VERSION ""

NS_ :

BS_:

BU_: APIM_CISM FCIMB RACM_RCIM DSP WCM DACMC HUD_ADV TRM_ITRM ACM GWM _delete APIM IPC GENERIC TSTR

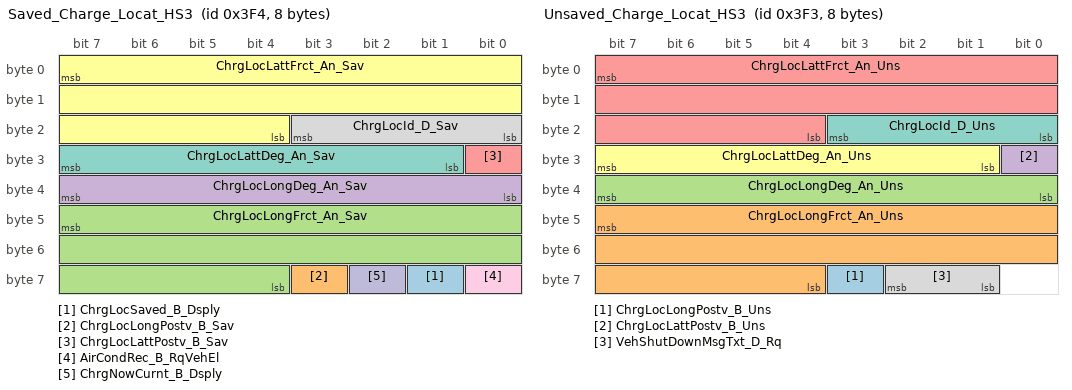
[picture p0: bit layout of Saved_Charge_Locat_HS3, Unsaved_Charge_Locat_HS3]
BO_ 1012 Saved_Charge_Locat_HS3: 8 GWM
 SG_ ChrgLocSaved_B_Dsply : 57|1@0+ (1,0) [0|1] "SED"  APIM,APIM_CISM
 SG_ ChrgLocLongPostv_B_Sav : 59|1@0+ (1,0) [0|1] "SED"  APIM_CISM,APIM
 SG_ ChrgLocLongFrct_An_Sav : 47|20@0+ (1E-006,0) [0|1.048575] "degrees"  APIM_CISM,APIM
 SG_ ChrgLocLongDeg_An_Sav : 39|8@0+ (1,0) [0|255] "degrees"  APIM_CISM,APIM
 SG_ ChrgLocLattPostv_B_Sav : 24|1@0+ (1,0) [0|1] "SED"  APIM_CISM,APIM
 SG_ ChrgLocLattFrct_An_Sav : 7|20@0+ (1E-006,0) [0|1.048575] "degrees"  APIM_CISM,APIM
 SG_ ChrgLocLattDeg_An_Sav : 31|7@0+ (1,0) [0|127] "unitless"  APIM_CISM,APIM
 SG_ ChrgLocId_D_Sav : 19|4@0+ (1,0) [0|15] "unitless"  APIM_CISM,APIM
 SG_ AirCondRec_B_RqVehEl : 56|1@0+ (1,0) [0|1] "SED"  GENERIC
 SG_ ChrgNowCurnt_B_Dsply : 58|1@0+ (1,0) [0|1] "SED"  IPC,APIM_CISM,APIM

BO_ 1011 Unsaved_Charge_Locat_HS3: 8 GWM
 SG_ ChrgLocLongPostv_B_Uns : 59|1@0+ (1,0) [0|1] "SED"  APIM_CISM,APIM
 SG_ ChrgLocLongFrct_An_Uns : 47|20@0+ (1E-006,0) [0|1.048575] "degrees"  APIM_CISM,APIM
 SG_ ChrgLocLongDeg_An_Uns : 39|8@0+ (1,0) [0|255] "degrees"  APIM_CISM,APIM
 SG_ ChrgLocLattPostv_B_Uns : 24|1@0+ (1,0) [0|1] "SED"  APIM_CISM,APIM
 SG_ ChrgLocLattFrct_An_Uns : 7|20@0+ (1E-006,0) [0|1.048575] "degrees"  APIM_CISM,APIM
 SG_ ChrgLocLattDeg_An_Uns : 31|7@0+ (1,0) [0|127] "unitless"  APIM_CISM,APIM
 SG_ ChrgLocId_D_Uns : 19|4@0+ (1,0) [0|15] "unitless"  APIM_CISM,APIM
 SG_ VehShutDownMsgTxt_D_Rq : 58|2@0+ (1,0) [0|3] "SED"  IPC

BO_ 533 APIM_Send_Signals_2: 8 APIM
 SG_ AutoEpbZoomView_B_Stat : 32|1@0+ (1,0) [0|1] "SED"  GWM
 SG_ ClrExitAsstEnbl_D_RqMnu : 60|2@0+ (1,0) [0|3] "SED"  GWM
 SG_ PaakMyKey_D_Rq : 7|2@0+ (1,0) [0|3] "SED"  GWM
 SG_ AutoEpbButtn_B_Stat : 19|1@0+ (1,0) [0|1] "SED"  GWM
 SG_ TrlrAidMde_D_Rq : 5|2@0+ (1,0) [0|3] "SED"  GWM
 SG_ TCU_Init_Actvtn_St : 1|2@0+ (1,0) [0|3] "SED"  GWM
 SG_ TCU_Final_Actvtn_St : 3|2@0+ (1,0) [0|3] "SED"  GWM
 SG_ DcacPw_D_Rq : 62|2@0+ (1,0) [0|3] "SED"  GWM
 SG_ DcacPwReset_B_Rq : 63|1@0+ (1,0) [0|1] "SED"  GWM
 SG_ LghtAmbDrvMde_D_Rq : 49|2@0+ (1,0) [0|3] "SED"  GWM
 SG_ OtaTrg_D_Stat : 41|2@0+ (1,0) [0|3] "SED"  GWM
 SG_ DcacPwLoButtn_B_Stat : 13|1@0+ (1,0) [0|1] "SED"  GWM
 SG_ DcacPwOffButtn_B_Stat : 12|1@0+ (1,0) [0|1] "SED"  GWM
 SG_ DcacPwHiButtn_B_Stat : 14|1@0+ (1,0) [0|1] "SED"  GWM
 SG_ DcacPwResetButtn_B_Stat : 11|1@0+ (1,0) [0|1] "SED"  GWM
 SG_ DcacPwButtn_B_Falt : 15|1@0+ (1,0) [0|1] "SED"  GWM
 SG_ OnbChrgGoTTouch_D_Rq : 43|2@0+ (1,0) [0|3] "SED"  GWM
 SG_ OnbChrgGoTPrcond_D_Rq : 34|2@0+ (1,0) [0|3] "SED"  GWM
 SG_ OnbChrgGoTOn_D_Rq : 25|2@0+ (1,0) [0|3] "SED"  GWM
 SG_ OnbChrgGoTMnte_D_Rq : 47|4@0+ (1,0) [0|15] "minute"  GWM
 SG_ OnbChrgGoTHr_T_Rq : 39|5@0+ (1,0) [0|29] "hour"  GWM
 SG_ OnbChrgGoTExtHtr_D_Rq : 27|2@0+ (1,0) [0|3] "SED"  GWM
 SG_ OnbChrgGoTElement_D_Rq : 31|4@0+ (1,0) [0|15] "Unitless"  GWM
 SG_ OnbChrgGoTDelete_B_Rq : 17|1@0+ (1,0) [0|1] "SED"  GWM
 SG_ OnbChrgClearAll_B_Rq : 18|1@0+ (1,0) [0|1] "SED"  GWM
 SG_ OnbChrgGoTUpdate_B_Rq : 16|1@0+ (1,0) [0|1] "SED"  GWM
 SG_ TrlrAlarmButtn_B_Stat : 50|1@0+ (1,0) [0|1] "SED"  TRM_ITRM,GWM
 SG_ DcacMdeButtn_B_Stat : 8|1@0+ (1,0) [0|1] "SED"  GWM
 SG_ DcacGfciTestBttn_B_Stat : 9|1@0+ (1,0) [0|1] "SED"  GWM
 SG_ TrlrBrkGain_No_Rq : 55|5@0+ (0.5,0) [0|15.5] "unitless"  TRM_ITRM,GWM
 SG_ TrlrHitch_D_RqMnu : 23|4@0+ (1,0) [0|15] "SED"  GWM
 SG_ DcacPwButtn_B_Stat : 10|1@0+ (1,0) [0|1] "SED"  GWM

BO_ 1184 APIM_TCU_Word_Rx_HS3: 8 GWM
 SG_ APIM_TCU_Word_Rx : 7|64@0+ (1,0) [0|1.84467440737096E+019] "unitless"  APIM_CISM,APIM

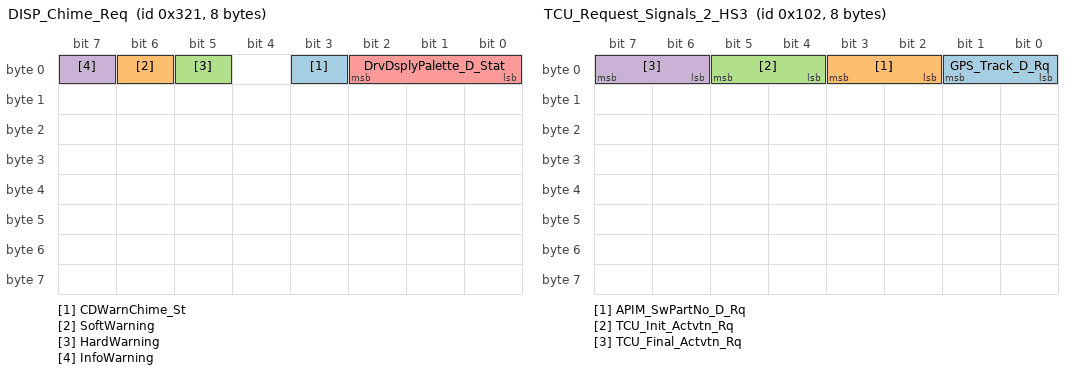
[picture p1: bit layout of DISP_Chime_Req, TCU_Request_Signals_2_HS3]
BO_ 801 DISP_Chime_Req: 8 APIM
 SG_ CDWarnChime_St : 3|1@0+ (1,0) [0|1] "SED"  IPC
 SG_ SoftWarning : 6|1@0+ (1,0) [0|1] "SED"  IPC
 SG_ HardWarning : 5|1@0+ (1,0) [0|1] "SED"  IPC
 SG_ InfoWarning : 7|1@0+ (1,0) [0|1] "SED"  IPC
 SG_ DrvDsplyPalette_D_Stat : 2|3@0+ (1,0) [0|7] "SED"  IPC

BO_ 878 Rear_Climate_Data2: 8 RACM_RCIM
 SG_ ClimtSyncRear2_B_Stat : 58|1@0+ (1,0) [0|1] "SED"  GENERIC,GWM
 SG_ ClimtStHeatRr2_B_Stat : 54|1@0+ (1,0) [0|1] "SED"  GENERIC,GWM
 SG_ ClimtStHeatRl2_B_Stat : 55|1@0+ (1,0) [0|1] "SED"  GENERIC,GWM
 SG_ ClimtStCoolRr2_B_Stat : 52|1@0+ (1,0) [0|1] "SED"  GENERIC,GWM
 SG_ ClimtStCoolRl2_B_Stat : 53|1@0+ (1,0) [0|1] "SED"  GENERIC,GWM
 SG_ ClimtSeatRr2_D_Rq : 39|8@0+ (1,0) [0|64] "SED"  GENERIC,GWM
 SG_ ClimtSeatRl2_D_Rq : 47|8@0+ (1,0) [0|64] "SED"  GENERIC,GWM
 SG_ ClimtRrTe3rd2_D_Stat : 51|2@0+ (1,0) [0|3] "SED"  GENERIC,GWM
 SG_ ClimtRrPw3rd2_B_Stat : 59|1@0+ (1,0) [0|1] "SED"  GENERIC,GWM
 SG_ ClimtRrPnl3rd2_B_Stat : 62|1@0+ (1,0) [0|1] "SED"  GENERIC,GWM
 SG_ ClimtRrPf3rd2_B_Stat : 63|1@0+ (1,0) [0|1] "SED"  GENERIC,GWM
 SG_ ClimtRrFlr3rd2_B_Stat : 61|1@0+ (1,0) [0|1] "SED"  GENERIC,GWM
 SG_ ClimtRrBlwr3rd2_D_Stat : 49|2@0+ (1,0) [0|3] "SED"  GENERIC,GWM
 SG_ ClimtRrAuto3rd2_B_Stat : 60|1@0+ (1,0) [0|1] "SED"  GENERIC,GWM
 SG_ ClimtRearView2_D_Stat : 57|2@0+ (1,0) [0|3] "SED"  GENERIC,GWM
 SG_ ClimtRearTe2_D_Stat : 11|2@0+ (1,0) [0|3] "SED"  GENERIC,GWM
 SG_ ClimtRearTe2_An_Actl : 7|9@0+ (1,0) [0|510] "degrees"  GENERIC,GWM
 SG_ ClimtRearPw2_B_Stat : 29|1@0+ (1,0) [0|1] "SED"  GENERIC,GWM
 SG_ ClimtRearPnlFlr2_B_Stat : 13|1@0+ (1,0) [0|1] "SED"  GENERIC,GWM
 SG_ ClimtRearPnl2_B_Stat : 14|1@0+ (1,0) [0|1] "SED"  GENERIC,GWM
 SG_ ClimtRearFlr2_B_Stat : 12|1@0+ (1,0) [0|1] "SED"  GENERIC,GWM
 SG_ ClimtRearBlwr2_D_Stat : 9|2@0+ (1,0) [0|3] "SED"  GENERIC,GWM
 SG_ ClimtRearBlwr2_An_Actl : 23|9@0+ (1,0) [0|510] "degrees"  GENERIC,GWM
 SG_ ClimtRearAuto2_B_Stat : 30|1@0+ (1,0) [0|1] "SED"  GENERIC,GWM

BO_ 258 TCU_Request_Signals_2_HS3: 8 GWM
 SG_ GPS_Track_D_Rq : 1|2@0+ (1,0) [0|3] "SED"  APIM_CISM,APIM
 SG_ APIM_SwPartNo_D_Rq : 3|2@0+ (1,0) [0|3] "SED"  APIM_CISM,APIM
 SG_ TCU_Init_Actvtn_Rq : 5|2@0+ (1,0) [0|3] "SED"  APIM_CISM,APIM
 SG_ TCU_Final_Actvtn_Rq : 7|2@0+ (1,0) [0|3] "SED"  APIM_CISM,APIM

BO_ 1192 APIM_TCU_Word_Tx: 8 APIM
 SG_ APIM_TCU_Word_Tx : 7|64@0+ (1,0) [0|1.84467440737096E+019] "unitless"  GWM

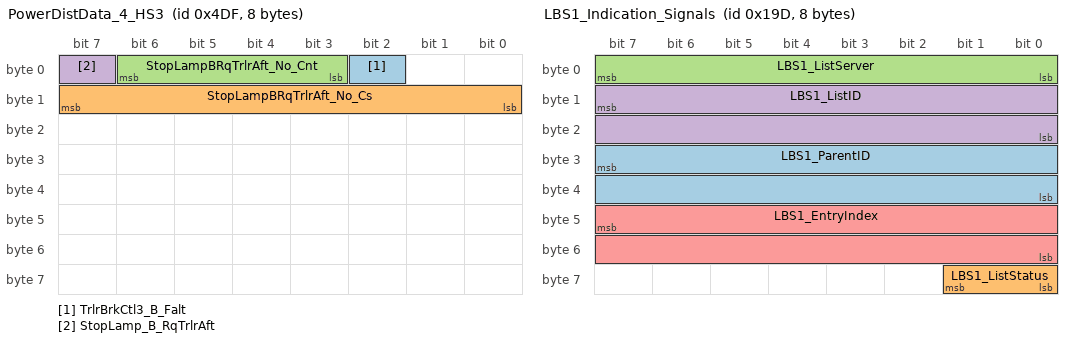
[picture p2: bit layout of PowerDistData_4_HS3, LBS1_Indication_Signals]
BO_ 1247 PowerDistData_4_HS3: 8 GWM
 SG_ TrlrBrkCtl3_B_Falt : 2|1@0+ (1,0) [0|1] "SED"  TRM_ITRM
 SG_ StopLampBRqTrlrAft_No_Cs : 15|8@0+ (1,0) [0|255] "Unitless"  TRM_ITRM
 SG_ StopLampBRqTrlrAft_No_Cnt : 6|4@0+ (1,0) [0|15] "Unitless"  TRM_ITRM
 SG_ StopLamp_B_RqTrlrAft : 7|1@0+ (1,0) [0|1] "SED"  TRM_ITRM

BO_ 413 LBS1_Indication_Signals: 8 APIM
 SG_ LBS1_ParentID : 31|16@0+ (1,0) [0|65535] "unitless"  RACM_RCIM,IPC
 SG_ LBS1_ListStatus : 57|2@0+ (1,0) [0|3] "SED"  IPC,RACM_RCIM
 SG_ LBS1_ListServer : 7|8@0+ (1,0) [0|255] "unitless"  IPC,RACM_RCIM
 SG_ LBS1_ListID : 15|16@0+ (1,0) [0|65535] "unitless"  IPC,RACM_RCIM
 SG_ LBS1_EntryIndex : 47|16@0+ (1,0) [0|65535] "unitless"  IPC,RACM_RCIM

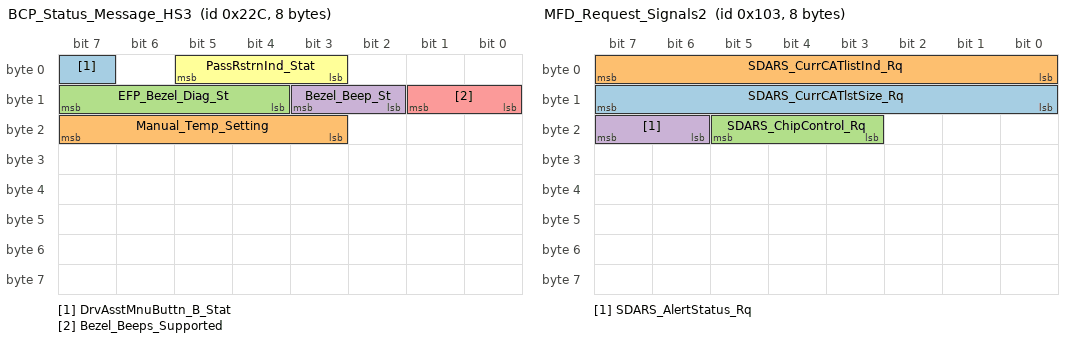
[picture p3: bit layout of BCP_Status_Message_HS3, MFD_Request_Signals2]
BO_ 556 BCP_Status_Message_HS3: 8 GWM
 SG_ DrvAsstMnuButtn_B_Stat : 7|1@0+ (1,0) [0|1] "SED"  APIM_CISM,APIM
 SG_ Manual_Temp_Setting : 23|5@0+ (1,0) [0|31] "SED"  APIM,APIM_CISM
 SG_ EFP_Bezel_Diag_St : 15|4@0+ (1,0) [0|15] "SED"  APIM,APIM_CISM
 SG_ Bezel_Beep_St : 11|2@0+ (1,0) [0|3] "SED"  APIM,APIM_CISM
 SG_ Bezel_Beeps_Supported : 9|2@0+ (1,0) [0|3] "SED"  APIM,APIM_CISM
 SG_ PassRstrnInd_Stat : 5|3@0+ (1,0) [0|7] "SED"  GENERIC

BO_ 259 MFD_Request_Signals2: 8 APIM
 SG_ SDARS_CurrCATlstSize_Rq : 15|8@0+ (1,0) [0|255] "unitless"  ACM
 SG_ SDARS_CurrCATlistInd_Rq : 7|8@0+ (1,0) [0|255] "unitless"  ACM
 SG_ SDARS_ChipControl_Rq : 21|3@0+ (1,0) [0|7] "SED"  ACM
 SG_ SDARS_AlertStatus_Rq : 23|2@0+ (1,0) [0|3] "SED"  ACM

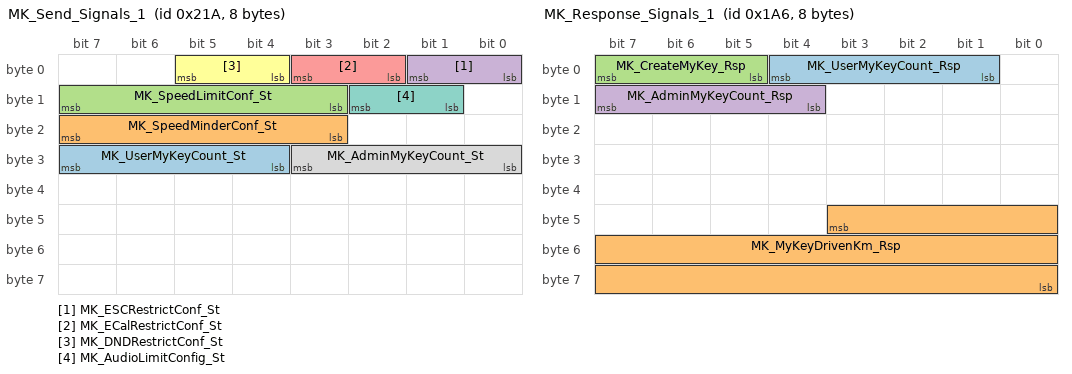
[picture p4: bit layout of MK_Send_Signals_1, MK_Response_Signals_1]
BO_ 538 MK_Send_Signals_1: 8 IPC
 SG_ MK_UserMyKeyCount_St : 31|4@0+ (1,0) [0|13] "SED"  APIM_CISM,APIM
 SG_ MK_SpeedMinderConf_St : 23|5@0+ (1,0) [0|31] "SED"  APIM_CISM,APIM
 SG_ MK_SpeedLimitConf_St : 15|5@0+ (1,0) [0|31] "SED"  APIM_CISM,APIM
 SG_ MK_ESCRestrictConf_St : 1|2@0+ (1,0) [0|3] "SED"  APIM_CISM,GENERIC
 SG_ MK_ECalRestrictConf_St : 3|2@0+ (1,0) [0|3] "SED"  APIM_CISM,APIM
 SG_ MK_DNDRestrictConf_St : 5|2@0+ (1,0) [0|3] "SED"  APIM_CISM,APIM
 SG_ MK_AudioLimitConfig_St : 10|2@0+ (1,0) [0|3] "SED"  APIM_CISM,APIM
 SG_ MK_AdminMyKeyCount_St : 27|4@0+ (1,0) [0|13] "SED"  APIM_CISM,APIM

BO_ 422 MK_Response_Signals_1: 8 IPC
 SG_ MK_UserMyKeyCount_Rsp : 4|4@0+ (1,0) [0|15] "SED"  APIM_CISM,APIM
 SG_ MK_MyKeyDrivenKm_Rsp : 43|20@0+ (1,0) [0|1048575] "km"  APIM_CISM,APIM
 SG_ MK_CreateMyKey_Rsp : 7|3@0+ (1,0) [0|7] "SED"  APIM_CISM,APIM
 SG_ MK_AdminMyKeyCount_Rsp : 15|4@0+ (1,0) [0|15] "SED"  APIM_CISM,APIM

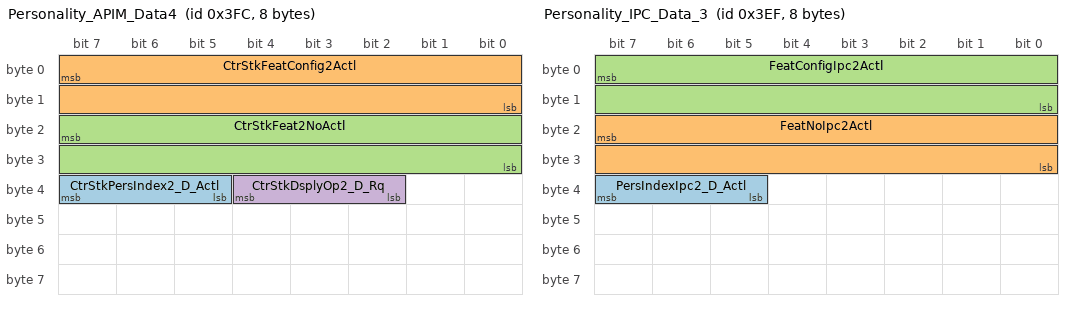
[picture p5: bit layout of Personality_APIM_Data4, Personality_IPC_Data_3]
BO_ 1020 Personality_APIM_Data4: 8 APIM
 SG_ CtrStkPersIndex2_D_Actl : 39|3@0+ (1,0) [0|7] "SED"  IPC
 SG_ CtrStkFeatConfig2Actl : 7|16@0+ (1,0) [0|65535] "Undefined"  IPC
 SG_ CtrStkFeat2NoActl : 23|16@0+ (1,0) [0|65535] "Undefined"  IPC
 SG_ CtrStkDsplyOp2_D_Rq : 36|3@0+ (1,0) [0|7] "SED"  IPC

BO_ 1007 Personality_IPC_Data_3: 8 IPC
 SG_ PersIndexIpc2_D_Actl : 39|3@0+ (1,0) [0|7] "SED"  APIM,APIM_CISM
 SG_ FeatNoIpc2Actl : 23|16@0+ (1,0) [0|65535] "Number"  APIM,APIM_CISM
 SG_ FeatConfigIpc2Actl : 7|16@0+ (1,0) [0|65535] "unitless"  APIM,APIM_CISM

BO_ 2008 TesterPhysicalResAPIM: 8 APIM
 SG_ TesterPhysicalResAPIM : 7|64@0+ (1,0) [0|1.84467E+019] "unitless"  TSTR

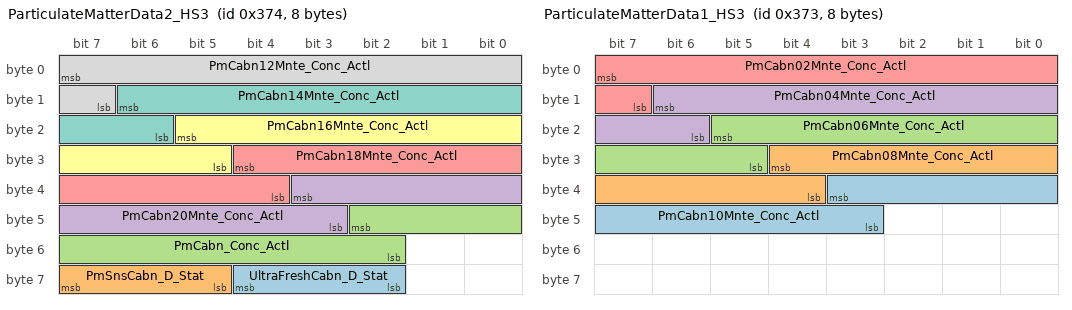
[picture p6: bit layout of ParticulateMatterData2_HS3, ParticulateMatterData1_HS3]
BO_ 884 ParticulateMatterData2_HS3: 8 GWM
 SG_ UltraFreshCabn_D_Stat : 60|3@0+ (1,0) [0|7] "SED"  APIM_CISM,GENERIC
 SG_ PmSnsCabn_D_Stat : 63|3@0+ (1,0) [0|7] "SED"  APIM_CISM,APIM,RACM_RCIM
 SG_ PmCabn_Conc_Actl : 42|9@0+ (1,0) [0|509] "parts/million"  APIM_CISM,APIM,RACM_RCIM
 SG_ PmCabn20Mnte_Conc_Actl : 35|9@0+ (1,0) [0|509] "parts/million"  RACM_RCIM,APIM_CISM,APIM
 SG_ PmCabn18Mnte_Conc_Actl : 28|9@0+ (1,0) [0|509] "parts/million"  RACM_RCIM,APIM_CISM,APIM
 SG_ PmCabn16Mnte_Conc_Actl : 21|9@0+ (1,0) [0|509] "parts/million"  RACM_RCIM,APIM_CISM,APIM
 SG_ PmCabn14Mnte_Conc_Actl : 14|9@0+ (1,0) [0|509] "parts/million"  RACM_RCIM,APIM_CISM,APIM
 SG_ PmCabn12Mnte_Conc_Actl : 7|9@0+ (1,0) [0|509] "parts/million"  RACM_RCIM,APIM_CISM,APIM

BO_ 883 ParticulateMatterData1_HS3: 8 GWM
 SG_ PmCabn10Mnte_Conc_Actl : 35|9@0+ (1,0) [0|509] "parts/million"  RACM_RCIM,APIM_CISM,APIM
 SG_ PmCabn08Mnte_Conc_Actl : 28|9@0+ (1,0) [0|509] "parts/million"  RACM_RCIM,APIM_CISM,APIM
 SG_ PmCabn06Mnte_Conc_Actl : 21|9@0+ (1,0) [0|509] "parts/million"  RACM_RCIM,APIM_CISM,APIM
 SG_ PmCabn04Mnte_Conc_Actl : 14|9@0+ (1,0) [0|509] "parts/million"  RACM_RCIM,APIM_CISM,APIM
 SG_ PmCabn02Mnte_Conc_Actl : 7|9@0+ (1,0) [0|509] "parts/million"  RACM_RCIM,APIM_CISM,APIM

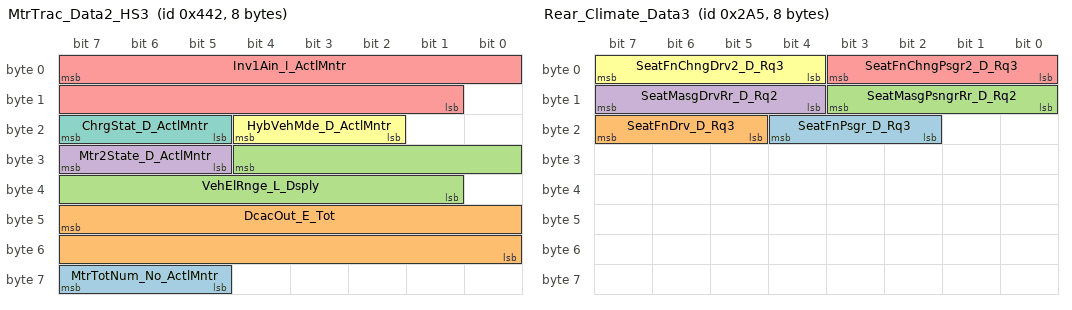
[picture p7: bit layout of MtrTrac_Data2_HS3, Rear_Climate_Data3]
BO_ 1090 MtrTrac_Data2_HS3: 8 GWM
 SG_ MtrTotNum_No_ActlMntr : 63|3@0+ (1,0) [0|7] "unitless"  GENERIC
 SG_ DcacOut_E_Tot : 47|16@0+ (20,0) [0|1310700] "watt*hour"  APIM,APIM_CISM
 SG_ VehElRnge_L_Dsply : 28|12@0+ (0.1,0) [0|409.3] "kilometer"  APIM_CISM,APIM,HUD_ADV,IPC
 SG_ Mtr2State_D_ActlMntr : 31|3@0+ (1,0) [0|7] "SED" Vector__XXX
 SG_ Inv1Ain_I_ActlMntr : 7|15@0+ (0.1,-1000) [-1000|2276.5] "ampere"  GENERIC
 SG_ HybVehMde_D_ActlMntr : 20|3@0+ (1,0) [0|7] "SED"  GENERIC
 SG_ ChrgStat_D_ActlMntr : 23|3@0+ (1,0) [0|7] "SED"  GENERIC

BO_ 677 Rear_Climate_Data3: 8 RACM_RCIM
 SG_ SeatFnPsgr_D_Rq3 : 20|3@0+ (1,0) [0|7] "SED"  GWM
 SG_ SeatFnDrv_D_Rq3 : 23|3@0+ (1,0) [0|7] "SED"  GWM
 SG_ SeatMasgPsngrRr_D_Rq2 : 11|4@0+ (1,0) [0|15] "SED"  GWM
 SG_ SeatMasgDrvRr_D_Rq2 : 15|4@0+ (1,0) [0|15] "SED"  GWM
 SG_ SeatFnChngPsgr2_D_Rq3 : 3|4@0+ (1,0) [0|15] "SED"  GWM
 SG_ SeatFnChngDrv2_D_Rq3 : 7|4@0+ (1,0) [0|15] "SED"  GWM

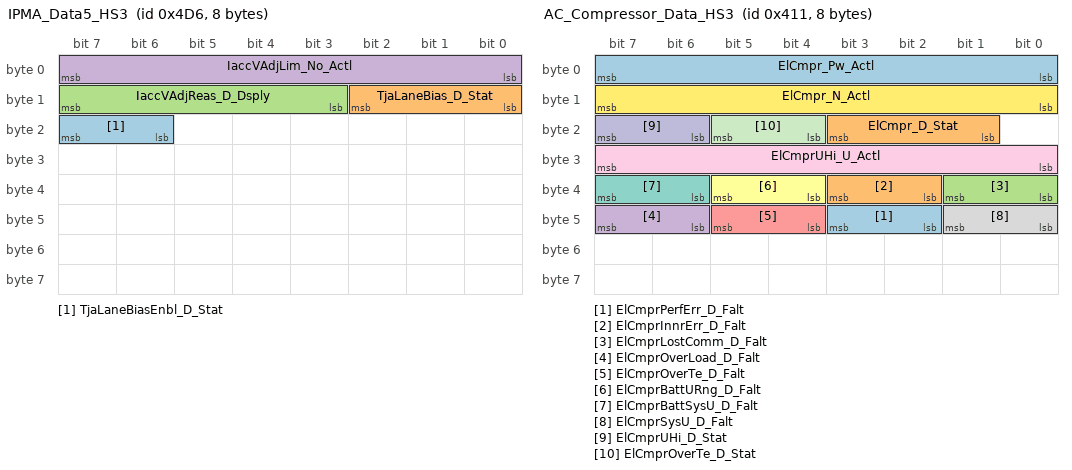
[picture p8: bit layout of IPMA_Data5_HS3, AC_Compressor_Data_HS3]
BO_ 1238 IPMA_Data5_HS3: 8 GWM
 SG_ TjaLaneBiasEnbl_D_Stat : 23|2@0+ (1,0) [0|3] "SED"  APIM,APIM_CISM
 SG_ TjaLaneBias_D_Stat : 10|3@0+ (1,0) [0|7] "SED"  IPC
 SG_ IaccVAdjReas_D_Dsply : 15|5@0+ (1,0) [0|31] "SED"  APIM,APIM_CISM,IPC
 SG_ IaccVAdjLim_No_Actl : 7|8@0+ (1,0) [0|255] "unitless"  APIM,APIM_CISM,IPC

BO_ 1041 AC_Compressor_Data_HS3: 8 GWM
 SG_ ElCmprPerfErr_D_Falt : 43|2@0+ (1,0) [0|3] "SED" Vector__XXX
 SG_ ElCmprInnrErr_D_Falt : 35|2@0+ (1,0) [0|3] "SED" Vector__XXX
 SG_ ElCmprLostComm_D_Falt : 33|2@0+ (1,0) [0|3] "SED" Vector__XXX
 SG_ ElCmprOverLoad_D_Falt : 47|2@0+ (1,0) [0|3] "SED" Vector__XXX
 SG_ ElCmprOverTe_D_Falt : 45|2@0+ (1,0) [0|3] "SED" Vector__XXX
 SG_ ElCmprBattURng_D_Falt : 37|2@0+ (1,0) [0|3] "SED" Vector__XXX
 SG_ ElCmprBattSysU_D_Falt : 39|2@0+ (1,0) [0|3] "SED" Vector__XXX
 SG_ ElCmprSysU_D_Falt : 41|2@0+ (1,0) [0|3] "SED" Vector__XXX
 SG_ ElCmprUHi_U_Actl : 31|8@0+ (2,0) [0|510] "volt" Vector__XXX
 SG_ ElCmprUHi_D_Stat : 23|2@0+ (1,0) [0|3] "SED" Vector__XXX
 SG_ ElCmprOverTe_D_Stat : 21|2@0+ (1,0) [0|3] "SED" Vector__XXX
 SG_ ElCmpr_N_Actl : 15|8@0+ (50,0) [0|12700] "RPM"  WCM
 SG_ ElCmpr_Pw_Actl : 7|8@0+ (40,0) [0|10160] "watts" Vector__XXX
 SG_ ElCmpr_D_Stat : 19|3@0+ (1,0) [0|7] "SED" Vector__XXX

BO_ 2609971416 OTAPhysGWM_ECGtoWCM: 8 GWM
 SG_ OTAPhysGWM_ECGtoWCM : 7|29@0+ (1,0) [0|536870911] "unitless"  WCM

BO_ 2610126912 OTAPhysWCMtoGWM_ECG: 8 WCM
 SG_ OTAPhysWCMtoGWM_ECG : 7|29@0+ (1,0) [0|536870911] "unitless"  GWM

BO_ 2611019992 PARSEDPhysGWM_ECGtoWCM: 8 GWM
 SG_ PARSEDPhysGWM_ECGtoWCM : 7|29@0+ (1,0) [0|536870911] "unitless"  WCM

BO_ 2611175488 PARSEDPhysWCMtoGWM_ECG: 8 WCM
 SG_ PARSEDPhysWCMtoGWM_ECG : 7|29@0+ (1,0) [0|536870911] "unitless"  GWM

BO_ 2612068568 PARSEDPushFcGWM_ECGtoWCM: 8 GWM
 SG_ PARSEDPushFcGWM_ECGtoWCM : 7|29@0+ (1,0) [0|536870911] "unitless"  WCM

BO_ 2612224064 PARSEDPushWCMtoGWM_ECG: 8 WCM
 SG_ PARSEDPushWCMtoGWM_ECG : 7|29@0+ (1,0) [0|536870911] "unitless"  GWM

BO_ 557 DSPAMP_Send_Signals_2: 8 DSP
 SG_ AudioToneTouchY_D_Stat : 15|8@0+ (1,0) [0|255] "SED"  APIM_CISM,APIM
 SG_ AudioToneTouchX_D_Stat : 7|8@0+ (1,0) [0|255] "SED"  APIM_CISM,APIM
 SG_ AudioToneTouch_D_Stat : 23|2@0+ (1,0) [0|3] "SED"  APIM_CISM,APIM

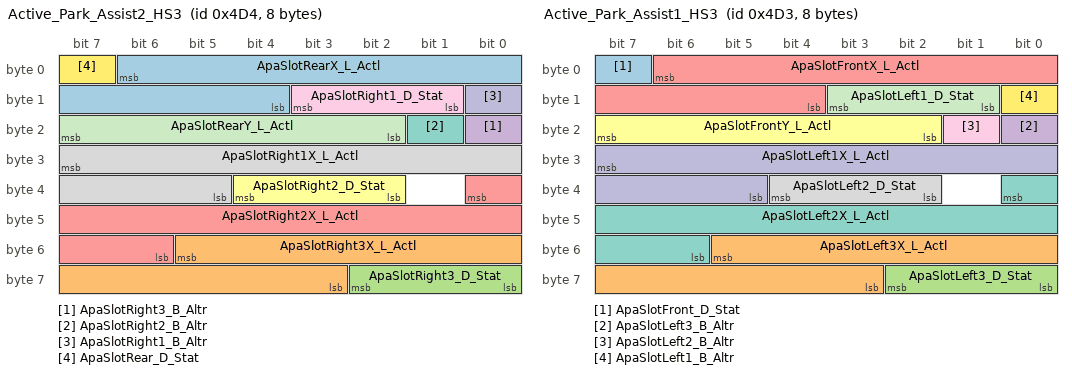
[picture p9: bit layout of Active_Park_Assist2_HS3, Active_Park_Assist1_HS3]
BO_ 1236 Active_Park_Assist2_HS3: 8 GWM
 SG_ ApaSlotRearX_L_Actl : 6|11@0+ (0.02,-20.96) [-20.96|19.98] "meter"  APIM_CISM,APIM
 SG_ ApaSlotRight3X_L_Actl : 53|11@0+ (0.02,-20.96) [-20.96|19.98] "meter"  APIM_CISM,APIM
 SG_ ApaSlotRight3_D_Stat : 58|3@0+ (1,0) [0|7] "SED"  APIM_CISM,APIM
 SG_ ApaSlotRight3_B_Altr : 16|1@0+ (1,0) [0|1] "SED"  APIM_CISM,APIM
 SG_ ApaSlotRight2X_L_Actl : 32|11@0+ (0.02,-20.96) [-20.96|19.98] "meter"  APIM_CISM,APIM
 SG_ ApaSlotRight2_D_Stat : 36|3@0+ (1,0) [0|7] "SED"  APIM_CISM,APIM
 SG_ ApaSlotRight2_B_Altr : 17|1@0+ (1,0) [0|1] "SED"  APIM_CISM,APIM
 SG_ ApaSlotRight1X_L_Actl : 31|11@0+ (0.02,-20.96) [-20.96|19.98] "meter"  APIM_CISM,APIM
 SG_ ApaSlotRight1_D_Stat : 11|3@0+ (1,0) [0|7] "SED"  APIM_CISM,APIM
 SG_ ApaSlotRight1_B_Altr : 8|1@0+ (1,0) [0|1] "SED"  APIM_CISM,APIM
 SG_ ApaSlotRearY_L_Actl : 23|6@0+ (0.2,-6.4) [-6.4|6.2] "meter"  APIM_CISM,APIM
 SG_ ApaSlotRear_D_Stat : 7|1@0+ (1,0) [0|1] "SED"  APIM_CISM,APIM

BO_ 1235 Active_Park_Assist1_HS3: 8 GWM
 SG_ ApaSlotFront_D_Stat : 7|1@0+ (1,0) [0|1] "SED"  APIM_CISM,APIM
 SG_ ApaSlotLeft3X_L_Actl : 53|11@0+ (0.02,-20.96) [-20.96|19.98] "meter"  APIM_CISM,APIM
 SG_ ApaSlotLeft3_D_Stat : 58|3@0+ (1,0) [0|7] "SED"  APIM_CISM,APIM
 SG_ ApaSlotLeft3_B_Altr : 16|1@0+ (1,0) [0|1] "SED"  APIM_CISM,APIM
 SG_ ApaSlotFrontX_L_Actl : 6|11@0+ (0.02,-20.96) [-20.96|19.98] "meter"  APIM_CISM,APIM
 SG_ ApaSlotFrontY_L_Actl : 23|6@0+ (0.2,-6.4) [-6.4|6.2] "meter"  APIM_CISM,APIM
 SG_ ApaSlotLeft2X_L_Actl : 32|11@0+ (0.02,-20.96) [-20.96|19.98] "meter"  APIM_CISM,APIM
 SG_ ApaSlotLeft2_D_Stat : 36|3@0+ (1,0) [0|7] "SED"  APIM_CISM,APIM
 SG_ ApaSlotLeft2_B_Altr : 17|1@0+ (1,0) [0|1] "SED"  APIM_CISM,APIM
 SG_ ApaSlotLeft1X_L_Actl : 31|11@0+ (0.02,-20.96) [-20.96|19.98] "meter"  APIM_CISM,APIM
 SG_ ApaSlotLeft1_D_Stat : 11|3@0+ (1,0) [0|7] "SED"  APIM_CISM,APIM
 SG_ ApaSlotLeft1_B_Altr : 8|1@0+ (1,0) [0|1] "SED"  APIM_CISM,APIM

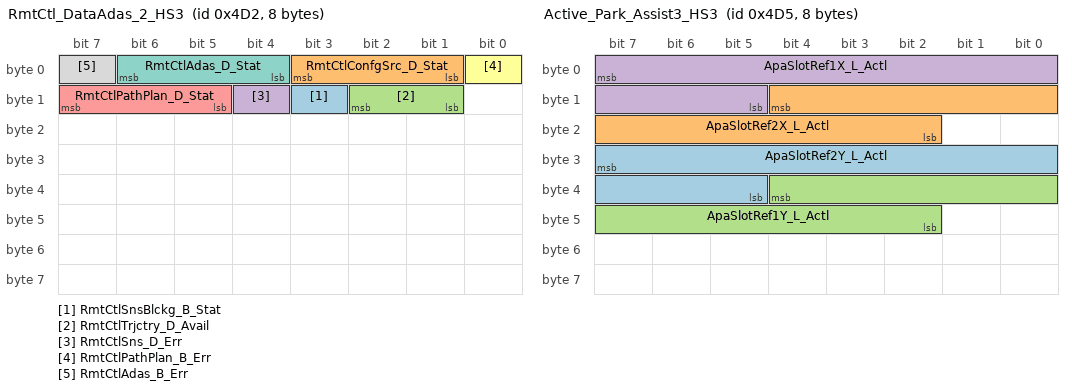
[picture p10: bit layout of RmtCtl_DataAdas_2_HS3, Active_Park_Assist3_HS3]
BO_ 1234 RmtCtl_DataAdas_2_HS3: 8 GWM
 SG_ RmtCtlSnsBlckg_B_Stat : 11|1@0+ (1,0) [0|1] "SED"  GENERIC
 SG_ RmtCtlConfgSrc_D_Stat : 3|3@0+ (1,0) [0|7] "SED"  GENERIC
 SG_ RmtCtlTrjctry_D_Avail : 10|2@0+ (1,0) [0|3] "SED"  GENERIC
 SG_ RmtCtlSns_D_Err : 12|1@0+ (1,0) [0|1] "SED"  GENERIC
 SG_ RmtCtlPathPlan_D_Stat : 15|3@0+ (1,0) [0|7] "SED"  GENERIC
 SG_ RmtCtlPathPlan_B_Err : 0|1@0+ (1,0) [0|1] "SED"  GENERIC
 SG_ RmtCtlAdas_D_Stat : 6|3@0+ (1,0) [0|7] "SED"  GENERIC
 SG_ RmtCtlAdas_B_Err : 7|1@0+ (1,0) [0|1] "SED"  GENERIC

BO_ 1237 Active_Park_Assist3_HS3: 8 GWM
 SG_ ApaSlotRef2Y_L_Actl : 31|11@0+ (0.02,-20.96) [-20.96|19.98] "meter"  APIM_CISM,APIM
 SG_ ApaSlotRef2X_L_Actl : 12|11@0+ (0.02,-20.96) [-20.96|19.98] "meter"  APIM_CISM,APIM
 SG_ ApaSlotRef1Y_L_Actl : 36|11@0+ (0.02,-20.96) [-20.96|19.98] "meter"  APIM_CISM,APIM
 SG_ ApaSlotRef1X_L_Actl : 7|11@0+ (0.02,-20.96) [-20.96|19.98] "meter"  APIM_CISM,APIM

BO_ 976 VehCharacteristicSet2_HS3: 8 GWM
 SG_ VehLong2_A_Actl_UB : 34|1@0+ (1,0) [0|1] "SED"  APIM_CISM,ACM
 SG_ VehLong2_A_Actl : 52|13@0+ (0.01,-40) [-40|41.89] "m/s^2"  APIM_CISM,ACM

BO_ 715 SSPClnt_SSPSrv_WORD_Rx: 8 APIM
 SG_ RDISP_SSP_WORD_Rx : 7|64@0+ (1,0) [0|1.84467440737096E+019] "unitless"  ACM

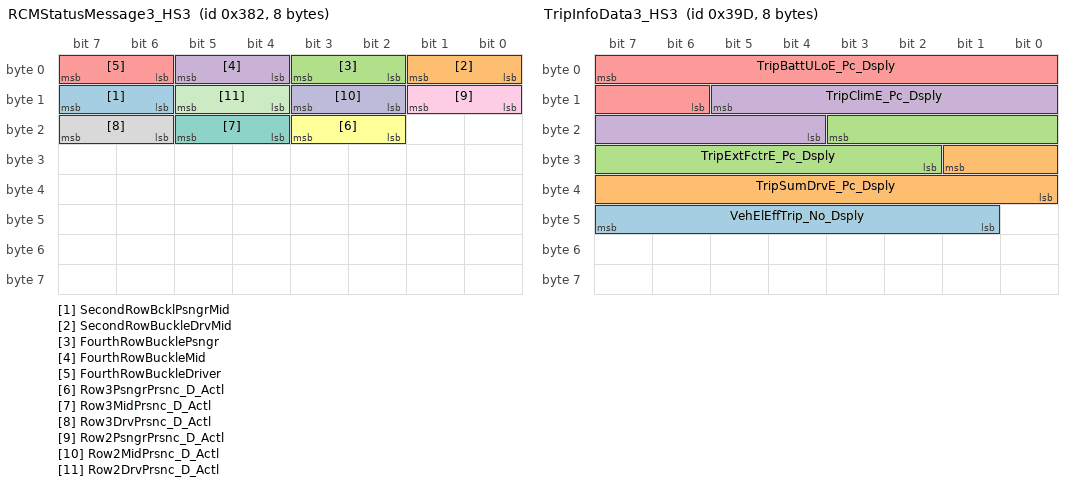
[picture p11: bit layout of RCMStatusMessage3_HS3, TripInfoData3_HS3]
BO_ 898 RCMStatusMessage3_HS3: 8 GWM
 SG_ SecondRowBcklPsngrMid : 15|2@0+ (1,0) [0|3] "SED"  IPC
 SG_ SecondRowBuckleDrvMid : 1|2@0+ (1,0) [0|3] "SED"  IPC
 SG_ FourthRowBucklePsngr : 3|2@0+ (1,0) [0|3] "SED"  IPC
 SG_ FourthRowBuckleMid : 5|2@0+ (1,0) [0|3] "SED"  IPC
 SG_ FourthRowBuckleDriver : 7|2@0+ (1,0) [0|3] "SED"  IPC
 SG_ Row3PsngrPrsnc_D_Actl : 19|2@0+ (1,0) [0|3] "SED"  IPC,APIM
 SG_ Row3MidPrsnc_D_Actl : 21|2@0+ (1,0) [0|3] "SED"  IPC,APIM
 SG_ Row3DrvPrsnc_D_Actl : 23|2@0+ (1,0) [0|3] "SED"  IPC,APIM
 SG_ Row2PsngrPrsnc_D_Actl : 9|2@0+ (1,0) [0|3] "SED"  IPC,APIM
 SG_ Row2MidPrsnc_D_Actl : 11|2@0+ (1,0) [0|3] "SED"  IPC,APIM
 SG_ Row2DrvPrsnc_D_Actl : 13|2@0+ (1,0) [0|3] "SED"  IPC,APIM

BO_ 925 TripInfoData3_HS3: 8 GWM
 SG_ VehElEffTrip_No_Dsply : 47|7@0+ (10,-100) [-100|1150] "wattHr/km"  APIM,IPC,APIM_CISM
 SG_ TripSumDrvE_Pc_Dsply : 25|10@0+ (0.1,0) [0|102.1] "percent"  APIM_CISM,APIM,IPC
 SG_ TripExtFctrE_Pc_Dsply : 19|10@0+ (0.1,0) [0|102.1] "percent"  APIM_CISM,APIM,IPC
 SG_ TripClimE_Pc_Dsply : 13|10@0+ (0.1,0) [0|102.1] "percent"  APIM_CISM,APIM,IPC
 SG_ TripBattULoE_Pc_Dsply : 7|10@0+ (0.1,0) [0|102.1] "percent"  APIM_CISM,APIM,IPC

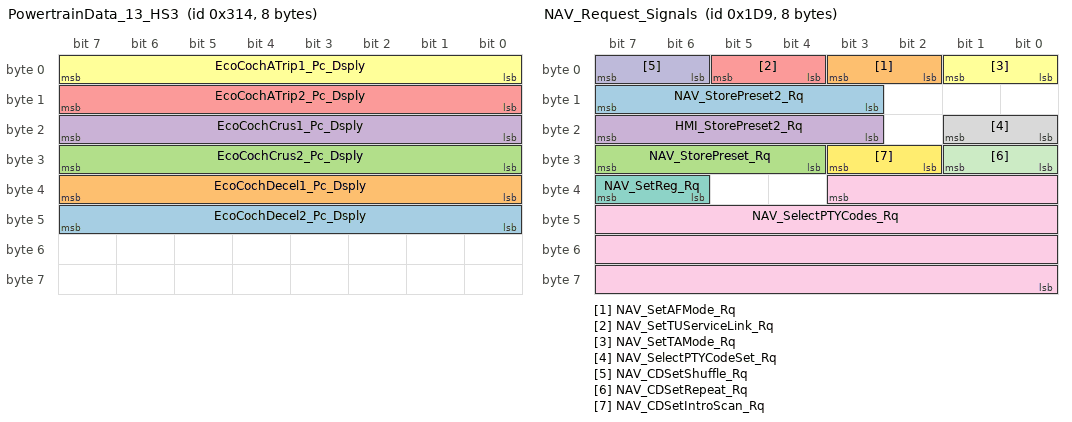
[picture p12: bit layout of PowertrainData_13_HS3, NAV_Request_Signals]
BO_ 788 PowertrainData_13_HS3: 8 GWM
 SG_ EcoCochDecel2_Pc_Dsply : 47|8@0+ (0.392157,0) [0|100.000035] "percent"  APIM_CISM,APIM
 SG_ EcoCochDecel1_Pc_Dsply : 39|8@0+ (0.392157,0) [0|100.000035] "percent"  APIM_CISM,APIM
 SG_ EcoCochCrus2_Pc_Dsply : 31|8@0+ (0.392157,0) [0|100.000035] "percent"  APIM_CISM,APIM
 SG_ EcoCochCrus1_Pc_Dsply : 23|8@0+ (0.392157,0) [0|100.000035] "percent"  APIM_CISM,APIM
 SG_ EcoCochATrip2_Pc_Dsply : 15|8@0+ (0.392157,0) [0|100.000035] "percent"  APIM_CISM,APIM
 SG_ EcoCochATrip1_Pc_Dsply : 7|8@0+ (0.392157,0) [0|100.000035] "percent"  APIM_CISM,APIM

BO_ 473 NAV_Request_Signals: 8 APIM
 SG_ NAV_StorePreset2_Rq : 15|5@0+ (1,0) [0|31] "SED"  ACM
 SG_ NAV_SetAFMode_Rq : 3|2@0+ (1,0) [0|3] "SED"  ACM,GENERIC
 SG_ NAV_StorePreset_Rq : 31|4@0+ (1,0) [0|15] "SED"  ACM,GENERIC
 SG_ HMI_StorePreset2_Rq : 23|5@0+ (1,0) [0|31] "SED"  ACM
 SG_ NAV_SetTUServiceLink_Rq : 5|2@0+ (1,0) [0|3] "SED"  ACM
 SG_ NAV_SetTAMode_Rq : 1|2@0+ (1,0) [0|3] "SED"  ACM
 SG_ NAV_SetReg_Rq : 39|2@0+ (1,0) [0|3] "SED"  ACM
 SG_ NAV_SelectPTYCodeSet_Rq : 17|2@0+ (1,0) [0|3] "SED"  ACM
 SG_ NAV_SelectPTYCodes_Rq : 35|28@0+ (1,0) [0|268435455] "unitless"  ACM
 SG_ NAV_CDSetShuffle_Rq : 7|2@0+ (1,0) [0|3] "SED"  ACM
 SG_ NAV_CDSetRepeat_Rq : 25|2@0+ (1,0) [0|3] "SED"  ACM
 SG_ NAV_CDSetIntroScan_Rq : 27|2@0+ (1,0) [0|3] "SED"  ACM

BO_ 2000 TesterPhysicalReqAPIM: 8 TSTR
 SG_ TesterPhysicalReqAPIM : 7|64@0+ (1,0) [0|1.84467E+019] "unitless"  APIM,APIM_CISM

BO_ 810 ECG_Data_HS3: 8 GWM
 SG_ ExtLghtDsply_B_StatArb : 7|1@0+ (1,0) [0|1] "SED"  APIM_CISM,APIM
 SG_ OneTEditActv_B_RqCld : 32|1@0+ (1,0) [0|1] "SED"  APIM_CISM,APIM

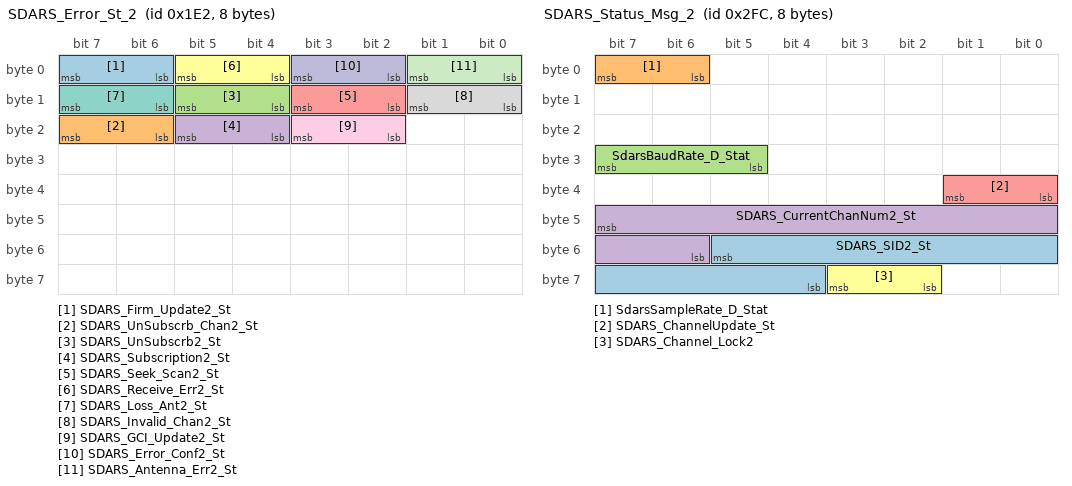
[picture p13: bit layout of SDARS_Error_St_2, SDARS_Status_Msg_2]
BO_ 482 SDARS_Error_St_2: 8 APIM
 SG_ SDARS_Firm_Update2_St : 7|2@0+ (1,0) [0|3] "SED"  RACM_RCIM,HUD_ADV,IPC
 SG_ SDARS_UnSubscrb_Chan2_St : 23|2@0+ (1,0) [0|3] "SED"  RACM_RCIM,HUD_ADV,IPC
 SG_ SDARS_UnSubscrb2_St : 13|2@0+ (1,0) [0|3] "SED"  RACM_RCIM,HUD_ADV,IPC
 SG_ SDARS_Subscription2_St : 21|2@0+ (1,0) [0|3] "SED"  RACM_RCIM,HUD_ADV,IPC
 SG_ SDARS_Seek_Scan2_St : 11|2@0+ (1,0) [0|3] "SED"  RACM_RCIM,HUD_ADV,IPC
 SG_ SDARS_Receive_Err2_St : 5|2@0+ (1,0) [0|3] "SED"  RACM_RCIM,HUD_ADV,IPC
 SG_ SDARS_Loss_Ant2_St : 15|2@0+ (1,0) [0|3] "SED"  RACM_RCIM,HUD_ADV,IPC
 SG_ SDARS_Invalid_Chan2_St : 9|2@0+ (1,0) [0|3] "SED"  RACM_RCIM,HUD_ADV,IPC
 SG_ SDARS_GCI_Update2_St : 19|2@0+ (1,0) [0|3] "SED"  RACM_RCIM,HUD_ADV,IPC
 SG_ SDARS_Error_Conf2_St : 3|2@0+ (1,0) [0|3] "SED"  RACM_RCIM,HUD_ADV,IPC
 SG_ SDARS_Antenna_Err2_St : 1|2@0+ (1,0) [0|3] "SED"  RACM_RCIM,HUD_ADV,IPC

BO_ 764 SDARS_Status_Msg_2: 8 APIM
 SG_ SDARS_SID2_St : 53|10@0+ (1,0) [0|1023] "unitless"  HUD_ADV,RACM_RCIM,ACM
 SG_ SdarsSampleRate_D_Stat : 7|2@0+ (1,0) [0|3] "SED"  ACM
 SG_ SdarsBaudRate_D_Stat : 31|3@0+ (1,0) [0|7] "SED"  ACM
 SG_ SDARS_CurrentChanNum2_St : 47|10@0+ (1,0) [0|1023] "unitless"  HUD_ADV,RACM_RCIM,IPC,ACM
 SG_ SDARS_ChannelUpdate_St : 33|2@0+ (1,0) [0|3] "SED"  ACM
 SG_ SDARS_Channel_Lock2 : 59|2@0+ (1,0) [0|3] "SED"  HUD_ADV,RACM_RCIM,ACM

BO_ 628 GWM_Send_Signals_9_HS3: 8 GWM
 SG_ CamraRearBttn_D_Stat_UB : 58|1@0+ (1,0) [0|1] "SED"  APIM_CISM,APIM
 SG_ CamraRearBttn_D_Stat : 59|1@0+ (1,0) [0|1] "SED"  APIM_CISM,APIM
 SG_ GearEngag_D_Actl_UB : 47|1@0+ (1,0) [0|1] "SED"  IPC
 SG_ GearEngag_D_Actl : 34|3@0+ (1,0) [0|7] "SED"  IPC
 SG_ RvltnMatchAllw_D_Stat_UB : 35|1@0+ (1,0) [0|1] "SED"  IPC
 SG_ RvltnMatchAllw_D_Stat : 37|2@0+ (1,0) [0|3] "SED"  IPC
 SG_ SeatScrnPsngrOn_B_Rq : 39|1@0+ (1,0) [0|1] "SED"  APIM_CISM,APIM
 SG_ SeatScrnPsngrOn_B_Rq_UB : 38|1@0+ (1,0) [0|1] "SED"  APIM_CISM,APIM
 SG_ CamraRearOn_B_RqBalrl_UB : 6|1@0+ (1,0) [0|1] "SED"  APIM_CISM,ACM,APIM
 SG_ CamraRearOn_B_RqBalrr_UB : 4|1@0+ (1,0) [0|1] "SED"  APIM_CISM,ACM,APIM
 SG_ CamraRearOn_B_RqBalrr : 5|1@0+ (1,0) [0|1] "SED"  APIM_CISM,ACM,APIM
 SG_ CamraRearOn_B_RqBalrl : 7|1@0+ (1,0) [0|1] "SED"  APIM_CISM,ACM,APIM
 SG_ PwFlwFuelDrv_D_Dsply : 50|3@0+ (1,0) [0|7] "SED"  APIM_CISM,APIM
 SG_ PwFlwFuelClimt_B_Dsply : 51|1@0+ (1,0) [0|1] "SED"  APIM_CISM,APIM
 SG_ PwFlwFuelBatt_B_Dsply : 53|1@0+ (1,0) [0|1] "SED"  APIM_CISM,APIM
 SG_ PwFlwBattGen_D_Dsply : 55|1@0+ (1,0) [0|1] "SED"  APIM_CISM,APIM
 SG_ PwFlwBattClimt_B_Dsply : 41|1@0+ (1,0) [0|1] "SED"  APIM_CISM,APIM
 SG_ PwFlwBatt_D_Dsply : 46|4@0+ (1,0) [0|15] "SED"  APIM_CISM,APIM
 SG_ PwFlwFuelDrv_D_Dsply_UB : 62|1@0+ (1,0) [0|1] "SED"  APIM_CISM,APIM
 SG_ PwFlwFuelClimt_B_Dsply_UB : 63|1@0+ (1,0) [0|1] "SED"  APIM_CISM,APIM
 SG_ PwFlwFuelBatt_B_Dsply_UB : 52|1@0+ (1,0) [0|1] "SED"  APIM_CISM,APIM
 SG_ PwFlwBattGen_D_Dsply_UB : 54|1@0+ (1,0) [0|1] "SED"  APIM_CISM,APIM
 SG_ PwFlwBattClimt_B_Dsply_UB : 40|1@0+ (1,0) [0|1] "SED"  APIM_CISM,APIM
 SG_ PwFlwBatt_D_Dsply_UB : 42|1@0+ (1,0) [0|1] "SED"  APIM_CISM,APIM
 SG_ TrailCtlMsgTxt_D_Rq : 3|4@0+ (1,0) [0|15] "SED"  IPC
 SG_ TrailCtlMsgTxt_D_Rq_UB : 15|1@0+ (1,0) [0|1] "SED"  IPC
 SG_ TrailCtl_D_Stat_UB : 20|1@0+ (1,0) [0|1] "SED"  APIM,APIM_CISM,IPC
 SG_ TrailCtl_D_Stat : 23|3@0+ (1,0) [0|7] "SED"  APIM,APIM_CISM,IPC
 SG_ Veh_V_DsplyTrailCtlSet : 14|6@0+ (0.5,0) [0|31] "unitless"  IPC
 SG_ Veh_V_DsplyTrailCtlSet_UB : 8|1@0+ (1,0) [0|1] "SED"  IPC
 SG_ SeatScrnDrvOn_B_Rq_UB : 17|1@0+ (1,0) [0|1] "SED"  APIM_CISM,APIM
 SG_ SeatScrnDrvOn_B_Rq : 18|1@0+ (1,0) [0|1] "SED"  APIM_CISM,APIM

BO_ 710 BEZEL_RDISP_WORD_Tx_HS3: 8 GWM
 SG_ BEZEL_RDISP_WORD_Tx : 7|64@0+ (1,0) [0|1.84467440737096E+019] "unitless"  APIM,APIM_CISM

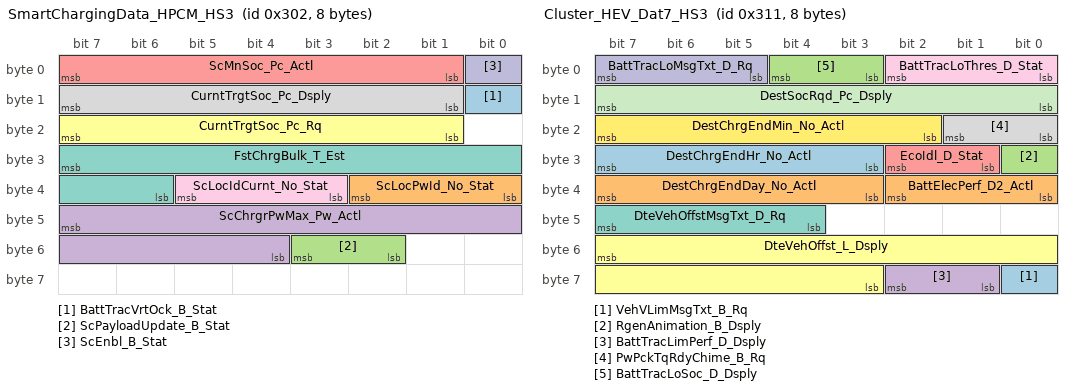
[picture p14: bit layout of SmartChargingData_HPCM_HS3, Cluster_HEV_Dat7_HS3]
BO_ 770 SmartChargingData_HPCM_HS3: 8 GWM
 SG_ BattTracVrtOck_B_Stat : 8|1@0+ (1,0) [0|1] "SED"  GENERIC
 SG_ ScLocPwId_No_Stat : 34|3@0+ (1,0) [0|7] "unitless"  GENERIC
 SG_ ScPayloadUpdate_B_Stat : 51|2@0+ (1,0) [0|3] "SED"  GENERIC
 SG_ ScChrgrPwMax_Pw_Actl : 47|12@0+ (50,0) [0|204700] "watts"  GENERIC
 SG_ ScMnSoc_Pc_Actl : 7|7@0+ (1,0) [0|127] "percent"  APIM_CISM,APIM
 SG_ CurntTrgtSoc_Pc_Rq : 23|7@0+ (1,0) [0|127] "percent"  GENERIC
 SG_ FstChrgBulk_T_Est : 31|10@0+ (1,0) [0|1023] "minute"  APIM_CISM,APIM,IPC
 SG_ CurntTrgtSoc_Pc_Dsply : 15|7@0+ (1,0) [0|127] "percent"  APIM_CISM,APIM,IPC
 SG_ ScLocIdCurnt_No_Stat : 37|3@0+ (1,0) [0|7] "unitless"  APIM_CISM,APIM
 SG_ ScEnbl_B_Stat : 0|1@0+ (1,0) [0|1] "SED"  APIM_CISM,APIM

BO_ 785 Cluster_HEV_Dat7_HS3: 8 GWM
 SG_ VehVLimMsgTxt_B_Rq : 56|1@0+ (1,0) [0|1] "SED"  IPC
 SG_ BattElecPerf_D2_Actl : 34|3@0+ (1,0) [0|7] "SED"  IPC
 SG_ RgenAnimation_B_Dsply : 24|1@0+ (1,0) [0|1] "SED"  IPC
 SG_ BattTracLimPerf_D_Dsply : 58|2@0+ (1,0) [0|3] "SED"  IPC
 SG_ EcoIdl_D_Stat : 26|2@0+ (1,0) [0|3] "SED"  APIM_CISM,APIM
 SG_ DteVehOffst_L_Dsply : 55|13@0+ (0.1,-400) [-400|418.9] "kilometer"  APIM_CISM,APIM,IPC
 SG_ DteVehOffstMsgTxt_D_Rq : 47|4@0+ (1,0) [0|15] "SED"  APIM_CISM,APIM,IPC
 SG_ PwPckTqRdyChime_B_Rq : 17|2@0+ (1,0) [0|3] "SED"  IPC
 SG_ BattTracLoThres_D_Stat : 2|3@0+ (1,0) [0|7] "SED"  APIM_CISM,APIM
 SG_ BattTracLoMsgTxt_D_Rq : 7|3@0+ (1,0) [0|7] "SED"  IPC
 SG_ DestSocRqd_Pc_Dsply : 15|8@0+ (0.5,0) [0|127.5] "percent"  APIM_CISM,APIM,IPC
 SG_ DestChrgEndMin_No_Actl : 23|6@0+ (1,0) [0|63] "Minutes"  APIM_CISM,APIM,IPC
 SG_ DestChrgEndHr_No_Actl : 31|5@0+ (1,0) [0|31] "Hours"  APIM_CISM,APIM,IPC
 SG_ DestChrgEndDay_No_Actl : 39|5@0+ (1,0) [1|31] "days"  APIM_CISM,APIM,IPC
 SG_ BattTracLoSoc_D_Dsply : 4|2@0+ (1,0) [0|3] "SED"  APIM_CISM,APIM,IPC

BO_ 1202 SDARS_VR_WORD_Rx: 8 APIM
 SG_ SDARS_VR_WORD_Rx : 7|64@0+ (1,0) [0|1.84467440737096E+019] "unitless"  ACM

BO_ 1210 SDARS_VR_WORD_Tx: 8 ACM
 SG_ SDARS_VR_WORD_Tx : 7|64@0+ (1,0) [0|1.84467440737096E+019] "unitless"  APIM

BO_ 391 ACU_Request_Signals_3: 8 ACM
 SG_ ACU_CtrlChimeChan_Rq : 7|2@0+ (1,0) [0|3] "SED"  DSP

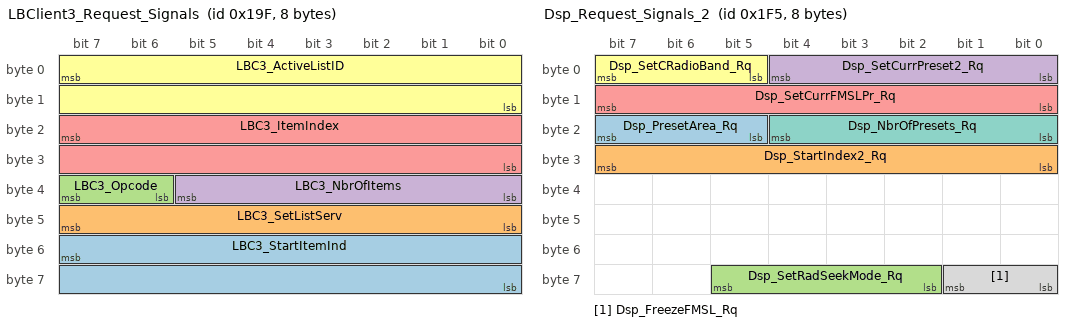
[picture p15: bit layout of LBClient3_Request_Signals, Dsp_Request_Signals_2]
BO_ 415 LBClient3_Request_Signals: 8 RACM_RCIM
 SG_ LBC3_StartItemInd : 55|16@0+ (1,0) [0|65535] "unitless"  APIM_CISM,APIM,ACM
 SG_ LBC3_SetListServ : 47|8@0+ (1,0) [0|255] "unitless"  APIM_CISM,APIM,ACM
 SG_ LBC3_Opcode : 39|2@0+ (1,0) [0|3] "SED"  APIM_CISM,APIM,ACM
 SG_ LBC3_NbrOfItems : 37|6@0+ (1,0) [0|63] "unitless"  APIM_CISM,ACM,APIM
 SG_ LBC3_ItemIndex : 23|16@0+ (1,0) [0|65535] "unitless"  APIM_CISM,ACM,APIM
 SG_ LBC3_ActiveListID : 7|16@0+ (1,0) [0|65535] "unitless"  APIM_CISM,APIM,ACM

BO_ 703 CONMP_MC_WORD_Rx: 8 IPC
 SG_ CONMP_MC_WORD_Rx : 7|64@0+ (1,0) [0|1.84467440737096E+019] "unitless"  APIM_CISM,APIM

BO_ 695 CONMP_MC_WORD_Tx: 8 APIM
 SG_ CONMP_MC_WORD_Tx : 7|64@0+ (1,0) [0|1.84467440737096E+019] "unitless"  IPC

BO_ 501 Dsp_Request_Signals_2: 8 APIM
 SG_ Dsp_PresetArea_Rq : 23|3@0+ (1,0) [0|7] "SED"  ACM
 SG_ Dsp_StartIndex2_Rq : 31|8@0+ (1,0) [0|255] "unitless"  ACM
 SG_ Dsp_SetRadSeekMode_Rq : 61|4@0+ (1,0) [0|15] "SED"  ACM
 SG_ Dsp_SetCurrPreset2_Rq : 4|5@0+ (1,0) [0|30] "SED"  ACM
 SG_ Dsp_SetCurrFMSLPr_Rq : 15|8@0+ (1,0) [0|254] "unitless"  ACM
 SG_ Dsp_SetCRadioBand_Rq : 7|3@0+ (1,0) [0|7] "SED"  ACM
 SG_ Dsp_NbrOfPresets_Rq : 20|5@0+ (1,0) [0|30] "unitless"  ACM
 SG_ Dsp_FreezeFMSL_Rq : 57|2@0+ (1,0) [0|3] "SED"  ACM

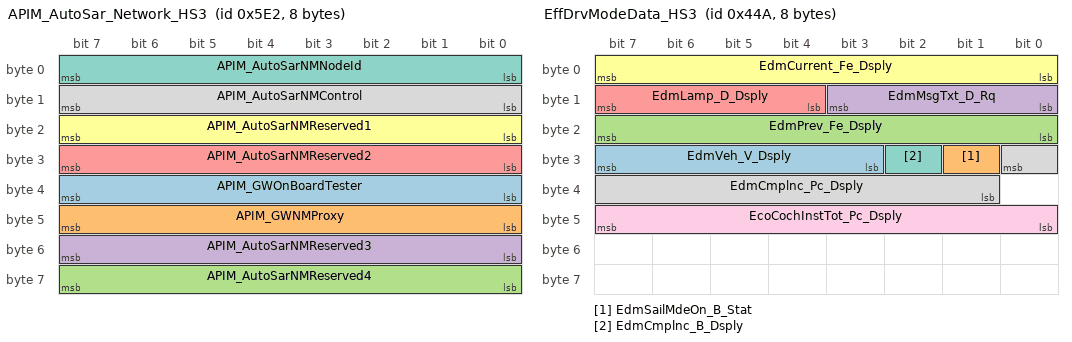
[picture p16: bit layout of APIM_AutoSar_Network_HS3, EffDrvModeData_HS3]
BO_ 1506 APIM_AutoSar_Network_HS3: 8 APIM
 SG_ APIM_GWOnBoardTester : 39|8@0+ (1,0) [0|255] "unitless"  HUD_ADV
 SG_ APIM_GWNMProxy : 47|8@0+ (1,0) [0|255] "unitless"  HUD_ADV
 SG_ APIM_AutoSarNMReserved4 : 63|8@0+ (1,0) [0|255] "unitless"  HUD_ADV
 SG_ APIM_AutoSarNMReserved3 : 55|8@0+ (1,0) [0|255] "unitless"  HUD_ADV
 SG_ APIM_AutoSarNMReserved2 : 31|8@0+ (1,0) [0|255] "unitless"  HUD_ADV
 SG_ APIM_AutoSarNMReserved1 : 23|8@0+ (1,0) [0|255] "unitless"  HUD_ADV
 SG_ APIM_AutoSarNMNodeId : 7|8@0+ (1,0) [0|255] "unitless"  HUD_ADV
 SG_ APIM_AutoSarNMControl : 15|8@0+ (1,0) [0|255] "unitless"  HUD_ADV

BO_ 651 TCU_Send_Signals_HS3: 8 GWM
 SG_ TelematicsSrvc_D_St : 47|3@0+ (1,0) [0|7] "SED"  APIM_CISM,ACM,APIM
 SG_ EmgcyCallMute_D_Stat : 39|3@0+ (1,0) [0|7] "SED"  APIM_CISM,ACM,APIM,DSP

BO_ 1098 EffDrvModeData_HS3: 8 GWM
 SG_ EdmVeh_V_Dsply : 31|5@0+ (5,0) [0|155] "km/h"  IPC
 SG_ EdmSailMdeOn_B_Stat : 25|1@0+ (1,0) [0|1] "SED"  IPC
 SG_ EdmPrev_Fe_Dsply : 23|8@0+ (0.1,0) [0|25.5] "litre/100km"  IPC
 SG_ EdmMsgTxt_D_Rq : 11|4@0+ (1,0) [0|15] "SED"  IPC
 SG_ EdmLamp_D_Dsply : 15|4@0+ (1,0) [0|15] "SED"  HUD_ADV,IPC
 SG_ EdmCurrent_Fe_Dsply : 7|8@0+ (0.1,0) [0|25.5] "litre/100km"  IPC
 SG_ EdmCmplnc_B_Dsply : 26|1@0+ (1,0) [0|1] "SED"  HUD_ADV,IPC
 SG_ EdmCmplnc_Pc_Dsply : 24|8@0+ (0.392157,0) [0|100.000035] "percent"  IPC
 SG_ EcoCochInstTot_Pc_Dsply : 47|8@0+ (0.392157,0) [0|100.000035] "percent"  IPC

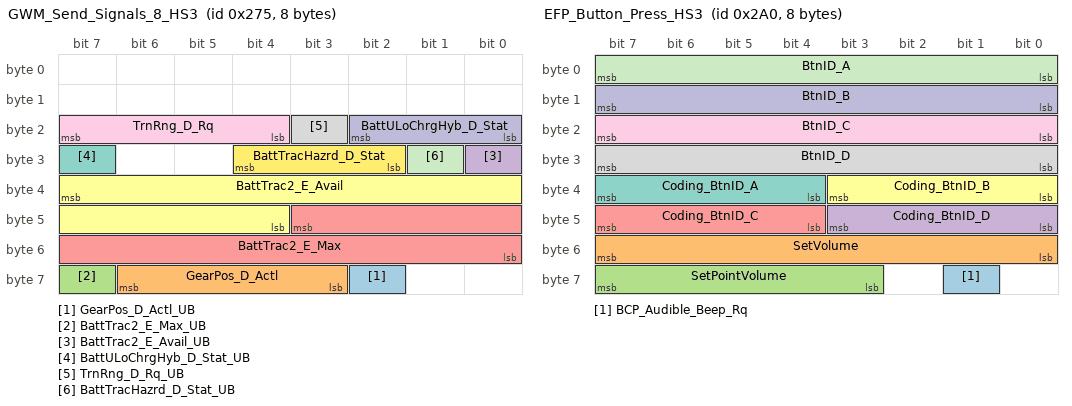
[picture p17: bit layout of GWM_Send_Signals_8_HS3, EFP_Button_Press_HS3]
BO_ 629 GWM_Send_Signals_8_HS3: 8 GWM
 SG_ GearPos_D_Actl_UB : 58|1@0+ (1,0) [0|1] "SED"  APIM,APIM_CISM
 SG_ GearPos_D_Actl : 62|4@0+ (1,0) [0|15] "SED"  APIM,APIM_CISM
 SG_ BattTrac2_E_Max_UB : 63|1@0+ (1,0) [0|1] "SED"  APIM_CISM,APIM
 SG_ BattTrac2_E_Avail_UB : 24|1@0+ (1,0) [0|1] "SED"  APIM_CISM,APIM
 SG_ BattTrac2_E_Max : 43|12@0+ (50,0) [0|204650] "watt*hour"  APIM_CISM,APIM
 SG_ BattTrac2_E_Avail : 39|12@0+ (50,0) [0|204650] "watt*hour"  APIM_CISM,APIM
 SG_ BattULoChrgHyb_D_Stat_UB : 31|1@0+ (1,0) [0|1] "SED"  IPC
 SG_ TrnRng_D_Rq_UB : 19|1@0+ (1,0) [0|1] "SED"  APIM,APIM_CISM
 SG_ TrnRng_D_Rq : 23|4@0+ (1,0) [0|15] "SED"  APIM,APIM_CISM
 SG_ BattULoChrgHyb_D_Stat : 18|3@0+ (1,0) [0|7] "SED"  IPC
 SG_ BattTracHazrd_D_Stat_UB : 25|1@0+ (1,0) [0|1] "SED"  IPC
 SG_ BattTracHazrd_D_Stat : 28|3@0+ (1,0) [0|7] "SED"  IPC

BO_ 718 BEZEL_RDISP_WORD_Rx: 8 APIM
 SG_ BEZEL_RDISP_WORD_Rx : 7|64@0+ (1,0) [0|1.84467440737096E+019] "unitless"  GWM

BO_ 672 EFP_Button_Press_HS3: 8 FCIMB
 SG_ BCP_Audible_Beep_Rq : 57|1@0+ (1,0) [0|1] "SED"  ACM,DSP,APIM_CISM
 SG_ SetVolume : 55|8@0+ (1,-30) [-30|30] "unitless"  DSP,APIM_CISM,ACM,APIM
 SG_ SetPointVolume : 63|5@0+ (1,0) [0|31] "unitless"  DSP,APIM_CISM,ACM,APIM
 SG_ Coding_BtnID_D : 43|4@0+ (1,0) [0|15] "SED"  APIM_CISM,ACM,APIM
 SG_ Coding_BtnID_C : 47|4@0+ (1,0) [0|15] "SED"  APIM_CISM,ACM,APIM
 SG_ Coding_BtnID_B : 35|4@0+ (1,0) [0|15] "SED"  APIM_CISM,ACM,APIM
 SG_ Coding_BtnID_A : 39|4@0+ (1,0) [0|15] "SED"  APIM_CISM,ACM,APIM
 SG_ BtnID_D : 31|8@0+ (1,0) [0|255] "unitless"  APIM_CISM,ACM,APIM
 SG_ BtnID_C : 23|8@0+ (1,0) [0|255] "unitless"  APIM_CISM,ACM,APIM
 SG_ BtnID_B : 15|8@0+ (1,0) [0|255] "unitless"  APIM_CISM,ACM,APIM
 SG_ BtnID_A : 7|8@0+ (1,0) [0|255] "unitless"  APIM_CISM,ACM,APIM

BO_ 1952 TesterPhysicalReqFCIMB: 8 TSTR
 SG_ TesterPhysicalReqFCIMB : 7|64@0+ (1,0) [0|1.84467E+019] "unitless"  FCIMB

BO_ 1960 TesterPhysicalResFCIMB: 8 FCIMB
 SG_ TesterPhysicalResFCIMB : 7|64@0+ (1,0) [0|1.84467E+019] "unitless"  TSTR

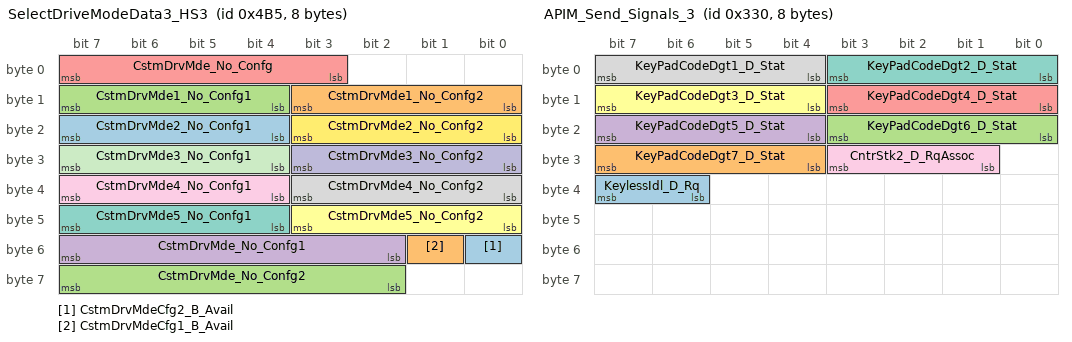
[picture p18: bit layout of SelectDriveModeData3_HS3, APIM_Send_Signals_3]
BO_ 1205 SelectDriveModeData3_HS3: 8 GWM
 SG_ CstmDrvMdeCfg2_B_Avail : 48|1@0+ (1,0) [0|1] "SED"  IPC
 SG_ CstmDrvMdeCfg1_B_Avail : 49|1@0+ (1,0) [0|1] "SED"  IPC
 SG_ CstmDrvMde_No_Confg2 : 63|6@0+ (1,0) [0|63] "unitless"  IPC
 SG_ CstmDrvMde_No_Confg1 : 55|6@0+ (1,0) [0|63] "unitless"  IPC
 SG_ CstmDrvMde_No_Confg : 7|5@0+ (1,0) [0|31] "unitless"  IPC
 SG_ CstmDrvMde5_No_Confg2 : 43|4@0+ (1,0) [0|15] "unitless"  IPC
 SG_ CstmDrvMde5_No_Confg1 : 47|4@0+ (1,0) [0|15] "unitless"  IPC
 SG_ CstmDrvMde4_No_Confg2 : 35|4@0+ (1,0) [0|15] "unitless"  IPC
 SG_ CstmDrvMde4_No_Confg1 : 39|4@0+ (1,0) [0|15] "unitless"  IPC
 SG_ CstmDrvMde3_No_Confg2 : 27|4@0+ (1,0) [0|15] "unitless"  IPC
 SG_ CstmDrvMde3_No_Confg1 : 31|4@0+ (1,0) [0|15] "unitless"  IPC
 SG_ CstmDrvMde2_No_Confg2 : 19|4@0+ (1,0) [0|15] "unitless"  IPC
 SG_ CstmDrvMde2_No_Confg1 : 23|4@0+ (1,0) [0|15] "unitless"  IPC
 SG_ CstmDrvMde1_No_Confg2 : 11|4@0+ (1,0) [0|15] "unitless"  IPC
 SG_ CstmDrvMde1_No_Confg1 : 15|4@0+ (1,0) [0|15] "unitless"  IPC

BO_ 1829 TesterPhysicalReqWCM: 8 TSTR
 SG_ TesterPhysicalReqWCM : 7|64@0+ (1,0) [0|1.84467E+019] "unitless"  WCM

BO_ 601 ECG_MC_WORD_Rx: 8 IPC
 SG_ ECG_MC_WORD_Rx : 7|64@0+ (1,0) [0|1.84467440737096E+019] "unitless"  GWM

BO_ 593 ECG_MC_WORD_Tx: 8 GWM
 SG_ ECG_MC_WORD_Tx : 7|64@0+ (1,0) [0|1.84467440737096E+019] "unitless"  IPC

BO_ 816 APIM_Send_Signals_3: 8 APIM
 SG_ KeylessIdl_D_Rq : 39|2@0+ (1,0) [0|3] "SED"  GWM
 SG_ KeyPadCodeDgt7_D_Stat : 31|4@0+ (1,0) [0|15] "SED"  GWM
 SG_ KeyPadCodeDgt6_D_Stat : 19|4@0+ (1,0) [0|15] "SED"  GWM
 SG_ KeyPadCodeDgt5_D_Stat : 23|4@0+ (1,0) [0|15] "SED"  GWM
 SG_ KeyPadCodeDgt4_D_Stat : 11|4@0+ (1,0) [0|15] "SED"  GWM
 SG_ KeyPadCodeDgt3_D_Stat : 15|4@0+ (1,0) [0|15] "SED"  GWM
 SG_ KeyPadCodeDgt2_D_Stat : 3|4@0+ (1,0) [0|15] "SED"  GWM
 SG_ KeyPadCodeDgt1_D_Stat : 7|4@0+ (1,0) [0|15] "SED"  GWM
 SG_ CntrStk2_D_RqAssoc : 27|3@0+ (1,0) [0|7] "SED"  GWM

BO_ 636 TCU_Send_Signals_3_HS3: 8 GWM
 SG_ WifiHtsptFqBand_D_Stat : 60|2@0+ (1,0) [0|3] "SED"  ACM,APIM,APIM_CISM
 SG_ WifiHtspt_D_Falt : 51|4@0+ (1,0) [0|15] "SED"  ACM,APIM,APIM_CISM
 SG_ WifiNoDevcCnnct_No_Actl : 47|8@0+ (1,0) [0|255] "unitless"  APIM_CISM,APIM
 SG_ WifiHtsptCnnct_D_Stat : 26|2@0+ (1,0) [0|3] "SED"  APIM_CISM,APIM
 SG_ Telematics_D_Falt : 39|3@0+ (1,0) [0|7] "SED"  APIM_CISM,APIM
 SG_ WifiEnbl_D_Stat : 4|2@0+ (1,0) [0|3] "SED"  APIM_CISM,APIM
 SG_ WifiHtsptVisbl_D_Stat : 13|2@0+ (1,0) [0|3] "SED"  APIM_CISM,APIM
 SG_ WifiHtsptScrty_D_Stat : 15|2@0+ (1,0) [0|3] "SED"  APIM_CISM,APIM
 SG_ WifiHtsptEnbl_D_Stat : 2|2@0+ (1,0) [0|3] "SED"  APIM_CISM,APIM
 SG_ WifiDevcListNew_B_Stat : 5|1@0+ (1,0) [0|1] "SED"  APIM_CISM,APIM
 SG_ WifiDataUsage_Pc_Actl : 20|4@0+ (5,50) [50|125] "percent"  APIM_CISM,APIM
 SG_ WifiDataUsage_D_Stat : 7|2@0+ (1,0) [0|3] "SED"  APIM_CISM,APIM
 SG_ ModemSigStren_D_Stat : 11|3@0+ (1,0) [0|7] "SED"  APIM_CISM,ACM,APIM
 SG_ ModemTechnology_D2_Stat : 31|3@0+ (1,0) [0|7] "SED"  HUD_ADV,APIM_CISM,APIM
 SG_ WifiHtsptCrdntl_B_Stat : 0|1@0+ (1,0) [0|1] "SED"  APIM,APIM_CISM
 SG_ WifiHtsptFq_D_Avail : 63|3@0+ (1,0) [0|7] "SED"  ACM,APIM,APIM_CISM
 SG_ WifiDataUsageOn_D_Stat : 28|2@0+ (1,0) [0|3] "SED"  APIM_CISM,APIM

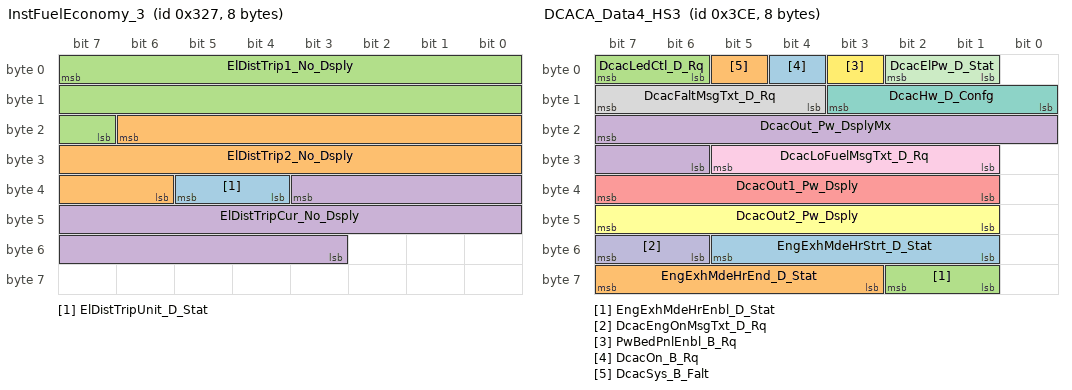
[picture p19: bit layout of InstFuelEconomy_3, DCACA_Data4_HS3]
BO_ 807 InstFuelEconomy_3: 8 IPC
 SG_ ElDistTripUnit_D_Stat : 37|2@0+ (1,0) [0|3] "SED"  APIM_CISM,APIM
 SG_ ElDistTrip2_No_Dsply : 22|17@0+ (0.1,0) [0|13107.1] "unitless"  APIM_CISM,APIM
 SG_ ElDistTrip1_No_Dsply : 7|17@0+ (0.1,0) [0|13107.1] "unitless"  APIM_CISM,APIM
 SG_ ElDistTripCur_No_Dsply : 35|17@0+ (0.1,0) [0|13107.1] "unitless"  APIM_CISM,APIM

BO_ 974 DCACA_Data4_HS3: 8 GWM
 SG_ EngExhMdeHrStrt_D_Stat : 53|5@0+ (1,0) [0|31] "SED"  APIM_CISM,APIM
 SG_ EngExhMdeHrEnd_D_Stat : 63|5@0+ (1,0) [0|31] "SED"  APIM_CISM,APIM
 SG_ EngExhMdeHrEnbl_D_Stat : 58|2@0+ (1,0) [0|3] "SED"  APIM_CISM,APIM
 SG_ DcacOut_Pw_DsplyMx : 23|10@0+ (10,0) [0|10220] "watts"  APIM_CISM,APIM
 SG_ DcacOut1_Pw_Dsply : 39|7@0+ (100,0) [0|12600] "watts"  APIM_CISM,APIM
 SG_ DcacOut2_Pw_Dsply : 47|7@0+ (100,0) [0|12600] "watts"  APIM_CISM,APIM
 SG_ DcacHw_D_Confg : 11|4@0+ (1,0) [0|15] "SED"  APIM_CISM,APIM
 SG_ DcacFaltMsgTxt_D_Rq : 15|4@0+ (1,0) [0|15] "SED"  APIM_CISM,APIM
 SG_ DcacLoFuelMsgTxt_D_Rq : 29|5@0+ (1,0) [0|31] "SED"  APIM_CISM,APIM
 SG_ DcacEngOnMsgTxt_D_Rq : 55|2@0+ (1,0) [0|3] "SED"  APIM_CISM,APIM
 SG_ DcacElPw_D_Stat : 2|2@0+ (1,0) [0|3] "SED"  APIM_CISM,APIM
 SG_ PwBedPnlEnbl_B_Rq : 3|1@0+ (1,0) [0|1] "SED"  GENERIC
 SG_ DcacOn_B_Rq : 4|1@0+ (1,0) [0|1] "SED"  GENERIC
 SG_ DcacSys_B_Falt : 5|1@0+ (1,0) [0|1] "SED"  GENERIC
 SG_ DcacLedCtl_D_Rq : 7|2@0+ (1,0) [0|3] "SED"  GWM

BO_ 805 InstFuelEconomy_2: 8 IPC
 SG_ InstFeTripUnit_D_Stat : 23|4@0+ (1,0) [0|15] "SED"  APIM_CISM,APIM
 SG_ InstFe_No_Dsply : 7|14@0+ (0.1,0) [0|1638.3] "unitless"  APIM_CISM,APIM

BO_TX_BU_ 533 : APIM_CISM,APIM;
BO_TX_BU_ 801 : ACM,APIM_CISM,APIM;
BO_TX_BU_ 1192 : APIM_CISM,APIM;
BO_TX_BU_ 413 : APIM_CISM,APIM;
BO_TX_BU_ 556 : FCIMB,GWM;
BO_TX_BU_ 1020 : APIM_CISM,APIM;
BO_TX_BU_ 2008 : APIM_CISM,APIM;
BO_TX_BU_ 473 : APIM_CISM,APIM;
BO_TX_BU_ 482 : APIM_CISM,APIM;
BO_TX_BU_ 764 : APIM_CISM,APIM;
BO_TX_BU_ 695 : APIM_CISM,APIM;
BO_TX_BU_ 1506 : APIM_CISM,APIM;
BO_TX_BU_ 718 : APIM_CISM,APIM;
BO_TX_BU_ 672 : GWM,FCIMB;
BO_TX_BU_ 816 : APIM_CISM,APIM;
CM_ BO_ 1184 "TP message";
CM_ SG_ 1192 APIM_TCU_Word_Tx "Tx by HS3 APIM";
CM_ SG_ 413 LBS1_ParentID "Object. ListBrowser.ItemInf.Rq.ActiveListID
0x0000:Root
0xFFFF:Reserved";
CM_ SG_ 413 LBS1_ListID "Object. ListBrowser.ItemInf.Rq.ItemIndex
0x0000:BrowseActiveListID
0x0001:EntryIndex_1
0xFFFF:ParentOfActiveListID";
CM_ SG_ 413 LBS1_EntryIndex "Object. ListBrowser.ItemInf.Rq.ActiveListID
0x0000:Root
0xFFFF:Reserved";
CM_ SG_ 556 EFP_Bezel_Diag_St "Object:BezelDiagnostics.EFP_Bezel_Diag.St";
CM_ SG_ 556 Bezel_Beep_St "Object:VehicleSettings.Bezel_Beeps.St.Status";
CM_ SG_ 556 Bezel_Beeps_Supported "Object: Vehicle Settings. Bezel_Beeps_Supported.St";
CM_ SG_ 259 SDARS_CurrCATlstSize_Rq "Object:SDARSClient.CurrentCatList.Rq.NumberOfItems 

0x00: Invalid
0x01: List Size 1
0x02: List Size 2
....
0x1E: List Size 30
0xFF: No Entry
";
CM_ SG_ 259 SDARS_CurrCATlistInd_Rq "ObjectTuner.SDARSTuner.CurrentCATList
$0: Inactive
$FF:No_Entry";
CM_ SG_ 259 SDARS_AlertStatus_Rq "Object.SDARSClient.AlertStatus.Rq.Status";
CM_ SG_ 538 MK_UserMyKeyCount_St "Object MyKey.SystemKeyCount_St
[Parameter1]";
CM_ SG_ 538 MK_SpeedMinderConf_St "Object MyKey.SpeedMinderConfig_St";
CM_ SG_ 538 MK_SpeedLimitConf_St "Object MyKey.SpeedLimitConfig_St";
CM_ SG_ 538 MK_ECalRestrictConf_St "Object MyKey.ECallRestrictionConfig_St";
CM_ SG_ 538 MK_DNDRestrictConf_St "Object MyKey.DNDRestrictionConfig_St";
CM_ SG_ 538 MK_AudioLimitConfig_St "Object MyKey.AudioLimitConfig_St";
CM_ SG_ 538 MK_AdminMyKeyCount_St "Object MyKey.SystemKeyCount_St
[Parameter2]";
CM_ SG_ 473 NAV_SetAFMode_Rq "Object Tuner.SetAFMode";
CM_ SG_ 473 NAV_StorePreset_Rq "Object Tuner.StorePreset

NOTE: If used on CANalyzer/CANoe for the older DENSO HighNav System, wrong values will be shown!";
CM_ SG_ 473 NAV_SetTUServiceLink_Rq "Object Tuner.NAV_SetTUServiceLink_Rq";
CM_ SG_ 473 NAV_SetTAMode_Rq "Object Tuner.SetTAMode";
CM_ SG_ 473 NAV_SetReg_Rq "Object Tuner.SetREG";
CM_ SG_ 473 NAV_SelectPTYCodeSet_Rq "Object Tuner.SelectPTYCodes

Set PTY code with the follow bit encoding";
CM_ SG_ 473 NAV_SelectPTYCodes_Rq "Object Tuner.SelectPTYCodes

28 bit bitfield where each PTY code can be set separately:
Bit 0:  0:  PTY Code 2 not selected; 1:  PTY Code 2 selected
...
Bit 27: PTY Code 29 not selected; 1:  PTY Code 29 selected";
CM_ SG_ 473 NAV_CDSetShuffle_Rq "Object Single CD.SetShuffle";
CM_ SG_ 473 NAV_CDSetRepeat_Rq "Object Single CD.SetRepeat";
CM_ SG_ 473 NAV_CDSetIntroScan_Rq "Object Single CD.SetIntroScan";
CM_ SG_ 482 SDARS_Firm_Update2_St "Object Tuner.SDARS Tuner.FirmwareUpdate";
CM_ SG_ 482 SDARS_UnSubscrb_Chan2_St "Object Tuner.SDARS Tuner.Unsubscribed Channel ";
CM_ SG_ 482 SDARS_UnSubscrb2_St "Object Tuner.SDARS Tuner.Unsubscribed Receiver ";
CM_ SG_ 482 SDARS_Subscription2_St "Object Tuner.SDARS Tuner.Subscription Update ";
CM_ SG_ 482 SDARS_Seek_Scan2_St "Method SDARS_Error_Msg
Int Seek/Scan No Channels Available

0x1: No Channel Available
Object Tuner.SDARS Tuner.";
CM_ SG_ 482 SDARS_Receive_Err2_St "Object Tuner.SDARS Tuner.Receiver Error";
CM_ SG_ 482 SDARS_Loss_Ant2_St "Object Tuner.SDARS Tuner.Loss of Antenna Signal ";
CM_ SG_ 482 SDARS_Invalid_Chan2_St "Object Tuner.SDARS Tuner.";
CM_ SG_ 482 SDARS_GCI_Update2_St "Object Tuner.SDARS Tuner.GCI Update ";
CM_ SG_ 482 SDARS_Error_Conf2_St "Object Tuner.SDARS Tuner.Configuration Status";
CM_ SG_ 482 SDARS_Antenna_Err2_St "Object Tuner.SDARS Tuner.Antenna Error";
CM_ SG_ 764 SDARS_SID2_St "Object Tuner.SDARS.ServiceID
$0: SID_0
$1: SID_1
$2: SID_2
$FE: SID_254
$FF: SID_255

";
CM_ SG_ 764 SDARS_CurrentChanNum2_St "Object Tuner.SDARS Tuner.CurrentChanNum.ChanNum 
$0: Channel_0
$1: Channel_1
$2: Channel_2
$FE: Channel_254
$FF: Inactive";
CM_ SG_ 764 SDARS_Channel_Lock2 "Method SDARS_Channel_Lock";
CM_ BO_ 710 "TP message(Transport Protocol), Rx's HS3 APIM & MFD, transmitted immediately";
CM_ SG_ 391 ACU_CtrlChimeChan_Rq "Object BodyInterface.StdChimeIF.ControlChimeChannel.Rq";
CM_ SG_ 415 LBC3_StartItemInd "Object. ListBrowser.ItemInf.Rq.StartItemInd
0x0000:Inactive
0x0001:1
0xFFFE:65634
0xFFFF:Reserved";
CM_ SG_ 415 LBC3_SetListServ "Object. ListBrowser.ItemInf.Rq.SetListServ
0x00:Inactive
0x01:ServerID_1
0xFF:ALL";
CM_ SG_ 415 LBC3_Opcode "Object. ListBrowser.ItemInf.Rq.Opcode";
CM_ SG_ 415 LBC3_NbrOfItems "Object. ListBrowser.ItemInf.Rq.NbrOfItems
0x00:Inactive
0x01:1Item
0x3F:63Items";
CM_ SG_ 415 LBC3_ItemIndex "Object. ListBrowser.ItemInf.Rq.ItemIndex
0x0000:BrowseActiveListID
0x0001:EntryIndex_1
0xFFFF:ParentOfActiveListID";
CM_ SG_ 415 LBC3_ActiveListID "Object. ListBrowser.ItemInf.Rq.ActiveListID
0x0000:Root
0xFFFF:Reserved";
CM_ SG_ 703 CONMP_MC_WORD_Rx "MM ISO 15765-2 Message Catalogue
Section CONMP - MC
Section MediaPlayerServer - MediaPlayerClient";
CM_ SG_ 695 CONMP_MC_WORD_Tx "MM ISO 15765-2 Message Catalogue
Section CONMP - MC
Section MediaPlayerServer - MediaPlayerClient";
CM_ SG_ 501 Dsp_PresetArea_Rq "Object Tuner.GetPresetInfo2.PresetArea

$5: Get AMAST (MW) Preset Data
$6: Get AM (LW) Preset Data";
CM_ SG_ 501 Dsp_StartIndex2_Rq "Object Tuner.GetPresetInfo2.StartingIndex

$1-$FF: Preset 1 to 255";
CM_ SG_ 501 Dsp_SetRadSeekMode_Rq "Object Tuner.SetRadioSeekMode";
CM_ SG_ 501 Dsp_SetCurrPreset2_Rq "Object Tuner.SetCurrentPreset2

$1-$1E: Preset 1 to 30
$0: Inactive
";
CM_ SG_ 501 Dsp_SetCurrFMSLPr_Rq "Object.AMFMSlave.SetCurrentSLStation.Rq.Index
0x01 : Index 1
0x02 : Index 2
0x03 : Index 3
...
...
0xFE : Index 254";
CM_ SG_ 501 Dsp_SetCRadioBand_Rq "Object Tuner.SetCurrRadioBand
$5: AM (LLN, HLN: MW)
$6: AM AST (LLN, HLN: LW)";
CM_ BO_ 651 "TCU CPPM Tx";
CM_ SG_ 629 GearPos_D_Actl "Powersplit HEVs with HF45, HPCM will Tx  this message.  For all other programs it will be Tx by PCM or TCM. ";
CM_ SG_ 629 TrnRng_D_Rq "Powersplit HEVs with HF45, HPCM will Tx  this message.  For all other programs it will be Tx by PCM or TCM. ";
CM_ SG_ 672 BCP_Audible_Beep_Rq "Object.AlertMethod.BCP_Audible_Beep";
CM_ SG_ 672 SetVolume "$0: -30Steps
$1: -29Steps
$2: -28Steps
$1D: -1Step
$1E: NotPressed_Inactive
$1F: +1Step
$20: +2Steps
$21: +3Steps
$3C: +30Steps";
CM_ SG_ 672 SetPointVolume "Method: EFP_Button_Press
0x0:Inactive
$0: Inactive
$1: No_Volume
$2: Volume_Step1
$3: Vol_Step2
$1F: Vol_Step30";
CM_ SG_ 672 Coding_BtnID_D "Object InputControlInterface ICI ButtonCoding_D
Object InputControlInterface ICI ButtonID_D";
CM_ SG_ 672 Coding_BtnID_C "Object InputControlInterface.ICI ButtonCoding_C
Object InputControlInterface.ICI ButtonID_C";
CM_ SG_ 672 Coding_BtnID_B "Object InputControlInterface ICI ButtonCoding_B
Object InputControlInterface.ICI ButtonID_B";
CM_ SG_ 672 Coding_BtnID_A "Object InputControlInterface ICI ButtonCoding_A
Object InputControlInterface.ICI ButtonID A";
CM_ SG_ 672 BtnID_D "Object InputControlInterface ICI ButtonID_D... 0xFF: Inactive";
CM_ SG_ 672 BtnID_C "Object InputControlInterface ICI ButtonID_D... 0xFF: Inactive";
CM_ SG_ 672 BtnID_B "Object InputControlInterface ICI ButtonID_D... 0xFF: Inactive";
CM_ SG_ 672 BtnID_A "Object InputControlInterface ICI ButtonID_D... 0xFF: Inactive";
BA_DEF_ BO_  "FrameRouting" STRING ;
BA_DEF_ BO_  "FrameGatewayNetwork" STRING ;
BA_DEF_ BO_  "NetworkInitialization" ENUM  "No","Yes";
BA_DEF_ BO_  "FrameGatewayId" HEX 0 1407;
BA_DEF_ BO_  "EventRateOfChange" INT 10 10000;
BA_DEF_ BO_  "GenMsgStartDelayTime" INT 0 10000;
BA_DEF_ BO_  "GenMsgNrOfRepetition" INT 0 100;
BA_DEF_ BO_  "GenMsgDelayTime" INT 0 1000;
BA_DEF_ BO_  "GenMsgCycleTime" INT 0 100000;
BA_DEF_ BO_  "GenMsgSendType" ENUM  "FixedPeriodic","Event","EnabledPeriodic","NotUsed","NotUsed","EventPeriodic","NotUsed","NotUsed","NoMsgSendType";
BA_DEF_ SG_  "U_CD764_MY2022_Tx" ENUM  "No","Yes";
BA_DEF_ SG_  "U_U55X_MY2022_Tx" ENUM  "No","Yes";
BA_DEF_ SG_  "U_CD542_MY2021_Tx" ENUM  "No","Yes";
BA_DEF_ SG_  "ECGUsedTxSignal" ENUM  "No","Yes";
BA_DEF_ SG_  "U_T6_MCA_MY2020_Tx" ENUM  "No","Yes";
BA_DEF_ SG_  "U_P702_MY2021_Tx" ENUM  "No","Yes";
BA_DEF_ SG_  "U_CX727_MY2021_Tx" ENUM  "No","Yes";
BA_DEF_ SG_  "U_CD764_MY2022_Rx" ENUM  "No","Yes";
BA_DEF_ SG_  "U_FNV2_IVI_Rx" ENUM  "No","Yes";
BA_DEF_ SG_  "U_U55X_MY2022_Rx" ENUM  "No","Yes";
BA_DEF_ SG_  "U_CD542_MY2021_Rx" ENUM  "No","Yes";
BA_DEF_ SG_  "ECGUsedRxSignal" ENUM  "No","Yes";
BA_DEF_ SG_  "U_T6_MCA_MY2020_Rx" ENUM  "No","Yes";
BA_DEF_ SG_  "U_P702_MY2021_Rx" ENUM  "No","Yes";
BA_DEF_ SG_  "U_CX727_MY2021_Rx" ENUM  "No","Yes";
BA_DEF_ SG_  "GenSigStartValue" HEX 0 268435455;
BA_DEF_ SG_  "MetaData" ENUM  "No","Yes";
BA_DEF_ SG_  "ContentDependant" ENUM  "No","Yes";
BA_DEF_ SG_  "GenSigStartValueInteger" INT 0 1000000000;
BA_DEF_ SG_  "UsedOnPgmDBC" ENUM  "No","Yes";
BA_DEF_ SG_  "WakeupSignal" ENUM  "No","Yes";
BA_DEF_ SG_  "GenSigInactiveValue" INT 0 100000;
BA_DEF_ SG_  "GenSigSendType" ENUM  "Cyclic","OnWrite","vector_leerstring","OnChange","vector_leerstring","IfActive","vector_leerstring","NoSigSendType";
BA_DEF_ BO_  "OvtpPushApplication" ENUM  "FALSE","TRUE";
BA_DEF_ BO_  "SCP_FreshnessValueLength" INT 0 512;
BA_DEF_ BO_  "SCP_FreshnessValueTxLength" INT 0 512;
BA_DEF_ BO_  "SCP_AuthInfoTxLength" INT 0 512;
BA_DEF_ BO_  "GenMsgRoutingTimeoutTime" INT 0 5000;
BA_DEF_ BO_  "MessageGateway" ENUM  "No","Yes";
BA_DEF_ BO_  "NmAsrMessage" ENUM  "No","Yes";
BA_DEF_ BO_  "DiagState" ENUM  "No","Yes";
BA_DEF_ BO_  "TpTxIndex" INT 0 536870911;
BA_DEF_ BO_  "DiagRequest" ENUM  "No","Yes";
BA_DEF_ BO_  "DiagResponse" ENUM  "No","Yes";
BA_DEF_ BO_  "GenMsgILSupport" ENUM  "No","Yes";
BA_DEF_DEF_  "FrameRouting" "";
BA_DEF_DEF_  "FrameGatewayNetwork" "NONE";
BA_DEF_DEF_  "NetworkInitialization" "Yes";
BA_DEF_DEF_  "FrameGatewayId" 0;
BA_DEF_DEF_  "EventRateOfChange" 10000;
BA_DEF_DEF_  "GenMsgStartDelayTime" 0;
BA_DEF_DEF_  "GenMsgNrOfRepetition" 1;
BA_DEF_DEF_  "GenMsgDelayTime" 20;
BA_DEF_DEF_  "GenMsgCycleTime" 0;
BA_DEF_DEF_  "GenMsgSendType" "NoMsgSendType";
BA_DEF_DEF_  "U_CD764_MY2022_Tx" "No";
BA_DEF_DEF_  "U_U55X_MY2022_Tx" "No";
BA_DEF_DEF_  "U_CD542_MY2021_Tx" "No";
BA_DEF_DEF_  "ECGUsedTxSignal" "No";
BA_DEF_DEF_  "U_T6_MCA_MY2020_Tx" "No";
BA_DEF_DEF_  "U_P702_MY2021_Tx" "No";
BA_DEF_DEF_  "U_CX727_MY2021_Tx" "No";
BA_DEF_DEF_  "U_CD764_MY2022_Rx" "No";
BA_DEF_DEF_  "U_FNV2_IVI_Rx" "No";
BA_DEF_DEF_  "U_U55X_MY2022_Rx" "No";
BA_DEF_DEF_  "U_CD542_MY2021_Rx" "No";
BA_DEF_DEF_  "ECGUsedRxSignal" "No";
BA_DEF_DEF_  "U_T6_MCA_MY2020_Rx" "No";
BA_DEF_DEF_  "U_P702_MY2021_Rx" "No";
BA_DEF_DEF_  "U_CX727_MY2021_Rx" "No";
BA_DEF_DEF_  "GenSigStartValue" 0;
BA_DEF_DEF_  "MetaData" "No";
BA_DEF_DEF_  "ContentDependant" "No";
BA_DEF_DEF_  "GenSigStartValueInteger" 0;
BA_DEF_DEF_  "UsedOnPgmDBC" "Yes";
BA_DEF_DEF_  "WakeupSignal" "No";
BA_DEF_DEF_  "GenSigInactiveValue" 0;
BA_DEF_DEF_  "GenSigSendType" "NoSigSendType";
BA_DEF_DEF_  "OvtpPushApplication" "FALSE";
BA_DEF_DEF_  "SCP_FreshnessValueLength" 64;
BA_DEF_DEF_  "SCP_FreshnessValueTxLength" 11;
BA_DEF_DEF_  "SCP_AuthInfoTxLength" 53;
BA_DEF_DEF_  "GenMsgRoutingTimeoutTime" 0;
BA_DEF_DEF_  "MessageGateway" "No";
BA_DEF_DEF_  "NmAsrMessage" "No";
BA_DEF_DEF_  "DiagState" "No";
BA_DEF_DEF_  "TpTxIndex" 0;
BA_DEF_DEF_  "DiagRequest" "No";
BA_DEF_DEF_  "DiagResponse" "No";
BA_DEF_DEF_  "GenMsgILSupport" "Yes";
BA_ "FrameRouting" BO_ 1012 "HS1_CAN,0x3F4;";
BA_ "FrameGatewayNetwork" BO_ 1012 "HS1_CAN";
BA_ "FrameGatewayId" BO_ 1012 1012;
BA_ "FrameRouting" BO_ 1011 "FD1_CAN,0x3F3;";
BA_ "FrameGatewayNetwork" BO_ 1011 "FD1_CAN";
BA_ "FrameGatewayId" BO_ 1011 1011;
BA_ "GenMsgCycleTime" BO_ 533 1000;
BA_ "GenMsgSendType" BO_ 533 5;
BA_ "FrameRouting" BO_ 1184 "HS4_CAN,0x4A0";
BA_ "FrameGatewayNetwork" BO_ 1184 "HS4_CAN";
BA_ "FrameGatewayId" BO_ 1184 1184;
BA_ "TpTxIndex" BO_ 1184 20;
BA_ "GenMsgCycleTime" BO_ 801 1000;
BA_ "GenMsgSendType" BO_ 801 5;
BA_ "GenMsgCycleTime" BO_ 878 1000;
BA_ "GenMsgSendType" BO_ 878 5;
BA_ "FrameRouting" BO_ 258 "HS4_CAN,0x102;";
BA_ "FrameGatewayNetwork" BO_ 258 "HS4_CAN";
BA_ "FrameGatewayId" BO_ 258 258;
BA_ "TpTxIndex" BO_ 1192 20;
BA_ "FrameRouting" BO_ 1247 "HS1_CAN,0x4DF;";
BA_ "FrameGatewayNetwork" BO_ 1247 "HS1_CAN";
BA_ "FrameGatewayId" BO_ 1247 1247;
BA_ "GenMsgSendType" BO_ 413 1;
BA_ "FrameRouting" BO_ 556 "MS1_CAN,0x22C;HS3_CAN,0x22C";
BA_ "FrameGatewayNetwork" BO_ 556 "MS1_CAN";
BA_ "FrameGatewayId" BO_ 556 556;
BA_ "GenMsgSendType" BO_ 259 1;
BA_ "GenMsgCycleTime" BO_ 538 1000;
BA_ "GenMsgSendType" BO_ 538 5;
BA_ "NetworkInitialization" BO_ 422 0;
BA_ "GenMsgSendType" BO_ 422 1;
BA_ "GenMsgCycleTime" BO_ 1020 1000;
BA_ "GenMsgSendType" BO_ 1020 5;
BA_ "GenMsgCycleTime" BO_ 1007 1000;
BA_ "GenMsgSendType" BO_ 1007 5;
BA_ "NetworkInitialization" BO_ 2008 0;
BA_ "GenMsgDelayTime" BO_ 2008 0;
BA_ "GenMsgSendType" BO_ 2008 1;
BA_ "DiagResponse" BO_ 2008 1;
BA_ "GenMsgILSupport" BO_ 2008 0;
BA_ "FrameRouting" BO_ 884 "MS1_CAN,0x374;";
BA_ "FrameGatewayNetwork" BO_ 884 "MS1_CAN";
BA_ "FrameGatewayId" BO_ 884 884;
BA_ "FrameRouting" BO_ 883 "MS1_CAN,0x373;";
BA_ "FrameGatewayNetwork" BO_ 883 "MS1_CAN";
BA_ "FrameGatewayId" BO_ 883 883;
BA_ "FrameRouting" BO_ 1090 "FD1_CAN,0x442;";
BA_ "FrameGatewayNetwork" BO_ 1090 "FD1_CAN";
BA_ "FrameGatewayId" BO_ 1090 1090;
BA_ "GenMsgCycleTime" BO_ 677 1000;
BA_ "GenMsgSendType" BO_ 677 5;
BA_ "FrameRouting" BO_ 1238 "FD1_CAN,0x4D6;";
BA_ "FrameGatewayNetwork" BO_ 1238 "FD1_CAN";
BA_ "FrameGatewayId" BO_ 1238 1238;
BA_ "FrameRouting" BO_ 1041 "HS1_CAN,0x411;";
BA_ "FrameGatewayNetwork" BO_ 1041 "HS1_CAN";
BA_ "FrameGatewayId" BO_ 1041 1041;
BA_ "NetworkInitialization" BO_ 2609971416 0;
BA_ "GenMsgDelayTime" BO_ 2609971416 0;
BA_ "GenMsgSendType" BO_ 2609971416 1;
BA_ "TpTxIndex" BO_ 2609971416 462487768;
BA_ "NetworkInitialization" BO_ 2610126912 0;
BA_ "GenMsgDelayTime" BO_ 2610126912 0;
BA_ "GenMsgSendType" BO_ 2610126912 1;
BA_ "TpTxIndex" BO_ 2610126912 462487768;
BA_ "NetworkInitialization" BO_ 2611019992 0;
BA_ "GenMsgDelayTime" BO_ 2611019992 0;
BA_ "GenMsgSendType" BO_ 2611019992 1;
BA_ "TpTxIndex" BO_ 2611019992 463536344;
BA_ "NetworkInitialization" BO_ 2611175488 0;
BA_ "GenMsgDelayTime" BO_ 2611175488 0;
BA_ "GenMsgSendType" BO_ 2611175488 1;
BA_ "TpTxIndex" BO_ 2611175488 463536344;
BA_ "NetworkInitialization" BO_ 2612068568 0;
BA_ "GenMsgDelayTime" BO_ 2612068568 0;
BA_ "GenMsgSendType" BO_ 2612068568 1;
BA_ "OvtpPushApplication" BO_ 2612068568 1;
BA_ "TpTxIndex" BO_ 2612068568 464584920;
BA_ "NetworkInitialization" BO_ 2612224064 0;
BA_ "GenMsgDelayTime" BO_ 2612224064 0;
BA_ "GenMsgSendType" BO_ 2612224064 1;
BA_ "TpTxIndex" BO_ 2612224064 464584920;
BA_ "GenMsgCycleTime" BO_ 557 1000;
BA_ "GenMsgSendType" BO_ 557 5;
BA_ "FrameRouting" BO_ 1236 "FD1_CAN,0x4D4;";
BA_ "FrameGatewayNetwork" BO_ 1236 "FD1_CAN";
BA_ "FrameGatewayId" BO_ 1236 1236;
BA_ "FrameRouting" BO_ 1235 "FD1_CAN,0x4D3;";
BA_ "FrameGatewayNetwork" BO_ 1235 "FD1_CAN";
BA_ "FrameGatewayId" BO_ 1235 1235;
BA_ "FrameRouting" BO_ 1234 "FD1_CAN,0x4D2;";
BA_ "FrameGatewayNetwork" BO_ 1234 "FD1_CAN";
BA_ "FrameGatewayId" BO_ 1234 1234;
BA_ "FrameRouting" BO_ 1237 "FD1_CAN,0x4D5;";
BA_ "FrameGatewayNetwork" BO_ 1237 "FD1_CAN";
BA_ "FrameGatewayId" BO_ 1237 1237;
BA_ "GenMsgCycleTime" BO_ 976 1000;
BA_ "GenMsgSendType" BO_ 976 5;
BA_ "TpTxIndex" BO_ 715 23;
BA_ "FrameRouting" BO_ 925 "FD1_CAN,0x39D";
BA_ "FrameGatewayNetwork" BO_ 925 "FD1_CAN";
BA_ "FrameGatewayId" BO_ 925 925;
BA_ "FrameRouting" BO_ 788 "FD1_CAN,0x314;";
BA_ "FrameGatewayNetwork" BO_ 788 "FD1_CAN";
BA_ "FrameGatewayId" BO_ 788 788;
BA_ "GenMsgSendType" BO_ 473 1;
BA_ "NetworkInitialization" BO_ 2000 0;
BA_ "GenMsgDelayTime" BO_ 2000 0;
BA_ "GenMsgSendType" BO_ 2000 1;
BA_ "DiagRequest" BO_ 2000 1;
BA_ "GenMsgILSupport" BO_ 2000 0;
BA_ "GenMsgCycleTime" BO_ 810 1000;
BA_ "GenMsgSendType" BO_ 810 5;
BA_ "GenMsgCycleTime" BO_ 482 1000;
BA_ "GenMsgSendType" BO_ 482 5;
BA_ "GenMsgCycleTime" BO_ 764 1000;
BA_ "GenMsgSendType" BO_ 764 5;
BA_ "GenMsgCycleTime" BO_ 628 1000;
BA_ "GenMsgSendType" BO_ 628 5;
BA_ "FrameRouting" BO_ 710 "MS1_CAN,0x2C6;";
BA_ "FrameGatewayNetwork" BO_ 710 "MS1_CAN";
BA_ "FrameGatewayId" BO_ 710 710;
BA_ "TpTxIndex" BO_ 710 26;
BA_ "FrameRouting" BO_ 770 "FD1_CAN,0x302;";
BA_ "FrameGatewayNetwork" BO_ 770 "FD1_CAN";
BA_ "FrameGatewayId" BO_ 770 770;
BA_ "FrameRouting" BO_ 785 "FD1_CAN,0x311;";
BA_ "FrameGatewayNetwork" BO_ 785 "FD1_CAN";
BA_ "FrameGatewayId" BO_ 785 785;
BA_ "TpTxIndex" BO_ 1202 40;
BA_ "TpTxIndex" BO_ 1210 40;
BA_ "GenMsgSendType" BO_ 391 1;
BA_ "GenMsgSendType" BO_ 415 1;
BA_ "NetworkInitialization" BO_ 703 0;
BA_ "TpTxIndex" BO_ 703 18;
BA_ "TpTxIndex" BO_ 695 18;
BA_ "GenMsgSendType" BO_ 501 1;
BA_ "NetworkInitialization" BO_ 1506 0;
BA_ "GenMsgCycleTime" BO_ 1506 1000;
BA_ "GenMsgSendType" BO_ 1506 0;
BA_ "NmAsrMessage" BO_ 1506 1;
BA_ "GenMsgILSupport" BO_ 1506 0;
BA_ "FrameRouting" BO_ 651 "HS4_CAN,0x28B";
BA_ "FrameGatewayNetwork" BO_ 651 "HS4_CAN";
BA_ "FrameGatewayId" BO_ 651 651;
BA_ "FrameRouting" BO_ 1098 "FD1_CAN,0x44A;";
BA_ "FrameGatewayNetwork" BO_ 1098 "FD1_CAN";
BA_ "FrameGatewayId" BO_ 1098 1098;
BA_ "GenMsgCycleTime" BO_ 629 1000;
BA_ "GenMsgSendType" BO_ 629 5;
BA_ "TpTxIndex" BO_ 718 26;
BA_ "GenMsgStartDelayTime" BO_ 672 150;
BA_ "GenMsgCycleTime" BO_ 672 1000;
BA_ "GenMsgSendType" BO_ 672 5;
BA_ "NetworkInitialization" BO_ 1952 0;
BA_ "GenMsgDelayTime" BO_ 1952 0;
BA_ "GenMsgSendType" BO_ 1952 1;
BA_ "DiagRequest" BO_ 1952 1;
BA_ "GenMsgILSupport" BO_ 1952 0;
BA_ "NetworkInitialization" BO_ 1960 0;
BA_ "GenMsgDelayTime" BO_ 1960 0;
BA_ "GenMsgSendType" BO_ 1960 1;
BA_ "DiagResponse" BO_ 1960 1;
BA_ "GenMsgILSupport" BO_ 1960 0;
BA_ "FrameRouting" BO_ 1205 "FD1_CAN,0x4B5";
BA_ "FrameGatewayNetwork" BO_ 1205 "FD1_CAN";
BA_ "FrameGatewayId" BO_ 1205 1205;
BA_ "NetworkInitialization" BO_ 1829 0;
BA_ "GenMsgDelayTime" BO_ 1829 0;
BA_ "GenMsgSendType" BO_ 1829 1;
BA_ "DiagRequest" BO_ 1829 1;
BA_ "GenMsgILSupport" BO_ 1829 0;
BA_ "TpTxIndex" BO_ 601 58;
BA_ "TpTxIndex" BO_ 593 58;
BA_ "GenMsgCycleTime" BO_ 816 1000;
BA_ "GenMsgSendType" BO_ 816 5;
BA_ "FrameRouting" BO_ 636 "HS4_CAN,0x27C";
BA_ "FrameGatewayNetwork" BO_ 636 "HS4_CAN";
BA_ "FrameGatewayId" BO_ 636 636;
BA_ "GenMsgCycleTime" BO_ 807 1000;
BA_ "GenMsgSendType" BO_ 807 5;
BA_ "FrameRouting" BO_ 974 "FD1_CAN,0x36E;";
BA_ "FrameGatewayNetwork" BO_ 974 "FD1_CAN";
BA_ "FrameGatewayId" BO_ 974 878;
BA_ "GenMsgCycleTime" BO_ 805 100;
BA_ "GenMsgSendType" BO_ 805 0;
BA_ "U_U55X_MY2022_Rx" SG_ 1012 ChrgLocSaved_B_Dsply 1;
BA_ "U_CD542_MY2021_Rx" SG_ 1012 ChrgLocSaved_B_Dsply 1;
BA_ "U_T6_MCA_MY2020_Rx" SG_ 1012 ChrgLocSaved_B_Dsply 1;
BA_ "U_P702_MY2021_Rx" SG_ 1012 ChrgLocSaved_B_Dsply 1;
BA_ "U_CD542_MY2021_Rx" SG_ 1012 ChrgLocLongPostv_B_Sav 1;
BA_ "U_U55X_MY2022_Rx" SG_ 1012 ChrgLocLongPostv_B_Sav 1;
BA_ "U_T6_MCA_MY2020_Rx" SG_ 1012 ChrgLocLongPostv_B_Sav 1;
BA_ "U_P702_MY2021_Rx" SG_ 1012 ChrgLocLongPostv_B_Sav 1;
BA_ "U_CD542_MY2021_Rx" SG_ 1012 ChrgLocLongFrct_An_Sav 1;
BA_ "U_U55X_MY2022_Rx" SG_ 1012 ChrgLocLongFrct_An_Sav 1;
BA_ "U_T6_MCA_MY2020_Rx" SG_ 1012 ChrgLocLongFrct_An_Sav 1;
BA_ "U_P702_MY2021_Rx" SG_ 1012 ChrgLocLongFrct_An_Sav 1;
BA_ "GenSigStartValue" SG_ 1012 ChrgLocLongFrct_An_Sav 1048575;
BA_ "GenSigStartValueInteger" SG_ 1012 ChrgLocLongFrct_An_Sav 1048575;
BA_ "U_CD542_MY2021_Rx" SG_ 1012 ChrgLocLongDeg_An_Sav 1;
BA_ "U_U55X_MY2022_Rx" SG_ 1012 ChrgLocLongDeg_An_Sav 1;
BA_ "U_T6_MCA_MY2020_Rx" SG_ 1012 ChrgLocLongDeg_An_Sav 1;
BA_ "U_P702_MY2021_Rx" SG_ 1012 ChrgLocLongDeg_An_Sav 1;
BA_ "U_CD542_MY2021_Rx" SG_ 1012 ChrgLocLattPostv_B_Sav 1;
BA_ "U_U55X_MY2022_Rx" SG_ 1012 ChrgLocLattPostv_B_Sav 1;
BA_ "U_T6_MCA_MY2020_Rx" SG_ 1012 ChrgLocLattPostv_B_Sav 1;
BA_ "U_P702_MY2021_Rx" SG_ 1012 ChrgLocLattPostv_B_Sav 1;
BA_ "U_CD542_MY2021_Rx" SG_ 1012 ChrgLocLattFrct_An_Sav 1;
BA_ "U_U55X_MY2022_Rx" SG_ 1012 ChrgLocLattFrct_An_Sav 1;
BA_ "U_T6_MCA_MY2020_Rx" SG_ 1012 ChrgLocLattFrct_An_Sav 1;
BA_ "U_P702_MY2021_Rx" SG_ 1012 ChrgLocLattFrct_An_Sav 1;
BA_ "GenSigStartValue" SG_ 1012 ChrgLocLattFrct_An_Sav 1048575;
BA_ "GenSigStartValueInteger" SG_ 1012 ChrgLocLattFrct_An_Sav 1048575;
BA_ "U_CD542_MY2021_Rx" SG_ 1012 ChrgLocLattDeg_An_Sav 1;
BA_ "U_U55X_MY2022_Rx" SG_ 1012 ChrgLocLattDeg_An_Sav 1;
BA_ "U_T6_MCA_MY2020_Rx" SG_ 1012 ChrgLocLattDeg_An_Sav 1;
BA_ "U_P702_MY2021_Rx" SG_ 1012 ChrgLocLattDeg_An_Sav 1;
BA_ "U_CD542_MY2021_Rx" SG_ 1012 ChrgLocId_D_Sav 1;
BA_ "U_U55X_MY2022_Rx" SG_ 1012 ChrgLocId_D_Sav 1;
BA_ "U_T6_MCA_MY2020_Rx" SG_ 1012 ChrgLocId_D_Sav 1;
BA_ "U_P702_MY2021_Rx" SG_ 1012 ChrgLocId_D_Sav 1;
BA_ "U_CD542_MY2021_Rx" SG_ 1012 ChrgNowCurnt_B_Dsply 1;
BA_ "U_U55X_MY2022_Rx" SG_ 1012 ChrgNowCurnt_B_Dsply 1;
BA_ "U_T6_MCA_MY2020_Rx" SG_ 1012 ChrgNowCurnt_B_Dsply 1;
BA_ "U_P702_MY2021_Rx" SG_ 1012 ChrgNowCurnt_B_Dsply 1;
BA_ "U_U55X_MY2022_Rx" SG_ 1011 ChrgLocLongPostv_B_Uns 1;
BA_ "U_CD542_MY2021_Rx" SG_ 1011 ChrgLocLongPostv_B_Uns 1;
BA_ "U_T6_MCA_MY2020_Rx" SG_ 1011 ChrgLocLongPostv_B_Uns 1;
BA_ "U_P702_MY2021_Rx" SG_ 1011 ChrgLocLongPostv_B_Uns 1;
BA_ "U_U55X_MY2022_Rx" SG_ 1011 ChrgLocLongFrct_An_Uns 1;
BA_ "U_CD542_MY2021_Rx" SG_ 1011 ChrgLocLongFrct_An_Uns 1;
BA_ "U_T6_MCA_MY2020_Rx" SG_ 1011 ChrgLocLongFrct_An_Uns 1;
BA_ "U_P702_MY2021_Rx" SG_ 1011 ChrgLocLongFrct_An_Uns 1;
BA_ "GenSigStartValue" SG_ 1011 ChrgLocLongFrct_An_Uns 1048575;
BA_ "GenSigStartValueInteger" SG_ 1011 ChrgLocLongFrct_An_Uns 1048575;
BA_ "U_U55X_MY2022_Rx" SG_ 1011 ChrgLocLongDeg_An_Uns 1;
BA_ "U_CD542_MY2021_Rx" SG_ 1011 ChrgLocLongDeg_An_Uns 1;
BA_ "U_T6_MCA_MY2020_Rx" SG_ 1011 ChrgLocLongDeg_An_Uns 1;
BA_ "U_P702_MY2021_Rx" SG_ 1011 ChrgLocLongDeg_An_Uns 1;
BA_ "U_U55X_MY2022_Rx" SG_ 1011 ChrgLocLattPostv_B_Uns 1;
BA_ "U_CD542_MY2021_Rx" SG_ 1011 ChrgLocLattPostv_B_Uns 1;
BA_ "U_T6_MCA_MY2020_Rx" SG_ 1011 ChrgLocLattPostv_B_Uns 1;
BA_ "U_P702_MY2021_Rx" SG_ 1011 ChrgLocLattPostv_B_Uns 1;
BA_ "U_U55X_MY2022_Rx" SG_ 1011 ChrgLocLattFrct_An_Uns 1;
BA_ "U_CD542_MY2021_Rx" SG_ 1011 ChrgLocLattFrct_An_Uns 1;
BA_ "U_T6_MCA_MY2020_Rx" SG_ 1011 ChrgLocLattFrct_An_Uns 1;
BA_ "U_P702_MY2021_Rx" SG_ 1011 ChrgLocLattFrct_An_Uns 1;
BA_ "GenSigStartValue" SG_ 1011 ChrgLocLattFrct_An_Uns 1048575;
BA_ "GenSigStartValueInteger" SG_ 1011 ChrgLocLattFrct_An_Uns 1048575;
BA_ "U_U55X_MY2022_Rx" SG_ 1011 ChrgLocLattDeg_An_Uns 1;
BA_ "U_CD542_MY2021_Rx" SG_ 1011 ChrgLocLattDeg_An_Uns 1;
BA_ "U_T6_MCA_MY2020_Rx" SG_ 1011 ChrgLocLattDeg_An_Uns 1;
BA_ "U_P702_MY2021_Rx" SG_ 1011 ChrgLocLattDeg_An_Uns 1;
BA_ "U_U55X_MY2022_Rx" SG_ 1011 ChrgLocId_D_Uns 1;
BA_ "U_CD542_MY2021_Rx" SG_ 1011 ChrgLocId_D_Uns 1;
BA_ "U_T6_MCA_MY2020_Rx" SG_ 1011 ChrgLocId_D_Uns 1;
BA_ "U_P702_MY2021_Rx" SG_ 1011 ChrgLocId_D_Uns 1;
BA_ "U_U55X_MY2022_Tx" SG_ 533 AutoEpbZoomView_B_Stat 1;
BA_ "U_CD542_MY2021_Tx" SG_ 533 AutoEpbZoomView_B_Stat 1;
BA_ "U_T6_MCA_MY2020_Tx" SG_ 533 AutoEpbZoomView_B_Stat 1;
BA_ "GenSigSendType" SG_ 533 AutoEpbZoomView_B_Stat 3;
BA_ "U_CD542_MY2021_Tx" SG_ 533 ClrExitAsstEnbl_D_RqMnu 1;
BA_ "U_CD764_MY2022_Tx" SG_ 533 ClrExitAsstEnbl_D_RqMnu 1;
BA_ "U_U55X_MY2022_Tx" SG_ 533 ClrExitAsstEnbl_D_RqMnu 1;
BA_ "GenSigSendType" SG_ 533 ClrExitAsstEnbl_D_RqMnu 3;
BA_ "U_T6_MCA_MY2020_Tx" SG_ 533 PaakMyKey_D_Rq 1;
BA_ "U_P702_MY2021_Tx" SG_ 533 PaakMyKey_D_Rq 1;
BA_ "U_U55X_MY2022_Tx" SG_ 533 PaakMyKey_D_Rq 1;
BA_ "U_CD542_MY2021_Tx" SG_ 533 PaakMyKey_D_Rq 1;
BA_ "GenSigSendType" SG_ 533 PaakMyKey_D_Rq 3;
BA_ "U_U55X_MY2022_Tx" SG_ 533 AutoEpbButtn_B_Stat 1;
BA_ "U_CD542_MY2021_Tx" SG_ 533 AutoEpbButtn_B_Stat 1;
BA_ "U_T6_MCA_MY2020_Tx" SG_ 533 AutoEpbButtn_B_Stat 1;
BA_ "GenSigSendType" SG_ 533 AutoEpbButtn_B_Stat 3;
BA_ "U_T6_MCA_MY2020_Tx" SG_ 533 TrlrAidMde_D_Rq 1;
BA_ "U_P702_MY2021_Tx" SG_ 533 TrlrAidMde_D_Rq 1;
BA_ "U_U55X_MY2022_Tx" SG_ 533 TrlrAidMde_D_Rq 1;
BA_ "U_CD542_MY2021_Tx" SG_ 533 TrlrAidMde_D_Rq 1;
BA_ "GenSigSendType" SG_ 533 TrlrAidMde_D_Rq 3;
BA_ "U_T6_MCA_MY2020_Tx" SG_ 533 TCU_Init_Actvtn_St 1;
BA_ "U_P702_MY2021_Tx" SG_ 533 TCU_Init_Actvtn_St 1;
BA_ "U_U55X_MY2022_Tx" SG_ 533 TCU_Init_Actvtn_St 1;
BA_ "U_CD542_MY2021_Tx" SG_ 533 TCU_Init_Actvtn_St 1;
BA_ "GenSigSendType" SG_ 533 TCU_Init_Actvtn_St 3;
BA_ "U_T6_MCA_MY2020_Tx" SG_ 533 TCU_Final_Actvtn_St 1;
BA_ "U_P702_MY2021_Tx" SG_ 533 TCU_Final_Actvtn_St 1;
BA_ "U_U55X_MY2022_Tx" SG_ 533 TCU_Final_Actvtn_St 1;
BA_ "U_CD542_MY2021_Tx" SG_ 533 TCU_Final_Actvtn_St 1;
BA_ "GenSigSendType" SG_ 533 TCU_Final_Actvtn_St 3;
BA_ "U_U55X_MY2022_Tx" SG_ 533 DcacPw_D_Rq 1;
BA_ "U_CD542_MY2021_Tx" SG_ 533 DcacPw_D_Rq 1;
BA_ "GenSigSendType" SG_ 533 DcacPw_D_Rq 3;
BA_ "U_U55X_MY2022_Tx" SG_ 533 DcacPwReset_B_Rq 1;
BA_ "U_CD542_MY2021_Tx" SG_ 533 DcacPwReset_B_Rq 1;
BA_ "GenSigSendType" SG_ 533 DcacPwReset_B_Rq 3;
BA_ "U_CD764_MY2022_Tx" SG_ 533 LghtAmbDrvMde_D_Rq 1;
BA_ "U_U55X_MY2022_Tx" SG_ 533 LghtAmbDrvMde_D_Rq 1;
BA_ "U_CD542_MY2021_Tx" SG_ 533 LghtAmbDrvMde_D_Rq 1;
BA_ "U_T6_MCA_MY2020_Tx" SG_ 533 LghtAmbDrvMde_D_Rq 1;
BA_ "GenSigSendType" SG_ 533 LghtAmbDrvMde_D_Rq 3;
BA_ "WakeupSignal" SG_ 533 LghtAmbDrvMde_D_Rq 1;
BA_ "U_T6_MCA_MY2020_Tx" SG_ 533 OtaTrg_D_Stat 1;
BA_ "U_P702_MY2021_Tx" SG_ 533 OtaTrg_D_Stat 1;
BA_ "U_U55X_MY2022_Tx" SG_ 533 OtaTrg_D_Stat 1;
BA_ "U_CD542_MY2021_Tx" SG_ 533 OtaTrg_D_Stat 1;
BA_ "GenSigSendType" SG_ 533 OtaTrg_D_Stat 3;
BA_ "U_U55X_MY2022_Tx" SG_ 533 DcacPwLoButtn_B_Stat 1;
BA_ "U_CD542_MY2021_Tx" SG_ 533 DcacPwLoButtn_B_Stat 1;
BA_ "GenSigSendType" SG_ 533 DcacPwLoButtn_B_Stat 3;
BA_ "U_U55X_MY2022_Tx" SG_ 533 DcacPwOffButtn_B_Stat 1;
BA_ "U_CD542_MY2021_Tx" SG_ 533 DcacPwOffButtn_B_Stat 1;
BA_ "GenSigSendType" SG_ 533 DcacPwOffButtn_B_Stat 3;
BA_ "U_U55X_MY2022_Tx" SG_ 533 DcacPwHiButtn_B_Stat 1;
BA_ "U_CD542_MY2021_Tx" SG_ 533 DcacPwHiButtn_B_Stat 1;
BA_ "GenSigSendType" SG_ 533 DcacPwHiButtn_B_Stat 3;
BA_ "U_U55X_MY2022_Tx" SG_ 533 DcacPwResetButtn_B_Stat 1;
BA_ "U_CD542_MY2021_Tx" SG_ 533 DcacPwResetButtn_B_Stat 1;
BA_ "GenSigSendType" SG_ 533 DcacPwResetButtn_B_Stat 3;
BA_ "U_U55X_MY2022_Tx" SG_ 533 DcacPwButtn_B_Falt 1;
BA_ "U_CD542_MY2021_Tx" SG_ 533 DcacPwButtn_B_Falt 1;
BA_ "GenSigSendType" SG_ 533 DcacPwButtn_B_Falt 3;
BA_ "U_T6_MCA_MY2020_Tx" SG_ 533 OnbChrgGoTTouch_D_Rq 1;
BA_ "U_P702_MY2021_Tx" SG_ 533 OnbChrgGoTTouch_D_Rq 1;
BA_ "U_U55X_MY2022_Tx" SG_ 533 OnbChrgGoTTouch_D_Rq 1;
BA_ "U_CD542_MY2021_Tx" SG_ 533 OnbChrgGoTTouch_D_Rq 1;
BA_ "GenSigSendType" SG_ 533 OnbChrgGoTTouch_D_Rq 3;
BA_ "U_U55X_MY2022_Tx" SG_ 533 OnbChrgGoTPrcond_D_Rq 1;
BA_ "U_CD542_MY2021_Tx" SG_ 533 OnbChrgGoTPrcond_D_Rq 1;
BA_ "U_T6_MCA_MY2020_Tx" SG_ 533 OnbChrgGoTPrcond_D_Rq 1;
BA_ "U_P702_MY2021_Tx" SG_ 533 OnbChrgGoTPrcond_D_Rq 1;
BA_ "GenSigSendType" SG_ 533 OnbChrgGoTPrcond_D_Rq 3;
BA_ "U_U55X_MY2022_Tx" SG_ 533 OnbChrgGoTOn_D_Rq 1;
BA_ "U_CD542_MY2021_Tx" SG_ 533 OnbChrgGoTOn_D_Rq 1;
BA_ "U_T6_MCA_MY2020_Tx" SG_ 533 OnbChrgGoTOn_D_Rq 1;
BA_ "U_P702_MY2021_Tx" SG_ 533 OnbChrgGoTOn_D_Rq 1;
BA_ "GenSigSendType" SG_ 533 OnbChrgGoTOn_D_Rq 3;
BA_ "GenSigStartValue" SG_ 533 OnbChrgGoTOn_D_Rq 2;
BA_ "GenSigStartValueInteger" SG_ 533 OnbChrgGoTOn_D_Rq 2;
BA_ "U_U55X_MY2022_Tx" SG_ 533 OnbChrgGoTMnte_D_Rq 1;
BA_ "U_CD542_MY2021_Tx" SG_ 533 OnbChrgGoTMnte_D_Rq 1;
BA_ "U_T6_MCA_MY2020_Tx" SG_ 533 OnbChrgGoTMnte_D_Rq 1;
BA_ "U_P702_MY2021_Tx" SG_ 533 OnbChrgGoTMnte_D_Rq 1;
BA_ "U_U55X_MY2022_Tx" SG_ 533 OnbChrgGoTHr_T_Rq 1;
BA_ "U_CD542_MY2021_Tx" SG_ 533 OnbChrgGoTHr_T_Rq 1;
BA_ "U_T6_MCA_MY2020_Tx" SG_ 533 OnbChrgGoTHr_T_Rq 1;
BA_ "U_P702_MY2021_Tx" SG_ 533 OnbChrgGoTHr_T_Rq 1;
BA_ "GenSigStartValue" SG_ 533 OnbChrgGoTHr_T_Rq 30;
BA_ "GenSigStartValueInteger" SG_ 533 OnbChrgGoTHr_T_Rq 30;
BA_ "U_U55X_MY2022_Tx" SG_ 533 OnbChrgGoTExtHtr_D_Rq 1;
BA_ "U_CD542_MY2021_Tx" SG_ 533 OnbChrgGoTExtHtr_D_Rq 1;
BA_ "U_T6_MCA_MY2020_Tx" SG_ 533 OnbChrgGoTExtHtr_D_Rq 1;
BA_ "U_P702_MY2021_Tx" SG_ 533 OnbChrgGoTExtHtr_D_Rq 1;
BA_ "GenSigSendType" SG_ 533 OnbChrgGoTExtHtr_D_Rq 3;
BA_ "U_U55X_MY2022_Tx" SG_ 533 OnbChrgGoTElement_D_Rq 1;
BA_ "U_CD542_MY2021_Tx" SG_ 533 OnbChrgGoTElement_D_Rq 1;
BA_ "U_T6_MCA_MY2020_Tx" SG_ 533 OnbChrgGoTElement_D_Rq 1;
BA_ "U_P702_MY2021_Tx" SG_ 533 OnbChrgGoTElement_D_Rq 1;
BA_ "GenSigSendType" SG_ 533 OnbChrgGoTElement_D_Rq 3;
BA_ "U_U55X_MY2022_Tx" SG_ 533 OnbChrgGoTDelete_B_Rq 1;
BA_ "U_CD542_MY2021_Tx" SG_ 533 OnbChrgGoTDelete_B_Rq 1;
BA_ "U_T6_MCA_MY2020_Tx" SG_ 533 OnbChrgGoTDelete_B_Rq 1;
BA_ "U_P702_MY2021_Tx" SG_ 533 OnbChrgGoTDelete_B_Rq 1;
BA_ "GenSigSendType" SG_ 533 OnbChrgGoTDelete_B_Rq 3;
BA_ "U_U55X_MY2022_Tx" SG_ 533 OnbChrgClearAll_B_Rq 1;
BA_ "U_CD542_MY2021_Tx" SG_ 533 OnbChrgClearAll_B_Rq 1;
BA_ "U_T6_MCA_MY2020_Tx" SG_ 533 OnbChrgClearAll_B_Rq 1;
BA_ "U_P702_MY2021_Tx" SG_ 533 OnbChrgClearAll_B_Rq 1;
BA_ "GenSigSendType" SG_ 533 OnbChrgClearAll_B_Rq 3;
BA_ "U_U55X_MY2022_Tx" SG_ 533 OnbChrgGoTUpdate_B_Rq 1;
BA_ "U_CD542_MY2021_Tx" SG_ 533 OnbChrgGoTUpdate_B_Rq 1;
BA_ "U_T6_MCA_MY2020_Tx" SG_ 533 OnbChrgGoTUpdate_B_Rq 1;
BA_ "U_P702_MY2021_Tx" SG_ 533 OnbChrgGoTUpdate_B_Rq 1;
BA_ "U_CD764_MY2022_Rx" SG_ 533 OnbChrgGoTUpdate_B_Rq 1;
BA_ "U_U55X_MY2022_Rx" SG_ 533 OnbChrgGoTUpdate_B_Rq 1;
BA_ "U_CD542_MY2021_Rx" SG_ 533 OnbChrgGoTUpdate_B_Rq 1;
BA_ "ECGUsedRxSignal" SG_ 533 OnbChrgGoTUpdate_B_Rq 1;
BA_ "U_T6_MCA_MY2020_Rx" SG_ 533 OnbChrgGoTUpdate_B_Rq 1;
BA_ "GenSigSendType" SG_ 533 OnbChrgGoTUpdate_B_Rq 3;
BA_ "U_U55X_MY2022_Tx" SG_ 533 TrlrAlarmButtn_B_Stat 1;
BA_ "U_CD542_MY2021_Tx" SG_ 533 TrlrAlarmButtn_B_Stat 1;
BA_ "U_T6_MCA_MY2020_Tx" SG_ 533 TrlrAlarmButtn_B_Stat 1;
BA_ "U_U55X_MY2022_Rx" SG_ 533 TrlrAlarmButtn_B_Stat 1;
BA_ "U_T6_MCA_MY2020_Rx" SG_ 533 TrlrAlarmButtn_B_Stat 1;
BA_ "GenSigSendType" SG_ 533 TrlrAlarmButtn_B_Stat 3;
BA_ "U_U55X_MY2022_Tx" SG_ 533 DcacMdeButtn_B_Stat 1;
BA_ "U_CD542_MY2021_Tx" SG_ 533 DcacMdeButtn_B_Stat 1;
BA_ "GenSigSendType" SG_ 533 DcacMdeButtn_B_Stat 3;
BA_ "U_U55X_MY2022_Tx" SG_ 533 DcacGfciTestBttn_B_Stat 1;
BA_ "U_CD542_MY2021_Tx" SG_ 533 DcacGfciTestBttn_B_Stat 1;
BA_ "GenSigSendType" SG_ 533 DcacGfciTestBttn_B_Stat 3;
BA_ "U_U55X_MY2022_Tx" SG_ 533 TrlrBrkGain_No_Rq 1;
BA_ "U_CD542_MY2021_Tx" SG_ 533 TrlrBrkGain_No_Rq 1;
BA_ "U_T6_MCA_MY2020_Tx" SG_ 533 TrlrBrkGain_No_Rq 1;
BA_ "U_U55X_MY2022_Rx" SG_ 533 TrlrBrkGain_No_Rq 1;
BA_ "U_T6_MCA_MY2020_Rx" SG_ 533 TrlrBrkGain_No_Rq 1;
BA_ "GenSigSendType" SG_ 533 TrlrBrkGain_No_Rq 3;
BA_ "U_U55X_MY2022_Tx" SG_ 533 TrlrHitch_D_RqMnu 1;
BA_ "U_CD542_MY2021_Tx" SG_ 533 TrlrHitch_D_RqMnu 1;
BA_ "U_T6_MCA_MY2020_Tx" SG_ 533 TrlrHitch_D_RqMnu 1;
BA_ "GenSigSendType" SG_ 533 TrlrHitch_D_RqMnu 3;
BA_ "U_U55X_MY2022_Tx" SG_ 533 DcacPwButtn_B_Stat 1;
BA_ "U_CD542_MY2021_Tx" SG_ 533 DcacPwButtn_B_Stat 1;
BA_ "GenSigSendType" SG_ 533 DcacPwButtn_B_Stat 3;
BA_ "U_CD764_MY2022_Rx" SG_ 1184 APIM_TCU_Word_Rx 1;
BA_ "U_U55X_MY2022_Rx" SG_ 1184 APIM_TCU_Word_Rx 1;
BA_ "U_CD542_MY2021_Rx" SG_ 1184 APIM_TCU_Word_Rx 1;
BA_ "U_T6_MCA_MY2020_Rx" SG_ 1184 APIM_TCU_Word_Rx 1;
BA_ "U_P702_MY2021_Rx" SG_ 1184 APIM_TCU_Word_Rx 1;
BA_ "U_U55X_MY2022_Tx" SG_ 801 CDWarnChime_St 1;
BA_ "U_CD542_MY2021_Tx" SG_ 801 CDWarnChime_St 1;
BA_ "U_T6_MCA_MY2020_Tx" SG_ 801 CDWarnChime_St 1;
BA_ "U_P702_MY2021_Tx" SG_ 801 CDWarnChime_St 1;
BA_ "U_CD764_MY2022_Rx" SG_ 801 CDWarnChime_St 1;
BA_ "U_T6_MCA_MY2020_Rx" SG_ 801 CDWarnChime_St 1;
BA_ "GenSigSendType" SG_ 801 CDWarnChime_St 3;
BA_ "U_U55X_MY2022_Tx" SG_ 801 SoftWarning 1;
BA_ "U_CD542_MY2021_Tx" SG_ 801 SoftWarning 1;
BA_ "U_T6_MCA_MY2020_Tx" SG_ 801 SoftWarning 1;
BA_ "U_P702_MY2021_Tx" SG_ 801 SoftWarning 1;
BA_ "U_CD764_MY2022_Rx" SG_ 801 SoftWarning 1;
BA_ "U_T6_MCA_MY2020_Rx" SG_ 801 SoftWarning 1;
BA_ "GenSigSendType" SG_ 801 SoftWarning 3;
BA_ "U_U55X_MY2022_Tx" SG_ 801 HardWarning 1;
BA_ "U_CD542_MY2021_Tx" SG_ 801 HardWarning 1;
BA_ "U_T6_MCA_MY2020_Tx" SG_ 801 HardWarning 1;
BA_ "U_P702_MY2021_Tx" SG_ 801 HardWarning 1;
BA_ "U_CD764_MY2022_Rx" SG_ 801 HardWarning 1;
BA_ "U_T6_MCA_MY2020_Rx" SG_ 801 HardWarning 1;
BA_ "GenSigSendType" SG_ 801 HardWarning 3;
BA_ "U_U55X_MY2022_Tx" SG_ 801 InfoWarning 1;
BA_ "U_CD542_MY2021_Tx" SG_ 801 InfoWarning 1;
BA_ "U_T6_MCA_MY2020_Tx" SG_ 801 InfoWarning 1;
BA_ "U_P702_MY2021_Tx" SG_ 801 InfoWarning 1;
BA_ "U_CD764_MY2022_Rx" SG_ 801 InfoWarning 1;
BA_ "U_T6_MCA_MY2020_Rx" SG_ 801 InfoWarning 1;
BA_ "GenSigSendType" SG_ 801 InfoWarning 3;
BA_ "U_U55X_MY2022_Tx" SG_ 801 DrvDsplyPalette_D_Stat 1;
BA_ "U_CD542_MY2021_Tx" SG_ 801 DrvDsplyPalette_D_Stat 1;
BA_ "U_T6_MCA_MY2020_Tx" SG_ 801 DrvDsplyPalette_D_Stat 1;
BA_ "U_CD764_MY2022_Rx" SG_ 801 DrvDsplyPalette_D_Stat 1;
BA_ "U_T6_MCA_MY2020_Rx" SG_ 801 DrvDsplyPalette_D_Stat 1;
BA_ "GenSigSendType" SG_ 801 DrvDsplyPalette_D_Stat 3;
BA_ "U_U55X_MY2022_Tx" SG_ 878 ClimtSyncRear2_B_Stat 1;
BA_ "GenSigSendType" SG_ 878 ClimtSyncRear2_B_Stat 3;
BA_ "U_U55X_MY2022_Tx" SG_ 878 ClimtStHeatRr2_B_Stat 1;
BA_ "GenSigSendType" SG_ 878 ClimtStHeatRr2_B_Stat 3;
BA_ "U_U55X_MY2022_Tx" SG_ 878 ClimtStHeatRl2_B_Stat 1;
BA_ "GenSigSendType" SG_ 878 ClimtStHeatRl2_B_Stat 3;
BA_ "U_U55X_MY2022_Tx" SG_ 878 ClimtStCoolRr2_B_Stat 1;
BA_ "GenSigSendType" SG_ 878 ClimtStCoolRr2_B_Stat 3;
BA_ "U_U55X_MY2022_Tx" SG_ 878 ClimtStCoolRl2_B_Stat 1;
BA_ "GenSigSendType" SG_ 878 ClimtStCoolRl2_B_Stat 3;
BA_ "U_U55X_MY2022_Tx" SG_ 878 ClimtSeatRr2_D_Rq 1;
BA_ "GenSigSendType" SG_ 878 ClimtSeatRr2_D_Rq 3;
BA_ "U_U55X_MY2022_Tx" SG_ 878 ClimtSeatRl2_D_Rq 1;
BA_ "GenSigSendType" SG_ 878 ClimtSeatRl2_D_Rq 3;
BA_ "U_U55X_MY2022_Tx" SG_ 878 ClimtRrTe3rd2_D_Stat 1;
BA_ "GenSigSendType" SG_ 878 ClimtRrTe3rd2_D_Stat 3;
BA_ "U_U55X_MY2022_Tx" SG_ 878 ClimtRrPw3rd2_B_Stat 1;
BA_ "GenSigSendType" SG_ 878 ClimtRrPw3rd2_B_Stat 3;
BA_ "U_U55X_MY2022_Tx" SG_ 878 ClimtRrPnl3rd2_B_Stat 1;
BA_ "GenSigSendType" SG_ 878 ClimtRrPnl3rd2_B_Stat 3;
BA_ "U_U55X_MY2022_Tx" SG_ 878 ClimtRrPf3rd2_B_Stat 1;
BA_ "GenSigSendType" SG_ 878 ClimtRrPf3rd2_B_Stat 3;
BA_ "U_U55X_MY2022_Tx" SG_ 878 ClimtRrFlr3rd2_B_Stat 1;
BA_ "GenSigSendType" SG_ 878 ClimtRrFlr3rd2_B_Stat 3;
BA_ "U_U55X_MY2022_Tx" SG_ 878 ClimtRrBlwr3rd2_D_Stat 1;
BA_ "GenSigSendType" SG_ 878 ClimtRrBlwr3rd2_D_Stat 3;
BA_ "U_U55X_MY2022_Tx" SG_ 878 ClimtRrAuto3rd2_B_Stat 1;
BA_ "GenSigSendType" SG_ 878 ClimtRrAuto3rd2_B_Stat 3;
BA_ "U_U55X_MY2022_Tx" SG_ 878 ClimtRearView2_D_Stat 1;
BA_ "GenSigSendType" SG_ 878 ClimtRearView2_D_Stat 3;
BA_ "U_U55X_MY2022_Tx" SG_ 878 ClimtRearTe2_D_Stat 1;
BA_ "GenSigSendType" SG_ 878 ClimtRearTe2_D_Stat 3;
BA_ "U_U55X_MY2022_Tx" SG_ 878 ClimtRearTe2_An_Actl 1;
BA_ "GenSigSendType" SG_ 878 ClimtRearTe2_An_Actl 3;
BA_ "GenSigStartValue" SG_ 878 ClimtRearTe2_An_Actl 511;
BA_ "GenSigStartValueInteger" SG_ 878 ClimtRearTe2_An_Actl 511;
BA_ "U_U55X_MY2022_Tx" SG_ 878 ClimtRearPw2_B_Stat 1;
BA_ "GenSigSendType" SG_ 878 ClimtRearPw2_B_Stat 3;
BA_ "U_U55X_MY2022_Tx" SG_ 878 ClimtRearPnlFlr2_B_Stat 1;
BA_ "GenSigSendType" SG_ 878 ClimtRearPnlFlr2_B_Stat 3;
BA_ "U_U55X_MY2022_Tx" SG_ 878 ClimtRearPnl2_B_Stat 1;
BA_ "GenSigSendType" SG_ 878 ClimtRearPnl2_B_Stat 3;
BA_ "U_U55X_MY2022_Tx" SG_ 878 ClimtRearFlr2_B_Stat 1;
BA_ "GenSigSendType" SG_ 878 ClimtRearFlr2_B_Stat 3;
BA_ "U_U55X_MY2022_Tx" SG_ 878 ClimtRearBlwr2_D_Stat 1;
BA_ "GenSigSendType" SG_ 878 ClimtRearBlwr2_D_Stat 3;
BA_ "U_U55X_MY2022_Tx" SG_ 878 ClimtRearBlwr2_An_Actl 1;
BA_ "GenSigSendType" SG_ 878 ClimtRearBlwr2_An_Actl 3;
BA_ "GenSigStartValue" SG_ 878 ClimtRearBlwr2_An_Actl 511;
BA_ "GenSigStartValueInteger" SG_ 878 ClimtRearBlwr2_An_Actl 511;
BA_ "U_U55X_MY2022_Tx" SG_ 878 ClimtRearAuto2_B_Stat 1;
BA_ "GenSigSendType" SG_ 878 ClimtRearAuto2_B_Stat 3;
BA_ "U_U55X_MY2022_Rx" SG_ 258 GPS_Track_D_Rq 1;
BA_ "U_CD542_MY2021_Rx" SG_ 258 GPS_Track_D_Rq 1;
BA_ "U_P702_MY2021_Rx" SG_ 258 GPS_Track_D_Rq 1;
BA_ "U_U55X_MY2022_Rx" SG_ 258 APIM_SwPartNo_D_Rq 1;
BA_ "U_CD542_MY2021_Rx" SG_ 258 APIM_SwPartNo_D_Rq 1;
BA_ "U_T6_MCA_MY2020_Rx" SG_ 258 APIM_SwPartNo_D_Rq 1;
BA_ "U_P702_MY2021_Rx" SG_ 258 APIM_SwPartNo_D_Rq 1;
BA_ "U_U55X_MY2022_Rx" SG_ 258 TCU_Init_Actvtn_Rq 1;
BA_ "U_CD542_MY2021_Rx" SG_ 258 TCU_Init_Actvtn_Rq 1;
BA_ "U_P702_MY2021_Rx" SG_ 258 TCU_Init_Actvtn_Rq 1;
BA_ "U_U55X_MY2022_Rx" SG_ 258 TCU_Final_Actvtn_Rq 1;
BA_ "U_CD542_MY2021_Rx" SG_ 258 TCU_Final_Actvtn_Rq 1;
BA_ "U_P702_MY2021_Rx" SG_ 258 TCU_Final_Actvtn_Rq 1;
BA_ "U_CD764_MY2022_Tx" SG_ 1192 APIM_TCU_Word_Tx 1;
BA_ "U_U55X_MY2022_Tx" SG_ 1192 APIM_TCU_Word_Tx 1;
BA_ "U_CD542_MY2021_Tx" SG_ 1192 APIM_TCU_Word_Tx 1;
BA_ "U_T6_MCA_MY2020_Tx" SG_ 1192 APIM_TCU_Word_Tx 1;
BA_ "U_P702_MY2021_Tx" SG_ 1192 APIM_TCU_Word_Tx 1;
BA_ "MetaData" SG_ 1247 StopLampBRqTrlrAft_No_Cs 1;
BA_ "MetaData" SG_ 1247 StopLampBRqTrlrAft_No_Cnt 1;
BA_ "U_CD764_MY2022_Tx" SG_ 413 LBS1_ParentID 1;
BA_ "U_U55X_MY2022_Tx" SG_ 413 LBS1_ParentID 1;
BA_ "U_CD542_MY2021_Tx" SG_ 413 LBS1_ParentID 1;
BA_ "U_U55X_MY2022_Rx" SG_ 413 LBS1_ParentID 1;
BA_ "U_CD542_MY2021_Rx" SG_ 413 LBS1_ParentID 1;
BA_ "U_CD764_MY2022_Tx" SG_ 413 LBS1_ListStatus 1;
BA_ "U_U55X_MY2022_Tx" SG_ 413 LBS1_ListStatus 1;
BA_ "U_CD542_MY2021_Tx" SG_ 413 LBS1_ListStatus 1;
BA_ "U_CD542_MY2021_Rx" SG_ 413 LBS1_ListStatus 1;
BA_ "U_U55X_MY2022_Rx" SG_ 413 LBS1_ListStatus 1;
BA_ "GenSigSendType" SG_ 413 LBS1_ListStatus 3;
BA_ "U_CD764_MY2022_Tx" SG_ 413 LBS1_ListServer 1;
BA_ "U_U55X_MY2022_Tx" SG_ 413 LBS1_ListServer 1;
BA_ "U_CD542_MY2021_Tx" SG_ 413 LBS1_ListServer 1;
BA_ "U_CD542_MY2021_Rx" SG_ 413 LBS1_ListServer 1;
BA_ "U_U55X_MY2022_Rx" SG_ 413 LBS1_ListServer 1;
BA_ "U_CD764_MY2022_Tx" SG_ 413 LBS1_ListID 1;
BA_ "U_U55X_MY2022_Tx" SG_ 413 LBS1_ListID 1;
BA_ "U_CD542_MY2021_Tx" SG_ 413 LBS1_ListID 1;
BA_ "U_CD542_MY2021_Rx" SG_ 413 LBS1_ListID 1;
BA_ "U_U55X_MY2022_Rx" SG_ 413 LBS1_ListID 1;
BA_ "U_CD764_MY2022_Tx" SG_ 413 LBS1_EntryIndex 1;
BA_ "U_U55X_MY2022_Tx" SG_ 413 LBS1_EntryIndex 1;
BA_ "U_CD542_MY2021_Tx" SG_ 413 LBS1_EntryIndex 1;
BA_ "U_CD542_MY2021_Rx" SG_ 413 LBS1_EntryIndex 1;
BA_ "U_U55X_MY2022_Rx" SG_ 413 LBS1_EntryIndex 1;
BA_ "GenSigSendType" SG_ 556 DrvAsstMnuButtn_B_Stat 3;
BA_ "U_CD542_MY2021_Rx" SG_ 556 Manual_Temp_Setting 1;
BA_ "GenSigSendType" SG_ 556 Manual_Temp_Setting 3;
BA_ "U_U55X_MY2022_Rx" SG_ 556 EFP_Bezel_Diag_St 1;
BA_ "U_CD764_MY2022_Rx" SG_ 556 EFP_Bezel_Diag_St 1;
BA_ "GenSigSendType" SG_ 556 EFP_Bezel_Diag_St 3;
BA_ "U_U55X_MY2022_Rx" SG_ 556 Bezel_Beep_St 1;
BA_ "U_CD764_MY2022_Rx" SG_ 556 Bezel_Beep_St 1;
BA_ "GenSigSendType" SG_ 556 Bezel_Beep_St 3;
BA_ "U_U55X_MY2022_Rx" SG_ 556 Bezel_Beeps_Supported 1;
BA_ "U_CD764_MY2022_Rx" SG_ 556 Bezel_Beeps_Supported 1;
BA_ "GenSigSendType" SG_ 556 Bezel_Beeps_Supported 3;
BA_ "GenSigSendType" SG_ 556 PassRstrnInd_Stat 3;
BA_ "U_U55X_MY2022_Tx" SG_ 259 SDARS_CurrCATlstSize_Rq 1;
BA_ "U_CD542_MY2021_Tx" SG_ 259 SDARS_CurrCATlstSize_Rq 1;
BA_ "U_T6_MCA_MY2020_Tx" SG_ 259 SDARS_CurrCATlstSize_Rq 1;
BA_ "U_P702_MY2021_Tx" SG_ 259 SDARS_CurrCATlstSize_Rq 1;
BA_ "U_CD542_MY2021_Rx" SG_ 259 SDARS_CurrCATlstSize_Rq 1;
BA_ "U_T6_MCA_MY2020_Rx" SG_ 259 SDARS_CurrCATlstSize_Rq 1;
BA_ "U_P702_MY2021_Rx" SG_ 259 SDARS_CurrCATlstSize_Rq 1;
BA_ "U_U55X_MY2022_Tx" SG_ 259 SDARS_CurrCATlistInd_Rq 1;
BA_ "U_CD542_MY2021_Tx" SG_ 259 SDARS_CurrCATlistInd_Rq 1;
BA_ "U_T6_MCA_MY2020_Tx" SG_ 259 SDARS_CurrCATlistInd_Rq 1;
BA_ "U_P702_MY2021_Tx" SG_ 259 SDARS_CurrCATlistInd_Rq 1;
BA_ "U_CD542_MY2021_Rx" SG_ 259 SDARS_CurrCATlistInd_Rq 1;
BA_ "U_T6_MCA_MY2020_Rx" SG_ 259 SDARS_CurrCATlistInd_Rq 1;
BA_ "U_P702_MY2021_Rx" SG_ 259 SDARS_CurrCATlistInd_Rq 1;
BA_ "GenSigSendType" SG_ 259 SDARS_CurrCATlistInd_Rq 3;
BA_ "U_U55X_MY2022_Tx" SG_ 259 SDARS_ChipControl_Rq 1;
BA_ "U_CD542_MY2021_Tx" SG_ 259 SDARS_ChipControl_Rq 1;
BA_ "U_T6_MCA_MY2020_Tx" SG_ 259 SDARS_ChipControl_Rq 1;
BA_ "U_P702_MY2021_Tx" SG_ 259 SDARS_ChipControl_Rq 1;
BA_ "U_U55X_MY2022_Rx" SG_ 259 SDARS_ChipControl_Rq 1;
BA_ "U_CD542_MY2021_Rx" SG_ 259 SDARS_ChipControl_Rq 1;
BA_ "U_T6_MCA_MY2020_Rx" SG_ 259 SDARS_ChipControl_Rq 1;
BA_ "U_P702_MY2021_Rx" SG_ 259 SDARS_ChipControl_Rq 1;
BA_ "GenSigSendType" SG_ 259 SDARS_ChipControl_Rq 3;
BA_ "U_U55X_MY2022_Tx" SG_ 259 SDARS_AlertStatus_Rq 1;
BA_ "U_CD542_MY2021_Tx" SG_ 259 SDARS_AlertStatus_Rq 1;
BA_ "U_T6_MCA_MY2020_Tx" SG_ 259 SDARS_AlertStatus_Rq 1;
BA_ "U_P702_MY2021_Tx" SG_ 259 SDARS_AlertStatus_Rq 1;
BA_ "U_CD542_MY2021_Rx" SG_ 259 SDARS_AlertStatus_Rq 1;
BA_ "U_T6_MCA_MY2020_Rx" SG_ 259 SDARS_AlertStatus_Rq 1;
BA_ "U_P702_MY2021_Rx" SG_ 259 SDARS_AlertStatus_Rq 1;
BA_ "GenSigSendType" SG_ 259 SDARS_AlertStatus_Rq 3;
BA_ "U_U55X_MY2022_Tx" SG_ 538 MK_UserMyKeyCount_St 1;
BA_ "U_CD542_MY2021_Tx" SG_ 538 MK_UserMyKeyCount_St 1;
BA_ "U_T6_MCA_MY2020_Tx" SG_ 538 MK_UserMyKeyCount_St 1;
BA_ "U_CD542_MY2021_Rx" SG_ 538 MK_UserMyKeyCount_St 1;
BA_ "U_U55X_MY2022_Rx" SG_ 538 MK_UserMyKeyCount_St 1;
BA_ "U_T6_MCA_MY2020_Rx" SG_ 538 MK_UserMyKeyCount_St 1;
BA_ "U_P702_MY2021_Rx" SG_ 538 MK_UserMyKeyCount_St 1;
BA_ "GenSigSendType" SG_ 538 MK_UserMyKeyCount_St 3;
BA_ "U_U55X_MY2022_Tx" SG_ 538 MK_SpeedMinderConf_St 1;
BA_ "U_CD542_MY2021_Tx" SG_ 538 MK_SpeedMinderConf_St 1;
BA_ "U_T6_MCA_MY2020_Tx" SG_ 538 MK_SpeedMinderConf_St 1;
BA_ "U_CD542_MY2021_Rx" SG_ 538 MK_SpeedMinderConf_St 1;
BA_ "U_U55X_MY2022_Rx" SG_ 538 MK_SpeedMinderConf_St 1;
BA_ "U_T6_MCA_MY2020_Rx" SG_ 538 MK_SpeedMinderConf_St 1;
BA_ "U_P702_MY2021_Rx" SG_ 538 MK_SpeedMinderConf_St 1;
BA_ "GenSigSendType" SG_ 538 MK_SpeedMinderConf_St 3;
BA_ "U_U55X_MY2022_Tx" SG_ 538 MK_SpeedLimitConf_St 1;
BA_ "U_CD542_MY2021_Tx" SG_ 538 MK_SpeedLimitConf_St 1;
BA_ "U_T6_MCA_MY2020_Tx" SG_ 538 MK_SpeedLimitConf_St 1;
BA_ "U_CD542_MY2021_Rx" SG_ 538 MK_SpeedLimitConf_St 1;
BA_ "U_U55X_MY2022_Rx" SG_ 538 MK_SpeedLimitConf_St 1;
BA_ "U_T6_MCA_MY2020_Rx" SG_ 538 MK_SpeedLimitConf_St 1;
BA_ "U_P702_MY2021_Rx" SG_ 538 MK_SpeedLimitConf_St 1;
BA_ "GenSigSendType" SG_ 538 MK_SpeedLimitConf_St 3;
BA_ "U_U55X_MY2022_Tx" SG_ 538 MK_ESCRestrictConf_St 1;
BA_ "U_CD542_MY2021_Tx" SG_ 538 MK_ESCRestrictConf_St 1;
BA_ "U_T6_MCA_MY2020_Tx" SG_ 538 MK_ESCRestrictConf_St 1;
BA_ "GenSigSendType" SG_ 538 MK_ESCRestrictConf_St 3;
BA_ "U_U55X_MY2022_Tx" SG_ 538 MK_ECalRestrictConf_St 1;
BA_ "U_CD542_MY2021_Tx" SG_ 538 MK_ECalRestrictConf_St 1;
BA_ "U_T6_MCA_MY2020_Tx" SG_ 538 MK_ECalRestrictConf_St 1;
BA_ "U_CD542_MY2021_Rx" SG_ 538 MK_ECalRestrictConf_St 1;
BA_ "U_U55X_MY2022_Rx" SG_ 538 MK_ECalRestrictConf_St 1;
BA_ "U_T6_MCA_MY2020_Rx" SG_ 538 MK_ECalRestrictConf_St 1;
BA_ "U_P702_MY2021_Rx" SG_ 538 MK_ECalRestrictConf_St 1;
BA_ "GenSigSendType" SG_ 538 MK_ECalRestrictConf_St 3;
BA_ "U_U55X_MY2022_Tx" SG_ 538 MK_DNDRestrictConf_St 1;
BA_ "U_CD542_MY2021_Tx" SG_ 538 MK_DNDRestrictConf_St 1;
BA_ "U_T6_MCA_MY2020_Tx" SG_ 538 MK_DNDRestrictConf_St 1;
BA_ "U_CD542_MY2021_Rx" SG_ 538 MK_DNDRestrictConf_St 1;
BA_ "U_U55X_MY2022_Rx" SG_ 538 MK_DNDRestrictConf_St 1;
BA_ "U_T6_MCA_MY2020_Rx" SG_ 538 MK_DNDRestrictConf_St 1;
BA_ "U_P702_MY2021_Rx" SG_ 538 MK_DNDRestrictConf_St 1;
BA_ "GenSigSendType" SG_ 538 MK_DNDRestrictConf_St 3;
BA_ "U_U55X_MY2022_Tx" SG_ 538 MK_AudioLimitConfig_St 1;
BA_ "U_CD542_MY2021_Tx" SG_ 538 MK_AudioLimitConfig_St 1;
BA_ "U_T6_MCA_MY2020_Tx" SG_ 538 MK_AudioLimitConfig_St 1;
BA_ "U_CD542_MY2021_Rx" SG_ 538 MK_AudioLimitConfig_St 1;
BA_ "U_U55X_MY2022_Rx" SG_ 538 MK_AudioLimitConfig_St 1;
BA_ "U_T6_MCA_MY2020_Rx" SG_ 538 MK_AudioLimitConfig_St 1;
BA_ "U_P702_MY2021_Rx" SG_ 538 MK_AudioLimitConfig_St 1;
BA_ "GenSigSendType" SG_ 538 MK_AudioLimitConfig_St 3;
BA_ "U_U55X_MY2022_Tx" SG_ 538 MK_AdminMyKeyCount_St 1;
BA_ "U_CD542_MY2021_Tx" SG_ 538 MK_AdminMyKeyCount_St 1;
BA_ "U_T6_MCA_MY2020_Tx" SG_ 538 MK_AdminMyKeyCount_St 1;
BA_ "U_CD542_MY2021_Rx" SG_ 538 MK_AdminMyKeyCount_St 1;
BA_ "U_U55X_MY2022_Rx" SG_ 538 MK_AdminMyKeyCount_St 1;
BA_ "U_T6_MCA_MY2020_Rx" SG_ 538 MK_AdminMyKeyCount_St 1;
BA_ "U_P702_MY2021_Rx" SG_ 538 MK_AdminMyKeyCount_St 1;
BA_ "GenSigSendType" SG_ 538 MK_AdminMyKeyCount_St 3;
BA_ "U_U55X_MY2022_Tx" SG_ 422 MK_UserMyKeyCount_Rsp 1;
BA_ "U_CD542_MY2021_Tx" SG_ 422 MK_UserMyKeyCount_Rsp 1;
BA_ "U_T6_MCA_MY2020_Tx" SG_ 422 MK_UserMyKeyCount_Rsp 1;
BA_ "U_CD542_MY2021_Rx" SG_ 422 MK_UserMyKeyCount_Rsp 1;
BA_ "U_U55X_MY2022_Rx" SG_ 422 MK_UserMyKeyCount_Rsp 1;
BA_ "U_T6_MCA_MY2020_Rx" SG_ 422 MK_UserMyKeyCount_Rsp 1;
BA_ "U_P702_MY2021_Rx" SG_ 422 MK_UserMyKeyCount_Rsp 1;
BA_ "GenSigSendType" SG_ 422 MK_UserMyKeyCount_Rsp 3;
BA_ "U_U55X_MY2022_Tx" SG_ 422 MK_MyKeyDrivenKm_Rsp 1;
BA_ "U_CD542_MY2021_Tx" SG_ 422 MK_MyKeyDrivenKm_Rsp 1;
BA_ "U_T6_MCA_MY2020_Tx" SG_ 422 MK_MyKeyDrivenKm_Rsp 1;
BA_ "U_CD542_MY2021_Rx" SG_ 422 MK_MyKeyDrivenKm_Rsp 1;
BA_ "U_U55X_MY2022_Rx" SG_ 422 MK_MyKeyDrivenKm_Rsp 1;
BA_ "U_T6_MCA_MY2020_Rx" SG_ 422 MK_MyKeyDrivenKm_Rsp 1;
BA_ "U_P702_MY2021_Rx" SG_ 422 MK_MyKeyDrivenKm_Rsp 1;
BA_ "GenSigSendType" SG_ 422 MK_MyKeyDrivenKm_Rsp 3;
BA_ "U_U55X_MY2022_Tx" SG_ 422 MK_CreateMyKey_Rsp 1;
BA_ "U_CD542_MY2021_Tx" SG_ 422 MK_CreateMyKey_Rsp 1;
BA_ "U_T6_MCA_MY2020_Tx" SG_ 422 MK_CreateMyKey_Rsp 1;
BA_ "U_CD542_MY2021_Rx" SG_ 422 MK_CreateMyKey_Rsp 1;
BA_ "U_U55X_MY2022_Rx" SG_ 422 MK_CreateMyKey_Rsp 1;
BA_ "U_T6_MCA_MY2020_Rx" SG_ 422 MK_CreateMyKey_Rsp 1;
BA_ "U_P702_MY2021_Rx" SG_ 422 MK_CreateMyKey_Rsp 1;
BA_ "GenSigSendType" SG_ 422 MK_CreateMyKey_Rsp 3;
BA_ "U_U55X_MY2022_Tx" SG_ 422 MK_AdminMyKeyCount_Rsp 1;
BA_ "U_CD542_MY2021_Tx" SG_ 422 MK_AdminMyKeyCount_Rsp 1;
BA_ "U_T6_MCA_MY2020_Tx" SG_ 422 MK_AdminMyKeyCount_Rsp 1;
BA_ "U_CD542_MY2021_Rx" SG_ 422 MK_AdminMyKeyCount_Rsp 1;
BA_ "U_U55X_MY2022_Rx" SG_ 422 MK_AdminMyKeyCount_Rsp 1;
BA_ "U_T6_MCA_MY2020_Rx" SG_ 422 MK_AdminMyKeyCount_Rsp 1;
BA_ "U_P702_MY2021_Rx" SG_ 422 MK_AdminMyKeyCount_Rsp 1;
BA_ "GenSigSendType" SG_ 422 MK_AdminMyKeyCount_Rsp 3;
BA_ "U_CD764_MY2022_Tx" SG_ 1020 CtrStkPersIndex2_D_Actl 1;
BA_ "U_U55X_MY2022_Tx" SG_ 1020 CtrStkPersIndex2_D_Actl 1;
BA_ "U_CD542_MY2021_Tx" SG_ 1020 CtrStkPersIndex2_D_Actl 1;
BA_ "U_CD764_MY2022_Rx" SG_ 1020 CtrStkPersIndex2_D_Actl 1;
BA_ "U_CD542_MY2021_Rx" SG_ 1020 CtrStkPersIndex2_D_Actl 1;
BA_ "GenSigSendType" SG_ 1020 CtrStkPersIndex2_D_Actl 3;
BA_ "GenSigStartValue" SG_ 1020 CtrStkPersIndex2_D_Actl 4;
BA_ "GenSigStartValueInteger" SG_ 1020 CtrStkPersIndex2_D_Actl 4;
BA_ "U_CD764_MY2022_Tx" SG_ 1020 CtrStkFeatConfig2Actl 1;
BA_ "U_U55X_MY2022_Tx" SG_ 1020 CtrStkFeatConfig2Actl 1;
BA_ "U_CD542_MY2021_Tx" SG_ 1020 CtrStkFeatConfig2Actl 1;
BA_ "U_CD764_MY2022_Rx" SG_ 1020 CtrStkFeatConfig2Actl 1;
BA_ "U_CD542_MY2021_Rx" SG_ 1020 CtrStkFeatConfig2Actl 1;
BA_ "GenSigSendType" SG_ 1020 CtrStkFeatConfig2Actl 3;
BA_ "U_CD764_MY2022_Tx" SG_ 1020 CtrStkFeat2NoActl 1;
BA_ "U_U55X_MY2022_Tx" SG_ 1020 CtrStkFeat2NoActl 1;
BA_ "U_CD542_MY2021_Tx" SG_ 1020 CtrStkFeat2NoActl 1;
BA_ "U_CD764_MY2022_Rx" SG_ 1020 CtrStkFeat2NoActl 1;
BA_ "U_CD542_MY2021_Rx" SG_ 1020 CtrStkFeat2NoActl 1;
BA_ "GenSigSendType" SG_ 1020 CtrStkFeat2NoActl 3;
BA_ "U_CD764_MY2022_Tx" SG_ 1020 CtrStkDsplyOp2_D_Rq 1;
BA_ "U_U55X_MY2022_Tx" SG_ 1020 CtrStkDsplyOp2_D_Rq 1;
BA_ "U_CD542_MY2021_Tx" SG_ 1020 CtrStkDsplyOp2_D_Rq 1;
BA_ "U_CD764_MY2022_Rx" SG_ 1020 CtrStkDsplyOp2_D_Rq 1;
BA_ "U_CD542_MY2021_Rx" SG_ 1020 CtrStkDsplyOp2_D_Rq 1;
BA_ "GenSigSendType" SG_ 1020 CtrStkDsplyOp2_D_Rq 3;
BA_ "U_CD764_MY2022_Tx" SG_ 1007 PersIndexIpc2_D_Actl 1;
BA_ "U_CD542_MY2021_Tx" SG_ 1007 PersIndexIpc2_D_Actl 1;
BA_ "U_U55X_MY2022_Rx" SG_ 1007 PersIndexIpc2_D_Actl 1;
BA_ "U_CD764_MY2022_Rx" SG_ 1007 PersIndexIpc2_D_Actl 1;
BA_ "GenSigSendType" SG_ 1007 PersIndexIpc2_D_Actl 3;
BA_ "GenSigStartValue" SG_ 1007 PersIndexIpc2_D_Actl 4;
BA_ "GenSigStartValueInteger" SG_ 1007 PersIndexIpc2_D_Actl 4;
BA_ "U_CD764_MY2022_Tx" SG_ 1007 FeatNoIpc2Actl 1;
BA_ "U_CD542_MY2021_Tx" SG_ 1007 FeatNoIpc2Actl 1;
BA_ "U_U55X_MY2022_Rx" SG_ 1007 FeatNoIpc2Actl 1;
BA_ "U_CD764_MY2022_Rx" SG_ 1007 FeatNoIpc2Actl 1;
BA_ "GenSigSendType" SG_ 1007 FeatNoIpc2Actl 3;
BA_ "U_CD764_MY2022_Tx" SG_ 1007 FeatConfigIpc2Actl 1;
BA_ "U_CD542_MY2021_Tx" SG_ 1007 FeatConfigIpc2Actl 1;
BA_ "U_U55X_MY2022_Rx" SG_ 1007 FeatConfigIpc2Actl 1;
BA_ "U_CD764_MY2022_Rx" SG_ 1007 FeatConfigIpc2Actl 1;
BA_ "GenSigSendType" SG_ 1007 FeatConfigIpc2Actl 3;
BA_ "U_T6_MCA_MY2020_Tx" SG_ 2008 TesterPhysicalResAPIM 1;
BA_ "U_P702_MY2021_Tx" SG_ 2008 TesterPhysicalResAPIM 1;
BA_ "U_CD764_MY2022_Tx" SG_ 2008 TesterPhysicalResAPIM 1;
BA_ "U_U55X_MY2022_Tx" SG_ 2008 TesterPhysicalResAPIM 1;
BA_ "U_CD542_MY2021_Tx" SG_ 2008 TesterPhysicalResAPIM 1;
BA_ "GenSigSendType" SG_ 2008 TesterPhysicalResAPIM 3;
BA_ "U_CD764_MY2022_Rx" SG_ 884 UltraFreshCabn_D_Stat 1;
BA_ "U_CD764_MY2022_Rx" SG_ 884 PmSnsCabn_D_Stat 1;
BA_ "U_CD542_MY2021_Rx" SG_ 884 PmSnsCabn_D_Stat 1;
BA_ "U_T6_MCA_MY2020_Rx" SG_ 884 PmSnsCabn_D_Stat 1;
BA_ "U_P702_MY2021_Rx" SG_ 884 PmSnsCabn_D_Stat 1;
BA_ "U_U55X_MY2022_Rx" SG_ 884 PmSnsCabn_D_Stat 1;
BA_ "GenSigStartValue" SG_ 884 PmSnsCabn_D_Stat 5;
BA_ "GenSigStartValueInteger" SG_ 884 PmSnsCabn_D_Stat 5;
BA_ "U_CD764_MY2022_Rx" SG_ 884 PmCabn_Conc_Actl 1;
BA_ "U_CD542_MY2021_Rx" SG_ 884 PmCabn_Conc_Actl 1;
BA_ "U_T6_MCA_MY2020_Rx" SG_ 884 PmCabn_Conc_Actl 1;
BA_ "U_P702_MY2021_Rx" SG_ 884 PmCabn_Conc_Actl 1;
BA_ "U_U55X_MY2022_Rx" SG_ 884 PmCabn_Conc_Actl 1;
BA_ "GenSigStartValue" SG_ 884 PmCabn_Conc_Actl 510;
BA_ "GenSigStartValueInteger" SG_ 884 PmCabn_Conc_Actl 510;
BA_ "U_CD764_MY2022_Rx" SG_ 884 PmCabn20Mnte_Conc_Actl 1;
BA_ "U_CD542_MY2021_Rx" SG_ 884 PmCabn20Mnte_Conc_Actl 1;
BA_ "U_T6_MCA_MY2020_Rx" SG_ 884 PmCabn20Mnte_Conc_Actl 1;
BA_ "U_P702_MY2021_Rx" SG_ 884 PmCabn20Mnte_Conc_Actl 1;
BA_ "U_U55X_MY2022_Rx" SG_ 884 PmCabn20Mnte_Conc_Actl 1;
BA_ "GenSigStartValue" SG_ 884 PmCabn20Mnte_Conc_Actl 510;
BA_ "GenSigStartValueInteger" SG_ 884 PmCabn20Mnte_Conc_Actl 510;
BA_ "U_CD764_MY2022_Rx" SG_ 884 PmCabn18Mnte_Conc_Actl 1;
BA_ "U_CD542_MY2021_Rx" SG_ 884 PmCabn18Mnte_Conc_Actl 1;
BA_ "U_T6_MCA_MY2020_Rx" SG_ 884 PmCabn18Mnte_Conc_Actl 1;
BA_ "U_P702_MY2021_Rx" SG_ 884 PmCabn18Mnte_Conc_Actl 1;
BA_ "U_U55X_MY2022_Rx" SG_ 884 PmCabn18Mnte_Conc_Actl 1;
BA_ "GenSigStartValue" SG_ 884 PmCabn18Mnte_Conc_Actl 510;
BA_ "GenSigStartValueInteger" SG_ 884 PmCabn18Mnte_Conc_Actl 510;
BA_ "U_CD764_MY2022_Rx" SG_ 884 PmCabn16Mnte_Conc_Actl 1;
BA_ "U_CD542_MY2021_Rx" SG_ 884 PmCabn16Mnte_Conc_Actl 1;
BA_ "U_T6_MCA_MY2020_Rx" SG_ 884 PmCabn16Mnte_Conc_Actl 1;
BA_ "U_P702_MY2021_Rx" SG_ 884 PmCabn16Mnte_Conc_Actl 1;
BA_ "U_U55X_MY2022_Rx" SG_ 884 PmCabn16Mnte_Conc_Actl 1;
BA_ "GenSigStartValue" SG_ 884 PmCabn16Mnte_Conc_Actl 510;
BA_ "GenSigStartValueInteger" SG_ 884 PmCabn16Mnte_Conc_Actl 510;
BA_ "U_CD764_MY2022_Rx" SG_ 884 PmCabn14Mnte_Conc_Actl 1;
BA_ "U_CD542_MY2021_Rx" SG_ 884 PmCabn14Mnte_Conc_Actl 1;
BA_ "U_T6_MCA_MY2020_Rx" SG_ 884 PmCabn14Mnte_Conc_Actl 1;
BA_ "U_P702_MY2021_Rx" SG_ 884 PmCabn14Mnte_Conc_Actl 1;
BA_ "U_U55X_MY2022_Rx" SG_ 884 PmCabn14Mnte_Conc_Actl 1;
BA_ "GenSigStartValue" SG_ 884 PmCabn14Mnte_Conc_Actl 510;
BA_ "GenSigStartValueInteger" SG_ 884 PmCabn14Mnte_Conc_Actl 510;
BA_ "U_CD764_MY2022_Rx" SG_ 884 PmCabn12Mnte_Conc_Actl 1;
BA_ "U_CD542_MY2021_Rx" SG_ 884 PmCabn12Mnte_Conc_Actl 1;
BA_ "U_T6_MCA_MY2020_Rx" SG_ 884 PmCabn12Mnte_Conc_Actl 1;
BA_ "U_P702_MY2021_Rx" SG_ 884 PmCabn12Mnte_Conc_Actl 1;
BA_ "U_U55X_MY2022_Rx" SG_ 884 PmCabn12Mnte_Conc_Actl 1;
BA_ "GenSigStartValue" SG_ 884 PmCabn12Mnte_Conc_Actl 510;
BA_ "GenSigStartValueInteger" SG_ 884 PmCabn12Mnte_Conc_Actl 510;
BA_ "U_CD764_MY2022_Rx" SG_ 883 PmCabn10Mnte_Conc_Actl 1;
BA_ "U_CD542_MY2021_Rx" SG_ 883 PmCabn10Mnte_Conc_Actl 1;
BA_ "U_T6_MCA_MY2020_Rx" SG_ 883 PmCabn10Mnte_Conc_Actl 1;
BA_ "U_P702_MY2021_Rx" SG_ 883 PmCabn10Mnte_Conc_Actl 1;
BA_ "U_U55X_MY2022_Rx" SG_ 883 PmCabn10Mnte_Conc_Actl 1;
BA_ "GenSigStartValue" SG_ 883 PmCabn10Mnte_Conc_Actl 510;
BA_ "GenSigStartValueInteger" SG_ 883 PmCabn10Mnte_Conc_Actl 510;
BA_ "U_CD764_MY2022_Rx" SG_ 883 PmCabn08Mnte_Conc_Actl 1;
BA_ "U_CD542_MY2021_Rx" SG_ 883 PmCabn08Mnte_Conc_Actl 1;
BA_ "U_T6_MCA_MY2020_Rx" SG_ 883 PmCabn08Mnte_Conc_Actl 1;
BA_ "U_P702_MY2021_Rx" SG_ 883 PmCabn08Mnte_Conc_Actl 1;
BA_ "U_U55X_MY2022_Rx" SG_ 883 PmCabn08Mnte_Conc_Actl 1;
BA_ "GenSigStartValue" SG_ 883 PmCabn08Mnte_Conc_Actl 510;
BA_ "GenSigStartValueInteger" SG_ 883 PmCabn08Mnte_Conc_Actl 510;
BA_ "U_CD764_MY2022_Rx" SG_ 883 PmCabn06Mnte_Conc_Actl 1;
BA_ "U_CD542_MY2021_Rx" SG_ 883 PmCabn06Mnte_Conc_Actl 1;
BA_ "U_T6_MCA_MY2020_Rx" SG_ 883 PmCabn06Mnte_Conc_Actl 1;
BA_ "U_P702_MY2021_Rx" SG_ 883 PmCabn06Mnte_Conc_Actl 1;
BA_ "U_U55X_MY2022_Rx" SG_ 883 PmCabn06Mnte_Conc_Actl 1;
BA_ "GenSigStartValue" SG_ 883 PmCabn06Mnte_Conc_Actl 510;
BA_ "GenSigStartValueInteger" SG_ 883 PmCabn06Mnte_Conc_Actl 510;
BA_ "U_CD764_MY2022_Rx" SG_ 883 PmCabn04Mnte_Conc_Actl 1;
BA_ "U_CD542_MY2021_Rx" SG_ 883 PmCabn04Mnte_Conc_Actl 1;
BA_ "U_T6_MCA_MY2020_Rx" SG_ 883 PmCabn04Mnte_Conc_Actl 1;
BA_ "U_P702_MY2021_Rx" SG_ 883 PmCabn04Mnte_Conc_Actl 1;
BA_ "U_U55X_MY2022_Rx" SG_ 883 PmCabn04Mnte_Conc_Actl 1;
BA_ "GenSigStartValue" SG_ 883 PmCabn04Mnte_Conc_Actl 510;
BA_ "GenSigStartValueInteger" SG_ 883 PmCabn04Mnte_Conc_Actl 510;
BA_ "U_CD764_MY2022_Rx" SG_ 883 PmCabn02Mnte_Conc_Actl 1;
BA_ "U_CD542_MY2021_Rx" SG_ 883 PmCabn02Mnte_Conc_Actl 1;
BA_ "U_T6_MCA_MY2020_Rx" SG_ 883 PmCabn02Mnte_Conc_Actl 1;
BA_ "U_P702_MY2021_Rx" SG_ 883 PmCabn02Mnte_Conc_Actl 1;
BA_ "U_U55X_MY2022_Rx" SG_ 883 PmCabn02Mnte_Conc_Actl 1;
BA_ "GenSigStartValue" SG_ 883 PmCabn02Mnte_Conc_Actl 510;
BA_ "GenSigStartValueInteger" SG_ 883 PmCabn02Mnte_Conc_Actl 510;
BA_ "U_CD764_MY2022_Rx" SG_ 1090 VehElRnge_L_Dsply 1;
BA_ "U_CD542_MY2021_Rx" SG_ 1090 VehElRnge_L_Dsply 1;
BA_ "U_T6_MCA_MY2020_Rx" SG_ 1090 VehElRnge_L_Dsply 1;
BA_ "U_U55X_MY2022_Rx" SG_ 1090 VehElRnge_L_Dsply 1;
BA_ "GenSigStartValue" SG_ 1090 VehElRnge_L_Dsply 4093;
BA_ "GenSigStartValueInteger" SG_ 1090 VehElRnge_L_Dsply 4095;
BA_ "GenSigStartValue" SG_ 1090 Inv1Ain_I_ActlMntr 32765;
BA_ "GenSigStartValueInteger" SG_ 1090 Inv1Ain_I_ActlMntr 32766;
BA_ "U_U55X_MY2022_Tx" SG_ 677 SeatFnPsgr_D_Rq3 1;
BA_ "GenSigSendType" SG_ 677 SeatFnPsgr_D_Rq3 3;
BA_ "U_U55X_MY2022_Tx" SG_ 677 SeatFnDrv_D_Rq3 1;
BA_ "GenSigSendType" SG_ 677 SeatFnDrv_D_Rq3 3;
BA_ "U_U55X_MY2022_Tx" SG_ 677 SeatMasgPsngrRr_D_Rq2 1;
BA_ "GenSigSendType" SG_ 677 SeatMasgPsngrRr_D_Rq2 3;
BA_ "U_U55X_MY2022_Tx" SG_ 677 SeatMasgDrvRr_D_Rq2 1;
BA_ "GenSigSendType" SG_ 677 SeatMasgDrvRr_D_Rq2 3;
BA_ "U_U55X_MY2022_Tx" SG_ 677 SeatFnChngPsgr2_D_Rq3 1;
BA_ "GenSigSendType" SG_ 677 SeatFnChngPsgr2_D_Rq3 3;
BA_ "U_U55X_MY2022_Tx" SG_ 677 SeatFnChngDrv2_D_Rq3 1;
BA_ "GenSigSendType" SG_ 677 SeatFnChngDrv2_D_Rq3 3;
BA_ "U_U55X_MY2022_Rx" SG_ 1238 IaccVAdjReas_D_Dsply 1;
BA_ "U_CD542_MY2021_Rx" SG_ 1238 IaccVAdjReas_D_Dsply 1;
BA_ "U_U55X_MY2022_Rx" SG_ 1238 IaccVAdjLim_No_Actl 1;
BA_ "U_CD542_MY2021_Rx" SG_ 1238 IaccVAdjLim_No_Actl 1;
BA_ "U_U55X_MY2022_Rx" SG_ 1041 ElCmpr_N_Actl 1;
BA_ "U_CD764_MY2022_Tx" SG_ 2609971416 OTAPhysGWM_ECGtoWCM 1;
BA_ "U_CD542_MY2021_Tx" SG_ 2609971416 OTAPhysGWM_ECGtoWCM 1;
BA_ "ECGUsedTxSignal" SG_ 2609971416 OTAPhysGWM_ECGtoWCM 1;
BA_ "U_CD764_MY2022_Rx" SG_ 2609971416 OTAPhysGWM_ECGtoWCM 1;
BA_ "U_U55X_MY2022_Rx" SG_ 2609971416 OTAPhysGWM_ECGtoWCM 1;
BA_ "U_CD542_MY2021_Rx" SG_ 2609971416 OTAPhysGWM_ECGtoWCM 1;
BA_ "GenSigSendType" SG_ 2609971416 OTAPhysGWM_ECGtoWCM 3;
BA_ "U_CD764_MY2022_Tx" SG_ 2610126912 OTAPhysWCMtoGWM_ECG 1;
BA_ "U_U55X_MY2022_Tx" SG_ 2610126912 OTAPhysWCMtoGWM_ECG 1;
BA_ "U_CD542_MY2021_Tx" SG_ 2610126912 OTAPhysWCMtoGWM_ECG 1;
BA_ "U_CD764_MY2022_Rx" SG_ 2610126912 OTAPhysWCMtoGWM_ECG 1;
BA_ "U_CD542_MY2021_Rx" SG_ 2610126912 OTAPhysWCMtoGWM_ECG 1;
BA_ "ECGUsedRxSignal" SG_ 2610126912 OTAPhysWCMtoGWM_ECG 1;
BA_ "GenSigSendType" SG_ 2610126912 OTAPhysWCMtoGWM_ECG 3;
BA_ "U_CD764_MY2022_Tx" SG_ 2611019992 PARSEDPhysGWM_ECGtoWCM 1;
BA_ "U_CD542_MY2021_Tx" SG_ 2611019992 PARSEDPhysGWM_ECGtoWCM 1;
BA_ "ECGUsedTxSignal" SG_ 2611019992 PARSEDPhysGWM_ECGtoWCM 1;
BA_ "U_CD764_MY2022_Rx" SG_ 2611019992 PARSEDPhysGWM_ECGtoWCM 1;
BA_ "U_U55X_MY2022_Rx" SG_ 2611019992 PARSEDPhysGWM_ECGtoWCM 1;
BA_ "U_CD542_MY2021_Rx" SG_ 2611019992 PARSEDPhysGWM_ECGtoWCM 1;
BA_ "GenSigSendType" SG_ 2611019992 PARSEDPhysGWM_ECGtoWCM 3;
BA_ "U_CD764_MY2022_Tx" SG_ 2611175488 PARSEDPhysWCMtoGWM_ECG 1;
BA_ "U_U55X_MY2022_Tx" SG_ 2611175488 PARSEDPhysWCMtoGWM_ECG 1;
BA_ "U_CD764_MY2022_Rx" SG_ 2611175488 PARSEDPhysWCMtoGWM_ECG 1;
BA_ "U_CD542_MY2021_Rx" SG_ 2611175488 PARSEDPhysWCMtoGWM_ECG 1;
BA_ "ECGUsedRxSignal" SG_ 2611175488 PARSEDPhysWCMtoGWM_ECG 1;
BA_ "GenSigSendType" SG_ 2611175488 PARSEDPhysWCMtoGWM_ECG 3;
BA_ "U_CD764_MY2022_Tx" SG_ 2612068568 PARSEDPushFcGWM_ECGtoWCM 1;
BA_ "U_CD542_MY2021_Tx" SG_ 2612068568 PARSEDPushFcGWM_ECGtoWCM 1;
BA_ "ECGUsedTxSignal" SG_ 2612068568 PARSEDPushFcGWM_ECGtoWCM 1;
BA_ "U_CD764_MY2022_Rx" SG_ 2612068568 PARSEDPushFcGWM_ECGtoWCM 1;
BA_ "U_U55X_MY2022_Rx" SG_ 2612068568 PARSEDPushFcGWM_ECGtoWCM 1;
BA_ "U_CD542_MY2021_Rx" SG_ 2612068568 PARSEDPushFcGWM_ECGtoWCM 1;
BA_ "GenSigSendType" SG_ 2612068568 PARSEDPushFcGWM_ECGtoWCM 3;
BA_ "U_CD764_MY2022_Tx" SG_ 2612224064 PARSEDPushWCMtoGWM_ECG 1;
BA_ "U_U55X_MY2022_Tx" SG_ 2612224064 PARSEDPushWCMtoGWM_ECG 1;
BA_ "U_CD542_MY2021_Tx" SG_ 2612224064 PARSEDPushWCMtoGWM_ECG 1;
BA_ "U_CD764_MY2022_Rx" SG_ 2612224064 PARSEDPushWCMtoGWM_ECG 1;
BA_ "U_CD542_MY2021_Rx" SG_ 2612224064 PARSEDPushWCMtoGWM_ECG 1;
BA_ "ECGUsedRxSignal" SG_ 2612224064 PARSEDPushWCMtoGWM_ECG 1;
BA_ "GenSigSendType" SG_ 2612224064 PARSEDPushWCMtoGWM_ECG 3;
BA_ "U_U55X_MY2022_Rx" SG_ 557 AudioToneTouchY_D_Stat 1;
BA_ "U_T6_MCA_MY2020_Rx" SG_ 557 AudioToneTouchY_D_Stat 1;
BA_ "GenSigSendType" SG_ 557 AudioToneTouchY_D_Stat 3;
BA_ "U_U55X_MY2022_Rx" SG_ 557 AudioToneTouchX_D_Stat 1;
BA_ "U_T6_MCA_MY2020_Rx" SG_ 557 AudioToneTouchX_D_Stat 1;
BA_ "GenSigSendType" SG_ 557 AudioToneTouchX_D_Stat 3;
BA_ "U_U55X_MY2022_Rx" SG_ 557 AudioToneTouch_D_Stat 1;
BA_ "U_T6_MCA_MY2020_Rx" SG_ 557 AudioToneTouch_D_Stat 1;
BA_ "GenSigSendType" SG_ 557 AudioToneTouch_D_Stat 3;
BA_ "U_U55X_MY2022_Rx" SG_ 1236 ApaSlotRearX_L_Actl 1;
BA_ "GenSigStartValue" SG_ 1236 ApaSlotRearX_L_Actl 1048;
BA_ "U_U55X_MY2022_Rx" SG_ 1236 ApaSlotRight3X_L_Actl 1;
BA_ "GenSigStartValue" SG_ 1236 ApaSlotRight3X_L_Actl 1048;
BA_ "U_U55X_MY2022_Rx" SG_ 1236 ApaSlotRight3_D_Stat 1;
BA_ "U_U55X_MY2022_Rx" SG_ 1236 ApaSlotRight3_B_Altr 1;
BA_ "U_U55X_MY2022_Rx" SG_ 1236 ApaSlotRight2X_L_Actl 1;
BA_ "GenSigStartValue" SG_ 1236 ApaSlotRight2X_L_Actl 1048;
BA_ "U_U55X_MY2022_Rx" SG_ 1236 ApaSlotRight2_D_Stat 1;
BA_ "U_U55X_MY2022_Rx" SG_ 1236 ApaSlotRight2_B_Altr 1;
BA_ "U_U55X_MY2022_Rx" SG_ 1236 ApaSlotRight1X_L_Actl 1;
BA_ "GenSigStartValue" SG_ 1236 ApaSlotRight1X_L_Actl 1048;
BA_ "U_U55X_MY2022_Rx" SG_ 1236 ApaSlotRight1_D_Stat 1;
BA_ "U_U55X_MY2022_Rx" SG_ 1236 ApaSlotRight1_B_Altr 1;
BA_ "U_U55X_MY2022_Rx" SG_ 1236 ApaSlotRearY_L_Actl 1;
BA_ "GenSigStartValue" SG_ 1236 ApaSlotRearY_L_Actl 32;
BA_ "U_U55X_MY2022_Rx" SG_ 1236 ApaSlotRear_D_Stat 1;
BA_ "U_U55X_MY2022_Rx" SG_ 1235 ApaSlotFront_D_Stat 1;
BA_ "U_U55X_MY2022_Rx" SG_ 1235 ApaSlotLeft3X_L_Actl 1;
BA_ "GenSigStartValue" SG_ 1235 ApaSlotLeft3X_L_Actl 1048;
BA_ "U_U55X_MY2022_Rx" SG_ 1235 ApaSlotLeft3_D_Stat 1;
BA_ "U_U55X_MY2022_Rx" SG_ 1235 ApaSlotLeft3_B_Altr 1;
BA_ "U_U55X_MY2022_Rx" SG_ 1235 ApaSlotFrontX_L_Actl 1;
BA_ "GenSigStartValue" SG_ 1235 ApaSlotFrontX_L_Actl 1048;
BA_ "U_U55X_MY2022_Rx" SG_ 1235 ApaSlotFrontY_L_Actl 1;
BA_ "GenSigStartValue" SG_ 1235 ApaSlotFrontY_L_Actl 32;
BA_ "U_U55X_MY2022_Rx" SG_ 1235 ApaSlotLeft2X_L_Actl 1;
BA_ "GenSigStartValue" SG_ 1235 ApaSlotLeft2X_L_Actl 1048;
BA_ "U_U55X_MY2022_Rx" SG_ 1235 ApaSlotLeft2_D_Stat 1;
BA_ "U_U55X_MY2022_Rx" SG_ 1235 ApaSlotLeft2_B_Altr 1;
BA_ "U_U55X_MY2022_Rx" SG_ 1235 ApaSlotLeft1X_L_Actl 1;
BA_ "GenSigStartValue" SG_ 1235 ApaSlotLeft1X_L_Actl 1048;
BA_ "U_U55X_MY2022_Rx" SG_ 1235 ApaSlotLeft1_D_Stat 1;
BA_ "U_U55X_MY2022_Rx" SG_ 1235 ApaSlotLeft1_B_Altr 1;
BA_ "GenSigStartValue" SG_ 1234 RmtCtlConfgSrc_D_Stat 1;
BA_ "U_U55X_MY2022_Rx" SG_ 1237 ApaSlotRef2Y_L_Actl 1;
BA_ "U_U55X_MY2022_Rx" SG_ 1237 ApaSlotRef2X_L_Actl 1;
BA_ "U_U55X_MY2022_Rx" SG_ 1237 ApaSlotRef1Y_L_Actl 1;
BA_ "U_U55X_MY2022_Rx" SG_ 1237 ApaSlotRef1X_L_Actl 1;
BA_ "U_U55X_MY2022_Rx" SG_ 976 VehLong2_A_Actl_UB 1;
BA_ "U_T6_MCA_MY2020_Rx" SG_ 976 VehLong2_A_Actl_UB 1;
BA_ "U_P702_MY2021_Rx" SG_ 976 VehLong2_A_Actl_UB 1;
BA_ "U_U55X_MY2022_Rx" SG_ 976 VehLong2_A_Actl 1;
BA_ "U_T6_MCA_MY2020_Rx" SG_ 976 VehLong2_A_Actl 1;
BA_ "U_P702_MY2021_Rx" SG_ 976 VehLong2_A_Actl 1;
BA_ "GenSigStartValue" SG_ 976 VehLong2_A_Actl 8190;
BA_ "GenSigStartValueInteger" SG_ 976 VehLong2_A_Actl 8190;
BA_ "U_U55X_MY2022_Tx" SG_ 715 RDISP_SSP_WORD_Rx 1;
BA_ "U_CD542_MY2021_Tx" SG_ 715 RDISP_SSP_WORD_Rx 1;
BA_ "U_T6_MCA_MY2020_Tx" SG_ 715 RDISP_SSP_WORD_Rx 1;
BA_ "U_P702_MY2021_Tx" SG_ 715 RDISP_SSP_WORD_Rx 1;
BA_ "U_U55X_MY2022_Rx" SG_ 715 RDISP_SSP_WORD_Rx 1;
BA_ "U_CD542_MY2021_Rx" SG_ 715 RDISP_SSP_WORD_Rx 1;
BA_ "U_T6_MCA_MY2020_Rx" SG_ 715 RDISP_SSP_WORD_Rx 1;
BA_ "U_P702_MY2021_Rx" SG_ 715 RDISP_SSP_WORD_Rx 1;
BA_ "U_CD764_MY2022_Rx" SG_ 898 SecondRowBcklPsngrMid 1;
BA_ "GenSigStartValue" SG_ 898 SecondRowBcklPsngrMid 3;
BA_ "U_CD764_MY2022_Rx" SG_ 898 SecondRowBuckleDrvMid 1;
BA_ "GenSigStartValue" SG_ 898 SecondRowBuckleDrvMid 3;
BA_ "U_CD764_MY2022_Rx" SG_ 898 FourthRowBucklePsngr 1;
BA_ "GenSigStartValue" SG_ 898 FourthRowBucklePsngr 3;
BA_ "U_CD764_MY2022_Rx" SG_ 898 FourthRowBuckleMid 1;
BA_ "GenSigStartValue" SG_ 898 FourthRowBuckleMid 3;
BA_ "U_CD764_MY2022_Rx" SG_ 898 FourthRowBuckleDriver 1;
BA_ "GenSigStartValue" SG_ 898 FourthRowBuckleDriver 3;
BA_ "U_CD764_MY2022_Rx" SG_ 898 Row3PsngrPrsnc_D_Actl 1;
BA_ "GenSigStartValue" SG_ 898 Row3PsngrPrsnc_D_Actl 3;
BA_ "U_CD764_MY2022_Rx" SG_ 898 Row3MidPrsnc_D_Actl 1;
BA_ "GenSigStartValue" SG_ 898 Row3MidPrsnc_D_Actl 3;
BA_ "U_CD764_MY2022_Rx" SG_ 898 Row3DrvPrsnc_D_Actl 1;
BA_ "GenSigStartValue" SG_ 898 Row3DrvPrsnc_D_Actl 3;
BA_ "U_CD764_MY2022_Rx" SG_ 898 Row2PsngrPrsnc_D_Actl 1;
BA_ "GenSigStartValue" SG_ 898 Row2PsngrPrsnc_D_Actl 3;
BA_ "U_CD764_MY2022_Rx" SG_ 898 Row2MidPrsnc_D_Actl 1;
BA_ "GenSigStartValue" SG_ 898 Row2MidPrsnc_D_Actl 3;
BA_ "U_CD764_MY2022_Rx" SG_ 898 Row2DrvPrsnc_D_Actl 1;
BA_ "GenSigStartValue" SG_ 898 Row2DrvPrsnc_D_Actl 3;
BA_ "U_U55X_MY2022_Rx" SG_ 925 VehElEffTrip_No_Dsply 1;
BA_ "GenSigStartValue" SG_ 925 VehElEffTrip_No_Dsply 126;
BA_ "GenSigStartValueInteger" SG_ 925 VehElEffTrip_No_Dsply 126;
BA_ "U_U55X_MY2022_Rx" SG_ 925 TripSumDrvE_Pc_Dsply 1;
BA_ "GenSigStartValue" SG_ 925 TripSumDrvE_Pc_Dsply 1022;
BA_ "GenSigStartValueInteger" SG_ 925 TripSumDrvE_Pc_Dsply 1022;
BA_ "U_U55X_MY2022_Rx" SG_ 925 TripExtFctrE_Pc_Dsply 1;
BA_ "GenSigStartValue" SG_ 925 TripExtFctrE_Pc_Dsply 1022;
BA_ "GenSigStartValueInteger" SG_ 925 TripExtFctrE_Pc_Dsply 1022;
BA_ "U_U55X_MY2022_Rx" SG_ 925 TripClimE_Pc_Dsply 1;
BA_ "GenSigStartValue" SG_ 925 TripClimE_Pc_Dsply 1022;
BA_ "GenSigStartValueInteger" SG_ 925 TripClimE_Pc_Dsply 1022;
BA_ "U_U55X_MY2022_Rx" SG_ 925 TripBattULoE_Pc_Dsply 1;
BA_ "GenSigStartValue" SG_ 925 TripBattULoE_Pc_Dsply 1022;
BA_ "GenSigStartValueInteger" SG_ 925 TripBattULoE_Pc_Dsply 1022;
BA_ "U_U55X_MY2022_Rx" SG_ 788 EcoCochDecel2_Pc_Dsply 1;
BA_ "GenSigStartValue" SG_ 788 EcoCochDecel2_Pc_Dsply 255;
BA_ "GenSigStartValueInteger" SG_ 788 EcoCochDecel2_Pc_Dsply 255;
BA_ "U_U55X_MY2022_Rx" SG_ 788 EcoCochDecel1_Pc_Dsply 1;
BA_ "GenSigStartValue" SG_ 788 EcoCochDecel1_Pc_Dsply 255;
BA_ "GenSigStartValueInteger" SG_ 788 EcoCochDecel1_Pc_Dsply 255;
BA_ "U_U55X_MY2022_Rx" SG_ 788 EcoCochCrus2_Pc_Dsply 1;
BA_ "GenSigStartValue" SG_ 788 EcoCochCrus2_Pc_Dsply 255;
BA_ "GenSigStartValueInteger" SG_ 788 EcoCochCrus2_Pc_Dsply 255;
BA_ "U_U55X_MY2022_Rx" SG_ 788 EcoCochCrus1_Pc_Dsply 1;
BA_ "GenSigStartValue" SG_ 788 EcoCochCrus1_Pc_Dsply 255;
BA_ "GenSigStartValueInteger" SG_ 788 EcoCochCrus1_Pc_Dsply 255;
BA_ "U_U55X_MY2022_Rx" SG_ 788 EcoCochATrip2_Pc_Dsply 1;
BA_ "GenSigStartValue" SG_ 788 EcoCochATrip2_Pc_Dsply 255;
BA_ "GenSigStartValueInteger" SG_ 788 EcoCochATrip2_Pc_Dsply 255;
BA_ "U_U55X_MY2022_Rx" SG_ 788 EcoCochATrip1_Pc_Dsply 1;
BA_ "GenSigStartValue" SG_ 788 EcoCochATrip1_Pc_Dsply 255;
BA_ "GenSigStartValueInteger" SG_ 788 EcoCochATrip1_Pc_Dsply 255;
BA_ "U_U55X_MY2022_Tx" SG_ 473 NAV_StorePreset2_Rq 1;
BA_ "U_CD542_MY2021_Tx" SG_ 473 NAV_StorePreset2_Rq 1;
BA_ "U_T6_MCA_MY2020_Tx" SG_ 473 NAV_StorePreset2_Rq 1;
BA_ "U_U55X_MY2022_Rx" SG_ 473 NAV_StorePreset2_Rq 1;
BA_ "U_CD542_MY2021_Rx" SG_ 473 NAV_StorePreset2_Rq 1;
BA_ "U_T6_MCA_MY2020_Rx" SG_ 473 NAV_StorePreset2_Rq 1;
BA_ "GenSigSendType" SG_ 473 NAV_StorePreset2_Rq 3;
BA_ "U_U55X_MY2022_Tx" SG_ 473 NAV_SetAFMode_Rq 1;
BA_ "U_CD542_MY2021_Tx" SG_ 473 NAV_SetAFMode_Rq 1;
BA_ "U_T6_MCA_MY2020_Tx" SG_ 473 NAV_SetAFMode_Rq 1;
BA_ "U_P702_MY2021_Tx" SG_ 473 NAV_SetAFMode_Rq 1;
BA_ "U_U55X_MY2022_Rx" SG_ 473 NAV_SetAFMode_Rq 1;
BA_ "U_CD542_MY2021_Rx" SG_ 473 NAV_SetAFMode_Rq 1;
BA_ "U_T6_MCA_MY2020_Rx" SG_ 473 NAV_SetAFMode_Rq 1;
BA_ "GenSigSendType" SG_ 473 NAV_SetAFMode_Rq 3;
BA_ "U_U55X_MY2022_Tx" SG_ 473 NAV_StorePreset_Rq 1;
BA_ "U_CD542_MY2021_Tx" SG_ 473 NAV_StorePreset_Rq 1;
BA_ "U_T6_MCA_MY2020_Tx" SG_ 473 NAV_StorePreset_Rq 1;
BA_ "U_P702_MY2021_Tx" SG_ 473 NAV_StorePreset_Rq 1;
BA_ "U_U55X_MY2022_Rx" SG_ 473 NAV_StorePreset_Rq 1;
BA_ "U_CD542_MY2021_Rx" SG_ 473 NAV_StorePreset_Rq 1;
BA_ "U_T6_MCA_MY2020_Rx" SG_ 473 NAV_StorePreset_Rq 1;
BA_ "GenSigSendType" SG_ 473 NAV_StorePreset_Rq 3;
BA_ "U_U55X_MY2022_Tx" SG_ 473 HMI_StorePreset2_Rq 1;
BA_ "U_CD542_MY2021_Tx" SG_ 473 HMI_StorePreset2_Rq 1;
BA_ "U_T6_MCA_MY2020_Tx" SG_ 473 HMI_StorePreset2_Rq 1;
BA_ "U_P702_MY2021_Tx" SG_ 473 HMI_StorePreset2_Rq 1;
BA_ "U_U55X_MY2022_Rx" SG_ 473 HMI_StorePreset2_Rq 1;
BA_ "U_CD542_MY2021_Rx" SG_ 473 HMI_StorePreset2_Rq 1;
BA_ "U_T6_MCA_MY2020_Rx" SG_ 473 HMI_StorePreset2_Rq 1;
BA_ "U_P702_MY2021_Rx" SG_ 473 HMI_StorePreset2_Rq 1;
BA_ "GenSigSendType" SG_ 473 HMI_StorePreset2_Rq 3;
BA_ "U_U55X_MY2022_Tx" SG_ 473 NAV_SetTUServiceLink_Rq 1;
BA_ "U_CD542_MY2021_Tx" SG_ 473 NAV_SetTUServiceLink_Rq 1;
BA_ "U_T6_MCA_MY2020_Tx" SG_ 473 NAV_SetTUServiceLink_Rq 1;
BA_ "U_U55X_MY2022_Rx" SG_ 473 NAV_SetTUServiceLink_Rq 1;
BA_ "U_CD542_MY2021_Rx" SG_ 473 NAV_SetTUServiceLink_Rq 1;
BA_ "U_T6_MCA_MY2020_Rx" SG_ 473 NAV_SetTUServiceLink_Rq 1;
BA_ "GenSigSendType" SG_ 473 NAV_SetTUServiceLink_Rq 3;
BA_ "U_U55X_MY2022_Tx" SG_ 473 NAV_SetTAMode_Rq 1;
BA_ "U_CD542_MY2021_Tx" SG_ 473 NAV_SetTAMode_Rq 1;
BA_ "U_T6_MCA_MY2020_Tx" SG_ 473 NAV_SetTAMode_Rq 1;
BA_ "U_U55X_MY2022_Rx" SG_ 473 NAV_SetTAMode_Rq 1;
BA_ "U_CD542_MY2021_Rx" SG_ 473 NAV_SetTAMode_Rq 1;
BA_ "U_T6_MCA_MY2020_Rx" SG_ 473 NAV_SetTAMode_Rq 1;
BA_ "GenSigSendType" SG_ 473 NAV_SetTAMode_Rq 3;
BA_ "U_U55X_MY2022_Tx" SG_ 473 NAV_SetReg_Rq 1;
BA_ "U_CD542_MY2021_Tx" SG_ 473 NAV_SetReg_Rq 1;
BA_ "U_T6_MCA_MY2020_Tx" SG_ 473 NAV_SetReg_Rq 1;
BA_ "U_U55X_MY2022_Rx" SG_ 473 NAV_SetReg_Rq 1;
BA_ "U_CD542_MY2021_Rx" SG_ 473 NAV_SetReg_Rq 1;
BA_ "U_T6_MCA_MY2020_Rx" SG_ 473 NAV_SetReg_Rq 1;
BA_ "GenSigSendType" SG_ 473 NAV_SetReg_Rq 3;
BA_ "U_U55X_MY2022_Tx" SG_ 473 NAV_SelectPTYCodeSet_Rq 1;
BA_ "U_CD542_MY2021_Tx" SG_ 473 NAV_SelectPTYCodeSet_Rq 1;
BA_ "U_T6_MCA_MY2020_Tx" SG_ 473 NAV_SelectPTYCodeSet_Rq 1;
BA_ "U_U55X_MY2022_Rx" SG_ 473 NAV_SelectPTYCodeSet_Rq 1;
BA_ "U_T6_MCA_MY2020_Rx" SG_ 473 NAV_SelectPTYCodeSet_Rq 1;
BA_ "GenSigSendType" SG_ 473 NAV_SelectPTYCodeSet_Rq 3;
BA_ "U_U55X_MY2022_Tx" SG_ 473 NAV_SelectPTYCodes_Rq 1;
BA_ "U_CD542_MY2021_Tx" SG_ 473 NAV_SelectPTYCodes_Rq 1;
BA_ "U_T6_MCA_MY2020_Tx" SG_ 473 NAV_SelectPTYCodes_Rq 1;
BA_ "U_U55X_MY2022_Rx" SG_ 473 NAV_SelectPTYCodes_Rq 1;
BA_ "U_CD542_MY2021_Rx" SG_ 473 NAV_SelectPTYCodes_Rq 1;
BA_ "U_T6_MCA_MY2020_Rx" SG_ 473 NAV_SelectPTYCodes_Rq 1;
BA_ "U_U55X_MY2022_Tx" SG_ 473 NAV_CDSetShuffle_Rq 1;
BA_ "U_CD542_MY2021_Tx" SG_ 473 NAV_CDSetShuffle_Rq 1;
BA_ "U_T6_MCA_MY2020_Tx" SG_ 473 NAV_CDSetShuffle_Rq 1;
BA_ "U_T6_MCA_MY2020_Rx" SG_ 473 NAV_CDSetShuffle_Rq 1;
BA_ "GenSigSendType" SG_ 473 NAV_CDSetShuffle_Rq 3;
BA_ "U_U55X_MY2022_Tx" SG_ 473 NAV_CDSetRepeat_Rq 1;
BA_ "U_CD542_MY2021_Tx" SG_ 473 NAV_CDSetRepeat_Rq 1;
BA_ "U_T6_MCA_MY2020_Tx" SG_ 473 NAV_CDSetRepeat_Rq 1;
BA_ "U_T6_MCA_MY2020_Rx" SG_ 473 NAV_CDSetRepeat_Rq 1;
BA_ "GenSigSendType" SG_ 473 NAV_CDSetRepeat_Rq 3;
BA_ "U_U55X_MY2022_Tx" SG_ 473 NAV_CDSetIntroScan_Rq 1;
BA_ "U_CD542_MY2021_Tx" SG_ 473 NAV_CDSetIntroScan_Rq 1;
BA_ "U_T6_MCA_MY2020_Tx" SG_ 473 NAV_CDSetIntroScan_Rq 1;
BA_ "U_T6_MCA_MY2020_Rx" SG_ 473 NAV_CDSetIntroScan_Rq 1;
BA_ "GenSigSendType" SG_ 473 NAV_CDSetIntroScan_Rq 3;
BA_ "U_U55X_MY2022_Rx" SG_ 2000 TesterPhysicalReqAPIM 1;
BA_ "U_T6_MCA_MY2020_Rx" SG_ 2000 TesterPhysicalReqAPIM 1;
BA_ "U_P702_MY2021_Rx" SG_ 2000 TesterPhysicalReqAPIM 1;
BA_ "U_CD764_MY2022_Rx" SG_ 2000 TesterPhysicalReqAPIM 1;
BA_ "U_CD542_MY2021_Rx" SG_ 2000 TesterPhysicalReqAPIM 1;
BA_ "GenSigSendType" SG_ 2000 TesterPhysicalReqAPIM 3;
BA_ "U_CD764_MY2022_Tx" SG_ 810 ExtLghtDsply_B_StatArb 1;
BA_ "U_U55X_MY2022_Tx" SG_ 810 ExtLghtDsply_B_StatArb 1;
BA_ "U_CD542_MY2021_Tx" SG_ 810 ExtLghtDsply_B_StatArb 1;
BA_ "ECGUsedTxSignal" SG_ 810 ExtLghtDsply_B_StatArb 1;
BA_ "U_T6_MCA_MY2020_Tx" SG_ 810 ExtLghtDsply_B_StatArb 1;
BA_ "U_U55X_MY2022_Rx" SG_ 810 ExtLghtDsply_B_StatArb 1;
BA_ "U_T6_MCA_MY2020_Rx" SG_ 810 ExtLghtDsply_B_StatArb 1;
BA_ "GenSigSendType" SG_ 810 ExtLghtDsply_B_StatArb 3;
BA_ "WakeupSignal" SG_ 810 ExtLghtDsply_B_StatArb 1;
BA_ "U_CD764_MY2022_Tx" SG_ 810 OneTEditActv_B_RqCld 1;
BA_ "U_U55X_MY2022_Tx" SG_ 810 OneTEditActv_B_RqCld 1;
BA_ "U_CD542_MY2021_Tx" SG_ 810 OneTEditActv_B_RqCld 1;
BA_ "ECGUsedTxSignal" SG_ 810 OneTEditActv_B_RqCld 1;
BA_ "U_U55X_MY2022_Rx" SG_ 810 OneTEditActv_B_RqCld 1;
BA_ "GenSigSendType" SG_ 810 OneTEditActv_B_RqCld 3;
BA_ "U_U55X_MY2022_Tx" SG_ 482 SDARS_Firm_Update2_St 1;
BA_ "U_CD542_MY2021_Tx" SG_ 482 SDARS_Firm_Update2_St 1;
BA_ "U_T6_MCA_MY2020_Tx" SG_ 482 SDARS_Firm_Update2_St 1;
BA_ "U_P702_MY2021_Tx" SG_ 482 SDARS_Firm_Update2_St 1;
BA_ "U_CD764_MY2022_Rx" SG_ 482 SDARS_Firm_Update2_St 1;
BA_ "U_U55X_MY2022_Rx" SG_ 482 SDARS_Firm_Update2_St 1;
BA_ "U_CD542_MY2021_Rx" SG_ 482 SDARS_Firm_Update2_St 1;
BA_ "U_T6_MCA_MY2020_Rx" SG_ 482 SDARS_Firm_Update2_St 1;
BA_ "GenSigSendType" SG_ 482 SDARS_Firm_Update2_St 3;
BA_ "U_U55X_MY2022_Tx" SG_ 482 SDARS_UnSubscrb_Chan2_St 1;
BA_ "U_CD542_MY2021_Tx" SG_ 482 SDARS_UnSubscrb_Chan2_St 1;
BA_ "U_T6_MCA_MY2020_Tx" SG_ 482 SDARS_UnSubscrb_Chan2_St 1;
BA_ "U_P702_MY2021_Tx" SG_ 482 SDARS_UnSubscrb_Chan2_St 1;
BA_ "U_CD764_MY2022_Rx" SG_ 482 SDARS_UnSubscrb_Chan2_St 1;
BA_ "U_U55X_MY2022_Rx" SG_ 482 SDARS_UnSubscrb_Chan2_St 1;
BA_ "U_CD542_MY2021_Rx" SG_ 482 SDARS_UnSubscrb_Chan2_St 1;
BA_ "U_T6_MCA_MY2020_Rx" SG_ 482 SDARS_UnSubscrb_Chan2_St 1;
BA_ "GenSigSendType" SG_ 482 SDARS_UnSubscrb_Chan2_St 3;
BA_ "U_U55X_MY2022_Tx" SG_ 482 SDARS_UnSubscrb2_St 1;
BA_ "U_CD542_MY2021_Tx" SG_ 482 SDARS_UnSubscrb2_St 1;
BA_ "U_T6_MCA_MY2020_Tx" SG_ 482 SDARS_UnSubscrb2_St 1;
BA_ "U_P702_MY2021_Tx" SG_ 482 SDARS_UnSubscrb2_St 1;
BA_ "U_CD764_MY2022_Rx" SG_ 482 SDARS_UnSubscrb2_St 1;
BA_ "U_U55X_MY2022_Rx" SG_ 482 SDARS_UnSubscrb2_St 1;
BA_ "U_CD542_MY2021_Rx" SG_ 482 SDARS_UnSubscrb2_St 1;
BA_ "U_T6_MCA_MY2020_Rx" SG_ 482 SDARS_UnSubscrb2_St 1;
BA_ "GenSigSendType" SG_ 482 SDARS_UnSubscrb2_St 3;
BA_ "U_U55X_MY2022_Tx" SG_ 482 SDARS_Subscription2_St 1;
BA_ "U_CD542_MY2021_Tx" SG_ 482 SDARS_Subscription2_St 1;
BA_ "U_T6_MCA_MY2020_Tx" SG_ 482 SDARS_Subscription2_St 1;
BA_ "U_P702_MY2021_Tx" SG_ 482 SDARS_Subscription2_St 1;
BA_ "U_CD764_MY2022_Rx" SG_ 482 SDARS_Subscription2_St 1;
BA_ "U_U55X_MY2022_Rx" SG_ 482 SDARS_Subscription2_St 1;
BA_ "U_CD542_MY2021_Rx" SG_ 482 SDARS_Subscription2_St 1;
BA_ "U_T6_MCA_MY2020_Rx" SG_ 482 SDARS_Subscription2_St 1;
BA_ "GenSigSendType" SG_ 482 SDARS_Subscription2_St 3;
BA_ "U_U55X_MY2022_Tx" SG_ 482 SDARS_Seek_Scan2_St 1;
BA_ "U_CD542_MY2021_Tx" SG_ 482 SDARS_Seek_Scan2_St 1;
BA_ "U_T6_MCA_MY2020_Tx" SG_ 482 SDARS_Seek_Scan2_St 1;
BA_ "U_P702_MY2021_Tx" SG_ 482 SDARS_Seek_Scan2_St 1;
BA_ "U_CD764_MY2022_Rx" SG_ 482 SDARS_Seek_Scan2_St 1;
BA_ "U_U55X_MY2022_Rx" SG_ 482 SDARS_Seek_Scan2_St 1;
BA_ "U_CD542_MY2021_Rx" SG_ 482 SDARS_Seek_Scan2_St 1;
BA_ "U_T6_MCA_MY2020_Rx" SG_ 482 SDARS_Seek_Scan2_St 1;
BA_ "GenSigSendType" SG_ 482 SDARS_Seek_Scan2_St 3;
BA_ "U_U55X_MY2022_Tx" SG_ 482 SDARS_Receive_Err2_St 1;
BA_ "U_CD542_MY2021_Tx" SG_ 482 SDARS_Receive_Err2_St 1;
BA_ "U_T6_MCA_MY2020_Tx" SG_ 482 SDARS_Receive_Err2_St 1;
BA_ "U_P702_MY2021_Tx" SG_ 482 SDARS_Receive_Err2_St 1;
BA_ "U_CD764_MY2022_Rx" SG_ 482 SDARS_Receive_Err2_St 1;
BA_ "U_U55X_MY2022_Rx" SG_ 482 SDARS_Receive_Err2_St 1;
BA_ "U_CD542_MY2021_Rx" SG_ 482 SDARS_Receive_Err2_St 1;
BA_ "U_T6_MCA_MY2020_Rx" SG_ 482 SDARS_Receive_Err2_St 1;
BA_ "GenSigSendType" SG_ 482 SDARS_Receive_Err2_St 3;
BA_ "U_U55X_MY2022_Tx" SG_ 482 SDARS_Loss_Ant2_St 1;
BA_ "U_CD542_MY2021_Tx" SG_ 482 SDARS_Loss_Ant2_St 1;
BA_ "U_T6_MCA_MY2020_Tx" SG_ 482 SDARS_Loss_Ant2_St 1;
BA_ "U_P702_MY2021_Tx" SG_ 482 SDARS_Loss_Ant2_St 1;
BA_ "U_CD764_MY2022_Rx" SG_ 482 SDARS_Loss_Ant2_St 1;
BA_ "U_U55X_MY2022_Rx" SG_ 482 SDARS_Loss_Ant2_St 1;
BA_ "U_CD542_MY2021_Rx" SG_ 482 SDARS_Loss_Ant2_St 1;
BA_ "U_T6_MCA_MY2020_Rx" SG_ 482 SDARS_Loss_Ant2_St 1;
BA_ "GenSigSendType" SG_ 482 SDARS_Loss_Ant2_St 3;
BA_ "U_U55X_MY2022_Tx" SG_ 482 SDARS_Invalid_Chan2_St 1;
BA_ "U_CD542_MY2021_Tx" SG_ 482 SDARS_Invalid_Chan2_St 1;
BA_ "U_T6_MCA_MY2020_Tx" SG_ 482 SDARS_Invalid_Chan2_St 1;
BA_ "U_P702_MY2021_Tx" SG_ 482 SDARS_Invalid_Chan2_St 1;
BA_ "U_CD764_MY2022_Rx" SG_ 482 SDARS_Invalid_Chan2_St 1;
BA_ "U_U55X_MY2022_Rx" SG_ 482 SDARS_Invalid_Chan2_St 1;
BA_ "U_CD542_MY2021_Rx" SG_ 482 SDARS_Invalid_Chan2_St 1;
BA_ "U_T6_MCA_MY2020_Rx" SG_ 482 SDARS_Invalid_Chan2_St 1;
BA_ "GenSigSendType" SG_ 482 SDARS_Invalid_Chan2_St 3;
BA_ "U_U55X_MY2022_Tx" SG_ 482 SDARS_GCI_Update2_St 1;
BA_ "U_CD542_MY2021_Tx" SG_ 482 SDARS_GCI_Update2_St 1;
BA_ "U_T6_MCA_MY2020_Tx" SG_ 482 SDARS_GCI_Update2_St 1;
BA_ "U_P702_MY2021_Tx" SG_ 482 SDARS_GCI_Update2_St 1;
BA_ "U_CD764_MY2022_Rx" SG_ 482 SDARS_GCI_Update2_St 1;
BA_ "U_U55X_MY2022_Rx" SG_ 482 SDARS_GCI_Update2_St 1;
BA_ "U_CD542_MY2021_Rx" SG_ 482 SDARS_GCI_Update2_St 1;
BA_ "U_T6_MCA_MY2020_Rx" SG_ 482 SDARS_GCI_Update2_St 1;
BA_ "GenSigSendType" SG_ 482 SDARS_GCI_Update2_St 3;
BA_ "U_U55X_MY2022_Tx" SG_ 482 SDARS_Error_Conf2_St 1;
BA_ "U_CD542_MY2021_Tx" SG_ 482 SDARS_Error_Conf2_St 1;
BA_ "U_T6_MCA_MY2020_Tx" SG_ 482 SDARS_Error_Conf2_St 1;
BA_ "U_P702_MY2021_Tx" SG_ 482 SDARS_Error_Conf2_St 1;
BA_ "U_CD764_MY2022_Rx" SG_ 482 SDARS_Error_Conf2_St 1;
BA_ "U_U55X_MY2022_Rx" SG_ 482 SDARS_Error_Conf2_St 1;
BA_ "U_CD542_MY2021_Rx" SG_ 482 SDARS_Error_Conf2_St 1;
BA_ "U_T6_MCA_MY2020_Rx" SG_ 482 SDARS_Error_Conf2_St 1;
BA_ "GenSigSendType" SG_ 482 SDARS_Error_Conf2_St 3;
BA_ "U_U55X_MY2022_Tx" SG_ 482 SDARS_Antenna_Err2_St 1;
BA_ "U_CD542_MY2021_Tx" SG_ 482 SDARS_Antenna_Err2_St 1;
BA_ "U_T6_MCA_MY2020_Tx" SG_ 482 SDARS_Antenna_Err2_St 1;
BA_ "U_P702_MY2021_Tx" SG_ 482 SDARS_Antenna_Err2_St 1;
BA_ "U_CD764_MY2022_Rx" SG_ 482 SDARS_Antenna_Err2_St 1;
BA_ "U_U55X_MY2022_Rx" SG_ 482 SDARS_Antenna_Err2_St 1;
BA_ "U_CD542_MY2021_Rx" SG_ 482 SDARS_Antenna_Err2_St 1;
BA_ "U_T6_MCA_MY2020_Rx" SG_ 482 SDARS_Antenna_Err2_St 1;
BA_ "GenSigSendType" SG_ 482 SDARS_Antenna_Err2_St 3;
BA_ "U_U55X_MY2022_Tx" SG_ 764 SDARS_SID2_St 1;
BA_ "U_CD542_MY2021_Tx" SG_ 764 SDARS_SID2_St 1;
BA_ "U_T6_MCA_MY2020_Tx" SG_ 764 SDARS_SID2_St 1;
BA_ "U_P702_MY2021_Tx" SG_ 764 SDARS_SID2_St 1;
BA_ "U_CD764_MY2022_Rx" SG_ 764 SDARS_SID2_St 1;
BA_ "U_U55X_MY2022_Rx" SG_ 764 SDARS_SID2_St 1;
BA_ "U_CD542_MY2021_Rx" SG_ 764 SDARS_SID2_St 1;
BA_ "U_T6_MCA_MY2020_Rx" SG_ 764 SDARS_SID2_St 1;
BA_ "U_P702_MY2021_Rx" SG_ 764 SDARS_SID2_St 1;
BA_ "GenSigSendType" SG_ 764 SDARS_SID2_St 3;
BA_ "U_U55X_MY2022_Tx" SG_ 764 SdarsSampleRate_D_Stat 1;
BA_ "U_CD542_MY2021_Tx" SG_ 764 SdarsSampleRate_D_Stat 1;
BA_ "U_T6_MCA_MY2020_Tx" SG_ 764 SdarsSampleRate_D_Stat 1;
BA_ "U_P702_MY2021_Tx" SG_ 764 SdarsSampleRate_D_Stat 1;
BA_ "U_U55X_MY2022_Rx" SG_ 764 SdarsSampleRate_D_Stat 1;
BA_ "U_CD542_MY2021_Rx" SG_ 764 SdarsSampleRate_D_Stat 1;
BA_ "U_T6_MCA_MY2020_Rx" SG_ 764 SdarsSampleRate_D_Stat 1;
BA_ "U_P702_MY2021_Rx" SG_ 764 SdarsSampleRate_D_Stat 1;
BA_ "GenSigSendType" SG_ 764 SdarsSampleRate_D_Stat 3;
BA_ "U_U55X_MY2022_Tx" SG_ 764 SdarsBaudRate_D_Stat 1;
BA_ "U_CD542_MY2021_Tx" SG_ 764 SdarsBaudRate_D_Stat 1;
BA_ "U_T6_MCA_MY2020_Tx" SG_ 764 SdarsBaudRate_D_Stat 1;
BA_ "U_P702_MY2021_Tx" SG_ 764 SdarsBaudRate_D_Stat 1;
BA_ "U_U55X_MY2022_Rx" SG_ 764 SdarsBaudRate_D_Stat 1;
BA_ "U_CD542_MY2021_Rx" SG_ 764 SdarsBaudRate_D_Stat 1;
BA_ "U_T6_MCA_MY2020_Rx" SG_ 764 SdarsBaudRate_D_Stat 1;
BA_ "U_P702_MY2021_Rx" SG_ 764 SdarsBaudRate_D_Stat 1;
BA_ "GenSigSendType" SG_ 764 SdarsBaudRate_D_Stat 3;
BA_ "U_U55X_MY2022_Tx" SG_ 764 SDARS_CurrentChanNum2_St 1;
BA_ "U_CD542_MY2021_Tx" SG_ 764 SDARS_CurrentChanNum2_St 1;
BA_ "U_T6_MCA_MY2020_Tx" SG_ 764 SDARS_CurrentChanNum2_St 1;
BA_ "U_P702_MY2021_Tx" SG_ 764 SDARS_CurrentChanNum2_St 1;
BA_ "U_CD764_MY2022_Rx" SG_ 764 SDARS_CurrentChanNum2_St 1;
BA_ "U_P702_MY2021_Rx" SG_ 764 SDARS_CurrentChanNum2_St 1;
BA_ "U_U55X_MY2022_Rx" SG_ 764 SDARS_CurrentChanNum2_St 1;
BA_ "U_CD542_MY2021_Rx" SG_ 764 SDARS_CurrentChanNum2_St 1;
BA_ "U_T6_MCA_MY2020_Rx" SG_ 764 SDARS_CurrentChanNum2_St 1;
BA_ "GenSigSendType" SG_ 764 SDARS_CurrentChanNum2_St 3;
BA_ "GenSigStartValue" SG_ 764 SDARS_CurrentChanNum2_St 1022;
BA_ "U_U55X_MY2022_Tx" SG_ 764 SDARS_ChannelUpdate_St 1;
BA_ "U_CD542_MY2021_Tx" SG_ 764 SDARS_ChannelUpdate_St 1;
BA_ "U_T6_MCA_MY2020_Tx" SG_ 764 SDARS_ChannelUpdate_St 1;
BA_ "U_P702_MY2021_Tx" SG_ 764 SDARS_ChannelUpdate_St 1;
BA_ "U_U55X_MY2022_Rx" SG_ 764 SDARS_ChannelUpdate_St 1;
BA_ "U_CD542_MY2021_Rx" SG_ 764 SDARS_ChannelUpdate_St 1;
BA_ "U_T6_MCA_MY2020_Rx" SG_ 764 SDARS_ChannelUpdate_St 1;
BA_ "U_P702_MY2021_Rx" SG_ 764 SDARS_ChannelUpdate_St 1;
BA_ "GenSigSendType" SG_ 764 SDARS_ChannelUpdate_St 3;
BA_ "U_U55X_MY2022_Tx" SG_ 764 SDARS_Channel_Lock2 1;
BA_ "U_CD542_MY2021_Tx" SG_ 764 SDARS_Channel_Lock2 1;
BA_ "U_T6_MCA_MY2020_Tx" SG_ 764 SDARS_Channel_Lock2 1;
BA_ "U_P702_MY2021_Tx" SG_ 764 SDARS_Channel_Lock2 1;
BA_ "U_CD764_MY2022_Rx" SG_ 764 SDARS_Channel_Lock2 1;
BA_ "U_U55X_MY2022_Rx" SG_ 764 SDARS_Channel_Lock2 1;
BA_ "U_CD542_MY2021_Rx" SG_ 764 SDARS_Channel_Lock2 1;
BA_ "U_T6_MCA_MY2020_Rx" SG_ 764 SDARS_Channel_Lock2 1;
BA_ "U_P702_MY2021_Rx" SG_ 764 SDARS_Channel_Lock2 1;
BA_ "GenSigSendType" SG_ 764 SDARS_Channel_Lock2 3;
BA_ "U_CD542_MY2021_Rx" SG_ 628 CamraRearBttn_D_Stat_UB 1;
BA_ "U_U55X_MY2022_Rx" SG_ 628 CamraRearBttn_D_Stat_UB 1;
BA_ "U_T6_MCA_MY2020_Rx" SG_ 628 CamraRearBttn_D_Stat_UB 1;
BA_ "U_P702_MY2021_Rx" SG_ 628 CamraRearBttn_D_Stat_UB 1;
BA_ "U_CD764_MY2022_Rx" SG_ 628 CamraRearBttn_D_Stat 1;
BA_ "U_CD542_MY2021_Rx" SG_ 628 CamraRearBttn_D_Stat 1;
BA_ "U_U55X_MY2022_Rx" SG_ 628 CamraRearBttn_D_Stat 1;
BA_ "U_T6_MCA_MY2020_Rx" SG_ 628 CamraRearBttn_D_Stat 1;
BA_ "U_P702_MY2021_Rx" SG_ 628 CamraRearBttn_D_Stat 1;
BA_ "GenSigSendType" SG_ 628 CamraRearBttn_D_Stat 3;
BA_ "U_U55X_MY2022_Rx" SG_ 628 GearEngag_D_Actl_UB 1;
BA_ "U_CD542_MY2021_Rx" SG_ 628 GearEngag_D_Actl_UB 1;
BA_ "U_T6_MCA_MY2020_Rx" SG_ 628 GearEngag_D_Actl_UB 1;
BA_ "U_U55X_MY2022_Rx" SG_ 628 GearEngag_D_Actl 1;
BA_ "U_CD542_MY2021_Rx" SG_ 628 GearEngag_D_Actl 1;
BA_ "U_T6_MCA_MY2020_Rx" SG_ 628 GearEngag_D_Actl 1;
BA_ "GenSigSendType" SG_ 628 GearEngag_D_Actl 3;
BA_ "U_U55X_MY2022_Rx" SG_ 628 RvltnMatchAllw_D_Stat_UB 1;
BA_ "U_CD542_MY2021_Rx" SG_ 628 RvltnMatchAllw_D_Stat_UB 1;
BA_ "U_T6_MCA_MY2020_Rx" SG_ 628 RvltnMatchAllw_D_Stat_UB 1;
BA_ "U_U55X_MY2022_Rx" SG_ 628 RvltnMatchAllw_D_Stat 1;
BA_ "U_CD542_MY2021_Rx" SG_ 628 RvltnMatchAllw_D_Stat 1;
BA_ "U_T6_MCA_MY2020_Rx" SG_ 628 RvltnMatchAllw_D_Stat 1;
BA_ "GenSigSendType" SG_ 628 RvltnMatchAllw_D_Stat 3;
BA_ "U_CD764_MY2022_Rx" SG_ 628 SeatScrnPsngrOn_B_Rq 1;
BA_ "U_U55X_MY2022_Rx" SG_ 628 SeatScrnPsngrOn_B_Rq 1;
BA_ "U_CD542_MY2021_Rx" SG_ 628 SeatScrnPsngrOn_B_Rq 1;
BA_ "U_T6_MCA_MY2020_Rx" SG_ 628 SeatScrnPsngrOn_B_Rq 1;
BA_ "U_P702_MY2021_Rx" SG_ 628 SeatScrnPsngrOn_B_Rq 1;
BA_ "GenSigSendType" SG_ 628 SeatScrnPsngrOn_B_Rq 3;
BA_ "U_CD764_MY2022_Rx" SG_ 628 SeatScrnPsngrOn_B_Rq_UB 1;
BA_ "U_U55X_MY2022_Rx" SG_ 628 SeatScrnPsngrOn_B_Rq_UB 1;
BA_ "U_CD542_MY2021_Rx" SG_ 628 SeatScrnPsngrOn_B_Rq_UB 1;
BA_ "U_T6_MCA_MY2020_Rx" SG_ 628 SeatScrnPsngrOn_B_Rq_UB 1;
BA_ "U_P702_MY2021_Rx" SG_ 628 SeatScrnPsngrOn_B_Rq_UB 1;
BA_ "U_CD542_MY2021_Rx" SG_ 628 CamraRearOn_B_RqBalrl_UB 1;
BA_ "U_T6_MCA_MY2020_Rx" SG_ 628 CamraRearOn_B_RqBalrl_UB 1;
BA_ "U_P702_MY2021_Rx" SG_ 628 CamraRearOn_B_RqBalrl_UB 1;
BA_ "U_CD542_MY2021_Rx" SG_ 628 CamraRearOn_B_RqBalrr_UB 1;
BA_ "U_T6_MCA_MY2020_Rx" SG_ 628 CamraRearOn_B_RqBalrr_UB 1;
BA_ "U_P702_MY2021_Rx" SG_ 628 CamraRearOn_B_RqBalrr_UB 1;
BA_ "U_CD542_MY2021_Rx" SG_ 628 CamraRearOn_B_RqBalrr 1;
BA_ "U_T6_MCA_MY2020_Rx" SG_ 628 CamraRearOn_B_RqBalrr 1;
BA_ "U_P702_MY2021_Rx" SG_ 628 CamraRearOn_B_RqBalrr 1;
BA_ "GenSigSendType" SG_ 628 CamraRearOn_B_RqBalrr 3;
BA_ "U_CD542_MY2021_Rx" SG_ 628 CamraRearOn_B_RqBalrl 1;
BA_ "U_T6_MCA_MY2020_Rx" SG_ 628 CamraRearOn_B_RqBalrl 1;
BA_ "U_P702_MY2021_Rx" SG_ 628 CamraRearOn_B_RqBalrl 1;
BA_ "GenSigSendType" SG_ 628 CamraRearOn_B_RqBalrl 3;
BA_ "U_CD764_MY2022_Rx" SG_ 628 PwFlwFuelDrv_D_Dsply 1;
BA_ "U_U55X_MY2022_Rx" SG_ 628 PwFlwFuelDrv_D_Dsply 1;
BA_ "U_CD542_MY2021_Rx" SG_ 628 PwFlwFuelDrv_D_Dsply 1;
BA_ "U_T6_MCA_MY2020_Rx" SG_ 628 PwFlwFuelDrv_D_Dsply 1;
BA_ "U_P702_MY2021_Rx" SG_ 628 PwFlwFuelDrv_D_Dsply 1;
BA_ "GenSigSendType" SG_ 628 PwFlwFuelDrv_D_Dsply 3;
BA_ "U_CD764_MY2022_Rx" SG_ 628 PwFlwFuelClimt_B_Dsply 1;
BA_ "U_U55X_MY2022_Rx" SG_ 628 PwFlwFuelClimt_B_Dsply 1;
BA_ "U_CD542_MY2021_Rx" SG_ 628 PwFlwFuelClimt_B_Dsply 1;
BA_ "U_T6_MCA_MY2020_Rx" SG_ 628 PwFlwFuelClimt_B_Dsply 1;
BA_ "U_P702_MY2021_Rx" SG_ 628 PwFlwFuelClimt_B_Dsply 1;
BA_ "GenSigSendType" SG_ 628 PwFlwFuelClimt_B_Dsply 3;
BA_ "U_CD764_MY2022_Rx" SG_ 628 PwFlwFuelBatt_B_Dsply 1;
BA_ "U_U55X_MY2022_Rx" SG_ 628 PwFlwFuelBatt_B_Dsply 1;
BA_ "U_CD542_MY2021_Rx" SG_ 628 PwFlwFuelBatt_B_Dsply 1;
BA_ "U_T6_MCA_MY2020_Rx" SG_ 628 PwFlwFuelBatt_B_Dsply 1;
BA_ "U_P702_MY2021_Rx" SG_ 628 PwFlwFuelBatt_B_Dsply 1;
BA_ "GenSigSendType" SG_ 628 PwFlwFuelBatt_B_Dsply 3;
BA_ "U_CD764_MY2022_Rx" SG_ 628 PwFlwBattGen_D_Dsply 1;
BA_ "U_U55X_MY2022_Rx" SG_ 628 PwFlwBattGen_D_Dsply 1;
BA_ "U_CD542_MY2021_Rx" SG_ 628 PwFlwBattGen_D_Dsply 1;
BA_ "U_T6_MCA_MY2020_Rx" SG_ 628 PwFlwBattGen_D_Dsply 1;
BA_ "U_P702_MY2021_Rx" SG_ 628 PwFlwBattGen_D_Dsply 1;
BA_ "GenSigSendType" SG_ 628 PwFlwBattGen_D_Dsply 3;
BA_ "U_CD764_MY2022_Rx" SG_ 628 PwFlwBattClimt_B_Dsply 1;
BA_ "U_U55X_MY2022_Rx" SG_ 628 PwFlwBattClimt_B_Dsply 1;
BA_ "U_CD542_MY2021_Rx" SG_ 628 PwFlwBattClimt_B_Dsply 1;
BA_ "U_T6_MCA_MY2020_Rx" SG_ 628 PwFlwBattClimt_B_Dsply 1;
BA_ "U_P702_MY2021_Rx" SG_ 628 PwFlwBattClimt_B_Dsply 1;
BA_ "GenSigSendType" SG_ 628 PwFlwBattClimt_B_Dsply 3;
BA_ "U_CD764_MY2022_Rx" SG_ 628 PwFlwBatt_D_Dsply 1;
BA_ "U_U55X_MY2022_Rx" SG_ 628 PwFlwBatt_D_Dsply 1;
BA_ "U_CD542_MY2021_Rx" SG_ 628 PwFlwBatt_D_Dsply 1;
BA_ "U_T6_MCA_MY2020_Rx" SG_ 628 PwFlwBatt_D_Dsply 1;
BA_ "U_P702_MY2021_Rx" SG_ 628 PwFlwBatt_D_Dsply 1;
BA_ "GenSigSendType" SG_ 628 PwFlwBatt_D_Dsply 3;
BA_ "U_CD764_MY2022_Rx" SG_ 628 PwFlwFuelDrv_D_Dsply_UB 1;
BA_ "U_U55X_MY2022_Rx" SG_ 628 PwFlwFuelDrv_D_Dsply_UB 1;
BA_ "U_CD542_MY2021_Rx" SG_ 628 PwFlwFuelDrv_D_Dsply_UB 1;
BA_ "U_T6_MCA_MY2020_Rx" SG_ 628 PwFlwFuelDrv_D_Dsply_UB 1;
BA_ "U_P702_MY2021_Rx" SG_ 628 PwFlwFuelDrv_D_Dsply_UB 1;
BA_ "U_CD764_MY2022_Rx" SG_ 628 PwFlwFuelClimt_B_Dsply_UB 1;
BA_ "U_U55X_MY2022_Rx" SG_ 628 PwFlwFuelClimt_B_Dsply_UB 1;
BA_ "U_CD542_MY2021_Rx" SG_ 628 PwFlwFuelClimt_B_Dsply_UB 1;
BA_ "U_T6_MCA_MY2020_Rx" SG_ 628 PwFlwFuelClimt_B_Dsply_UB 1;
BA_ "U_P702_MY2021_Rx" SG_ 628 PwFlwFuelClimt_B_Dsply_UB 1;
BA_ "U_CD764_MY2022_Rx" SG_ 628 PwFlwFuelBatt_B_Dsply_UB 1;
BA_ "U_U55X_MY2022_Rx" SG_ 628 PwFlwFuelBatt_B_Dsply_UB 1;
BA_ "U_CD542_MY2021_Rx" SG_ 628 PwFlwFuelBatt_B_Dsply_UB 1;
BA_ "U_T6_MCA_MY2020_Rx" SG_ 628 PwFlwFuelBatt_B_Dsply_UB 1;
BA_ "U_P702_MY2021_Rx" SG_ 628 PwFlwFuelBatt_B_Dsply_UB 1;
BA_ "U_CD764_MY2022_Rx" SG_ 628 PwFlwBattGen_D_Dsply_UB 1;
BA_ "U_U55X_MY2022_Rx" SG_ 628 PwFlwBattGen_D_Dsply_UB 1;
BA_ "U_CD542_MY2021_Rx" SG_ 628 PwFlwBattGen_D_Dsply_UB 1;
BA_ "U_T6_MCA_MY2020_Rx" SG_ 628 PwFlwBattGen_D_Dsply_UB 1;
BA_ "U_P702_MY2021_Rx" SG_ 628 PwFlwBattGen_D_Dsply_UB 1;
BA_ "U_CD764_MY2022_Rx" SG_ 628 PwFlwBattClimt_B_Dsply_UB 1;
BA_ "U_U55X_MY2022_Rx" SG_ 628 PwFlwBattClimt_B_Dsply_UB 1;
BA_ "U_CD542_MY2021_Rx" SG_ 628 PwFlwBattClimt_B_Dsply_UB 1;
BA_ "U_T6_MCA_MY2020_Rx" SG_ 628 PwFlwBattClimt_B_Dsply_UB 1;
BA_ "U_P702_MY2021_Rx" SG_ 628 PwFlwBattClimt_B_Dsply_UB 1;
BA_ "U_CD764_MY2022_Rx" SG_ 628 PwFlwBatt_D_Dsply_UB 1;
BA_ "U_U55X_MY2022_Rx" SG_ 628 PwFlwBatt_D_Dsply_UB 1;
BA_ "U_CD542_MY2021_Rx" SG_ 628 PwFlwBatt_D_Dsply_UB 1;
BA_ "U_T6_MCA_MY2020_Rx" SG_ 628 PwFlwBatt_D_Dsply_UB 1;
BA_ "U_P702_MY2021_Rx" SG_ 628 PwFlwBatt_D_Dsply_UB 1;
BA_ "U_U55X_MY2022_Rx" SG_ 628 TrailCtlMsgTxt_D_Rq 1;
BA_ "U_T6_MCA_MY2020_Rx" SG_ 628 TrailCtlMsgTxt_D_Rq 1;
BA_ "GenSigSendType" SG_ 628 TrailCtlMsgTxt_D_Rq 3;
BA_ "U_U55X_MY2022_Rx" SG_ 628 TrailCtlMsgTxt_D_Rq_UB 1;
BA_ "U_T6_MCA_MY2020_Rx" SG_ 628 TrailCtlMsgTxt_D_Rq_UB 1;
BA_ "U_U55X_MY2022_Rx" SG_ 628 TrailCtl_D_Stat_UB 1;
BA_ "U_T6_MCA_MY2020_Rx" SG_ 628 TrailCtl_D_Stat_UB 1;
BA_ "U_U55X_MY2022_Rx" SG_ 628 TrailCtl_D_Stat 1;
BA_ "U_T6_MCA_MY2020_Rx" SG_ 628 TrailCtl_D_Stat 1;
BA_ "GenSigSendType" SG_ 628 TrailCtl_D_Stat 3;
BA_ "U_U55X_MY2022_Rx" SG_ 628 Veh_V_DsplyTrailCtlSet 1;
BA_ "U_T6_MCA_MY2020_Rx" SG_ 628 Veh_V_DsplyTrailCtlSet 1;
BA_ "GenSigSendType" SG_ 628 Veh_V_DsplyTrailCtlSet 3;
BA_ "U_U55X_MY2022_Rx" SG_ 628 Veh_V_DsplyTrailCtlSet_UB 1;
BA_ "U_T6_MCA_MY2020_Rx" SG_ 628 Veh_V_DsplyTrailCtlSet_UB 1;
BA_ "U_CD764_MY2022_Rx" SG_ 628 SeatScrnDrvOn_B_Rq_UB 1;
BA_ "U_CD542_MY2021_Rx" SG_ 628 SeatScrnDrvOn_B_Rq_UB 1;
BA_ "U_U55X_MY2022_Rx" SG_ 628 SeatScrnDrvOn_B_Rq_UB 1;
BA_ "U_T6_MCA_MY2020_Rx" SG_ 628 SeatScrnDrvOn_B_Rq_UB 1;
BA_ "U_P702_MY2021_Rx" SG_ 628 SeatScrnDrvOn_B_Rq_UB 1;
BA_ "U_CD764_MY2022_Rx" SG_ 628 SeatScrnDrvOn_B_Rq 1;
BA_ "U_CD542_MY2021_Rx" SG_ 628 SeatScrnDrvOn_B_Rq 1;
BA_ "U_U55X_MY2022_Rx" SG_ 628 SeatScrnDrvOn_B_Rq 1;
BA_ "U_T6_MCA_MY2020_Rx" SG_ 628 SeatScrnDrvOn_B_Rq 1;
BA_ "U_P702_MY2021_Rx" SG_ 628 SeatScrnDrvOn_B_Rq 1;
BA_ "GenSigSendType" SG_ 628 SeatScrnDrvOn_B_Rq 3;
BA_ "WakeupSignal" SG_ 628 SeatScrnDrvOn_B_Rq 1;
BA_ "U_CD542_MY2021_Rx" SG_ 710 BEZEL_RDISP_WORD_Tx 1;
BA_ "U_U55X_MY2022_Rx" SG_ 710 BEZEL_RDISP_WORD_Tx 1;
BA_ "U_T6_MCA_MY2020_Rx" SG_ 710 BEZEL_RDISP_WORD_Tx 1;
BA_ "U_U55X_MY2022_Rx" SG_ 770 ScMnSoc_Pc_Actl 1;
BA_ "GenSigStartValue" SG_ 770 ScMnSoc_Pc_Actl 100;
BA_ "GenSigStartValue" SG_ 770 CurntTrgtSoc_Pc_Rq 100;
BA_ "U_CD764_MY2022_Rx" SG_ 770 FstChrgBulk_T_Est 1;
BA_ "U_U55X_MY2022_Rx" SG_ 770 FstChrgBulk_T_Est 1;
BA_ "U_CD542_MY2021_Rx" SG_ 770 FstChrgBulk_T_Est 1;
BA_ "U_CD764_MY2022_Rx" SG_ 770 CurntTrgtSoc_Pc_Dsply 1;
BA_ "U_U55X_MY2022_Rx" SG_ 770 CurntTrgtSoc_Pc_Dsply 1;
BA_ "U_CD542_MY2021_Rx" SG_ 770 CurntTrgtSoc_Pc_Dsply 1;
BA_ "GenSigStartValue" SG_ 770 CurntTrgtSoc_Pc_Dsply 100;
BA_ "U_U55X_MY2022_Rx" SG_ 770 ScLocIdCurnt_No_Stat 1;
BA_ "U_U55X_MY2022_Rx" SG_ 770 ScEnbl_B_Stat 1;
BA_ "U_CD542_MY2021_Rx" SG_ 785 BattTracLimPerf_D_Dsply 1;
BA_ "U_CD764_MY2022_Rx" SG_ 785 EcoIdl_D_Stat 1;
BA_ "U_U55X_MY2022_Rx" SG_ 785 EcoIdl_D_Stat 1;
BA_ "U_U55X_MY2022_Rx" SG_ 785 DteVehOffst_L_Dsply 1;
BA_ "U_CD542_MY2021_Rx" SG_ 785 DteVehOffst_L_Dsply 1;
BA_ "U_T6_MCA_MY2020_Rx" SG_ 785 DteVehOffst_L_Dsply 1;
BA_ "GenSigStartValue" SG_ 785 DteVehOffst_L_Dsply 8190;
BA_ "U_U55X_MY2022_Rx" SG_ 785 DteVehOffstMsgTxt_D_Rq 1;
BA_ "U_CD542_MY2021_Rx" SG_ 785 DteVehOffstMsgTxt_D_Rq 1;
BA_ "U_T6_MCA_MY2020_Rx" SG_ 785 DteVehOffstMsgTxt_D_Rq 1;
BA_ "U_CD542_MY2021_Rx" SG_ 785 PwPckTqRdyChime_B_Rq 1;
BA_ "U_T6_MCA_MY2020_Rx" SG_ 785 PwPckTqRdyChime_B_Rq 1;
BA_ "U_CD764_MY2022_Rx" SG_ 785 BattTracLoThres_D_Stat 1;
BA_ "U_U55X_MY2022_Rx" SG_ 785 BattTracLoThres_D_Stat 1;
BA_ "U_CD542_MY2021_Rx" SG_ 785 BattTracLoThres_D_Stat 1;
BA_ "U_CD542_MY2021_Rx" SG_ 785 BattTracLoMsgTxt_D_Rq 1;
BA_ "U_T6_MCA_MY2020_Rx" SG_ 785 BattTracLoMsgTxt_D_Rq 1;
BA_ "U_U55X_MY2022_Rx" SG_ 785 DestSocRqd_Pc_Dsply 1;
BA_ "U_CD542_MY2021_Rx" SG_ 785 DestSocRqd_Pc_Dsply 1;
BA_ "U_T6_MCA_MY2020_Rx" SG_ 785 DestSocRqd_Pc_Dsply 1;
BA_ "U_U55X_MY2022_Rx" SG_ 785 DestChrgEndMin_No_Actl 1;
BA_ "U_CD542_MY2021_Rx" SG_ 785 DestChrgEndMin_No_Actl 1;
BA_ "U_T6_MCA_MY2020_Rx" SG_ 785 DestChrgEndMin_No_Actl 1;
BA_ "U_U55X_MY2022_Rx" SG_ 785 DestChrgEndHr_No_Actl 1;
BA_ "U_CD542_MY2021_Rx" SG_ 785 DestChrgEndHr_No_Actl 1;
BA_ "U_T6_MCA_MY2020_Rx" SG_ 785 DestChrgEndHr_No_Actl 1;
BA_ "U_U55X_MY2022_Rx" SG_ 785 DestChrgEndDay_No_Actl 1;
BA_ "U_CD542_MY2021_Rx" SG_ 785 DestChrgEndDay_No_Actl 1;
BA_ "U_T6_MCA_MY2020_Rx" SG_ 785 DestChrgEndDay_No_Actl 1;
BA_ "GenSigStartValue" SG_ 785 DestChrgEndDay_No_Actl 1;
BA_ "U_CD764_MY2022_Rx" SG_ 785 BattTracLoSoc_D_Dsply 1;
BA_ "U_U55X_MY2022_Rx" SG_ 785 BattTracLoSoc_D_Dsply 1;
BA_ "U_CD542_MY2021_Rx" SG_ 785 BattTracLoSoc_D_Dsply 1;
BA_ "U_T6_MCA_MY2020_Rx" SG_ 785 BattTracLoSoc_D_Dsply 1;
BA_ "U_U55X_MY2022_Tx" SG_ 1202 SDARS_VR_WORD_Rx 1;
BA_ "U_CD542_MY2021_Tx" SG_ 1202 SDARS_VR_WORD_Rx 1;
BA_ "U_T6_MCA_MY2020_Tx" SG_ 1202 SDARS_VR_WORD_Rx 1;
BA_ "U_T6_MCA_MY2020_Rx" SG_ 1202 SDARS_VR_WORD_Rx 1;
BA_ "U_U55X_MY2022_Tx" SG_ 1210 SDARS_VR_WORD_Tx 1;
BA_ "U_T6_MCA_MY2020_Tx" SG_ 1210 SDARS_VR_WORD_Tx 1;
BA_ "U_U55X_MY2022_Rx" SG_ 1210 SDARS_VR_WORD_Tx 1;
BA_ "U_CD542_MY2021_Rx" SG_ 1210 SDARS_VR_WORD_Tx 1;
BA_ "U_T6_MCA_MY2020_Rx" SG_ 1210 SDARS_VR_WORD_Tx 1;
BA_ "U_T6_MCA_MY2020_Tx" SG_ 391 ACU_CtrlChimeChan_Rq 1;
BA_ "U_CD764_MY2022_Rx" SG_ 391 ACU_CtrlChimeChan_Rq 1;
BA_ "U_CD542_MY2021_Rx" SG_ 391 ACU_CtrlChimeChan_Rq 1;
BA_ "U_T6_MCA_MY2020_Rx" SG_ 391 ACU_CtrlChimeChan_Rq 1;
BA_ "GenSigSendType" SG_ 391 ACU_CtrlChimeChan_Rq 3;
BA_ "U_U55X_MY2022_Tx" SG_ 415 LBC3_StartItemInd 1;
BA_ "U_CD542_MY2021_Rx" SG_ 415 LBC3_StartItemInd 1;
BA_ "U_U55X_MY2022_Rx" SG_ 415 LBC3_StartItemInd 1;
BA_ "U_U55X_MY2022_Tx" SG_ 415 LBC3_SetListServ 1;
BA_ "U_CD542_MY2021_Rx" SG_ 415 LBC3_SetListServ 1;
BA_ "U_U55X_MY2022_Rx" SG_ 415 LBC3_SetListServ 1;
BA_ "U_U55X_MY2022_Tx" SG_ 415 LBC3_Opcode 1;
BA_ "U_CD542_MY2021_Rx" SG_ 415 LBC3_Opcode 1;
BA_ "U_U55X_MY2022_Rx" SG_ 415 LBC3_Opcode 1;
BA_ "GenSigSendType" SG_ 415 LBC3_Opcode 3;
BA_ "U_U55X_MY2022_Tx" SG_ 415 LBC3_NbrOfItems 1;
BA_ "U_CD542_MY2021_Rx" SG_ 415 LBC3_NbrOfItems 1;
BA_ "U_U55X_MY2022_Rx" SG_ 415 LBC3_NbrOfItems 1;
BA_ "U_U55X_MY2022_Tx" SG_ 415 LBC3_ItemIndex 1;
BA_ "U_CD542_MY2021_Rx" SG_ 415 LBC3_ItemIndex 1;
BA_ "U_U55X_MY2022_Rx" SG_ 415 LBC3_ItemIndex 1;
BA_ "U_U55X_MY2022_Tx" SG_ 415 LBC3_ActiveListID 1;
BA_ "U_CD542_MY2021_Rx" SG_ 415 LBC3_ActiveListID 1;
BA_ "U_U55X_MY2022_Rx" SG_ 415 LBC3_ActiveListID 1;
BA_ "U_CD764_MY2022_Tx" SG_ 703 CONMP_MC_WORD_Rx 1;
BA_ "U_CD542_MY2021_Tx" SG_ 703 CONMP_MC_WORD_Rx 1;
BA_ "U_CD764_MY2022_Rx" SG_ 703 CONMP_MC_WORD_Rx 1;
BA_ "U_U55X_MY2022_Rx" SG_ 703 CONMP_MC_WORD_Rx 1;
BA_ "U_CD542_MY2021_Rx" SG_ 703 CONMP_MC_WORD_Rx 1;
BA_ "U_T6_MCA_MY2020_Rx" SG_ 703 CONMP_MC_WORD_Rx 1;
BA_ "U_CD764_MY2022_Tx" SG_ 695 CONMP_MC_WORD_Tx 1;
BA_ "U_U55X_MY2022_Tx" SG_ 695 CONMP_MC_WORD_Tx 1;
BA_ "U_CD542_MY2021_Tx" SG_ 695 CONMP_MC_WORD_Tx 1;
BA_ "U_T6_MCA_MY2020_Tx" SG_ 695 CONMP_MC_WORD_Tx 1;
BA_ "U_CD764_MY2022_Rx" SG_ 695 CONMP_MC_WORD_Tx 1;
BA_ "U_CD542_MY2021_Rx" SG_ 695 CONMP_MC_WORD_Tx 1;
BA_ "U_T6_MCA_MY2020_Rx" SG_ 695 CONMP_MC_WORD_Tx 1;
BA_ "U_U55X_MY2022_Tx" SG_ 501 Dsp_PresetArea_Rq 1;
BA_ "U_CD542_MY2021_Tx" SG_ 501 Dsp_PresetArea_Rq 1;
BA_ "U_T6_MCA_MY2020_Tx" SG_ 501 Dsp_PresetArea_Rq 1;
BA_ "U_P702_MY2021_Tx" SG_ 501 Dsp_PresetArea_Rq 1;
BA_ "U_U55X_MY2022_Rx" SG_ 501 Dsp_PresetArea_Rq 1;
BA_ "U_CD542_MY2021_Rx" SG_ 501 Dsp_PresetArea_Rq 1;
BA_ "U_T6_MCA_MY2020_Rx" SG_ 501 Dsp_PresetArea_Rq 1;
BA_ "GenSigSendType" SG_ 501 Dsp_PresetArea_Rq 3;
BA_ "U_U55X_MY2022_Tx" SG_ 501 Dsp_StartIndex2_Rq 1;
BA_ "U_CD542_MY2021_Tx" SG_ 501 Dsp_StartIndex2_Rq 1;
BA_ "U_T6_MCA_MY2020_Tx" SG_ 501 Dsp_StartIndex2_Rq 1;
BA_ "U_P702_MY2021_Tx" SG_ 501 Dsp_StartIndex2_Rq 1;
BA_ "U_U55X_MY2022_Rx" SG_ 501 Dsp_StartIndex2_Rq 1;
BA_ "U_CD542_MY2021_Rx" SG_ 501 Dsp_StartIndex2_Rq 1;
BA_ "U_T6_MCA_MY2020_Rx" SG_ 501 Dsp_StartIndex2_Rq 1;
BA_ "U_U55X_MY2022_Tx" SG_ 501 Dsp_SetRadSeekMode_Rq 1;
BA_ "U_CD542_MY2021_Tx" SG_ 501 Dsp_SetRadSeekMode_Rq 1;
BA_ "U_T6_MCA_MY2020_Tx" SG_ 501 Dsp_SetRadSeekMode_Rq 1;
BA_ "U_P702_MY2021_Tx" SG_ 501 Dsp_SetRadSeekMode_Rq 1;
BA_ "U_U55X_MY2022_Rx" SG_ 501 Dsp_SetRadSeekMode_Rq 1;
BA_ "U_CD542_MY2021_Rx" SG_ 501 Dsp_SetRadSeekMode_Rq 1;
BA_ "U_T6_MCA_MY2020_Rx" SG_ 501 Dsp_SetRadSeekMode_Rq 1;
BA_ "GenSigSendType" SG_ 501 Dsp_SetRadSeekMode_Rq 3;
BA_ "U_U55X_MY2022_Tx" SG_ 501 Dsp_SetCurrPreset2_Rq 1;
BA_ "U_CD542_MY2021_Tx" SG_ 501 Dsp_SetCurrPreset2_Rq 1;
BA_ "U_T6_MCA_MY2020_Tx" SG_ 501 Dsp_SetCurrPreset2_Rq 1;
BA_ "U_P702_MY2021_Tx" SG_ 501 Dsp_SetCurrPreset2_Rq 1;
BA_ "U_U55X_MY2022_Rx" SG_ 501 Dsp_SetCurrPreset2_Rq 1;
BA_ "U_CD542_MY2021_Rx" SG_ 501 Dsp_SetCurrPreset2_Rq 1;
BA_ "U_T6_MCA_MY2020_Rx" SG_ 501 Dsp_SetCurrPreset2_Rq 1;
BA_ "GenSigSendType" SG_ 501 Dsp_SetCurrPreset2_Rq 3;
BA_ "U_U55X_MY2022_Tx" SG_ 501 Dsp_SetCurrFMSLPr_Rq 1;
BA_ "U_CD542_MY2021_Tx" SG_ 501 Dsp_SetCurrFMSLPr_Rq 1;
BA_ "U_T6_MCA_MY2020_Tx" SG_ 501 Dsp_SetCurrFMSLPr_Rq 1;
BA_ "U_P702_MY2021_Tx" SG_ 501 Dsp_SetCurrFMSLPr_Rq 1;
BA_ "U_U55X_MY2022_Rx" SG_ 501 Dsp_SetCurrFMSLPr_Rq 1;
BA_ "U_CD542_MY2021_Rx" SG_ 501 Dsp_SetCurrFMSLPr_Rq 1;
BA_ "U_T6_MCA_MY2020_Rx" SG_ 501 Dsp_SetCurrFMSLPr_Rq 1;
BA_ "GenSigSendType" SG_ 501 Dsp_SetCurrFMSLPr_Rq 3;
BA_ "U_U55X_MY2022_Tx" SG_ 501 Dsp_SetCRadioBand_Rq 1;
BA_ "U_CD542_MY2021_Tx" SG_ 501 Dsp_SetCRadioBand_Rq 1;
BA_ "U_T6_MCA_MY2020_Tx" SG_ 501 Dsp_SetCRadioBand_Rq 1;
BA_ "U_P702_MY2021_Tx" SG_ 501 Dsp_SetCRadioBand_Rq 1;
BA_ "U_U55X_MY2022_Rx" SG_ 501 Dsp_SetCRadioBand_Rq 1;
BA_ "U_CD542_MY2021_Rx" SG_ 501 Dsp_SetCRadioBand_Rq 1;
BA_ "U_T6_MCA_MY2020_Rx" SG_ 501 Dsp_SetCRadioBand_Rq 1;
BA_ "GenSigSendType" SG_ 501 Dsp_SetCRadioBand_Rq 3;
BA_ "U_U55X_MY2022_Tx" SG_ 501 Dsp_NbrOfPresets_Rq 1;
BA_ "U_CD542_MY2021_Tx" SG_ 501 Dsp_NbrOfPresets_Rq 1;
BA_ "U_T6_MCA_MY2020_Tx" SG_ 501 Dsp_NbrOfPresets_Rq 1;
BA_ "U_P702_MY2021_Tx" SG_ 501 Dsp_NbrOfPresets_Rq 1;
BA_ "U_U55X_MY2022_Rx" SG_ 501 Dsp_NbrOfPresets_Rq 1;
BA_ "U_CD542_MY2021_Rx" SG_ 501 Dsp_NbrOfPresets_Rq 1;
BA_ "U_T6_MCA_MY2020_Rx" SG_ 501 Dsp_NbrOfPresets_Rq 1;
BA_ "U_U55X_MY2022_Tx" SG_ 501 Dsp_FreezeFMSL_Rq 1;
BA_ "U_CD542_MY2021_Tx" SG_ 501 Dsp_FreezeFMSL_Rq 1;
BA_ "U_T6_MCA_MY2020_Tx" SG_ 501 Dsp_FreezeFMSL_Rq 1;
BA_ "U_P702_MY2021_Tx" SG_ 501 Dsp_FreezeFMSL_Rq 1;
BA_ "U_U55X_MY2022_Rx" SG_ 501 Dsp_FreezeFMSL_Rq 1;
BA_ "U_CD542_MY2021_Rx" SG_ 501 Dsp_FreezeFMSL_Rq 1;
BA_ "U_T6_MCA_MY2020_Rx" SG_ 501 Dsp_FreezeFMSL_Rq 1;
BA_ "U_P702_MY2021_Rx" SG_ 501 Dsp_FreezeFMSL_Rq 1;
BA_ "GenSigSendType" SG_ 501 Dsp_FreezeFMSL_Rq 3;
BA_ "U_T6_MCA_MY2020_Tx" SG_ 1506 APIM_GWOnBoardTester 1;
BA_ "U_P702_MY2021_Tx" SG_ 1506 APIM_GWOnBoardTester 1;
BA_ "U_CD764_MY2022_Tx" SG_ 1506 APIM_GWOnBoardTester 1;
BA_ "U_U55X_MY2022_Tx" SG_ 1506 APIM_GWOnBoardTester 1;
BA_ "U_CD542_MY2021_Tx" SG_ 1506 APIM_GWOnBoardTester 1;
BA_ "U_CD764_MY2022_Rx" SG_ 1506 APIM_GWOnBoardTester 1;
BA_ "U_U55X_MY2022_Rx" SG_ 1506 APIM_GWOnBoardTester 1;
BA_ "U_T6_MCA_MY2020_Rx" SG_ 1506 APIM_GWOnBoardTester 1;
BA_ "GenSigStartValue" SG_ 1506 APIM_GWOnBoardTester 255;
BA_ "ContentDependant" SG_ 1506 APIM_GWOnBoardTester 1;
BA_ "GenSigStartValueInteger" SG_ 1506 APIM_GWOnBoardTester 255;
BA_ "U_T6_MCA_MY2020_Tx" SG_ 1506 APIM_GWNMProxy 1;
BA_ "U_P702_MY2021_Tx" SG_ 1506 APIM_GWNMProxy 1;
BA_ "U_CD764_MY2022_Tx" SG_ 1506 APIM_GWNMProxy 1;
BA_ "U_U55X_MY2022_Tx" SG_ 1506 APIM_GWNMProxy 1;
BA_ "U_CD542_MY2021_Tx" SG_ 1506 APIM_GWNMProxy 1;
BA_ "U_CD764_MY2022_Rx" SG_ 1506 APIM_GWNMProxy 1;
BA_ "U_U55X_MY2022_Rx" SG_ 1506 APIM_GWNMProxy 1;
BA_ "U_T6_MCA_MY2020_Rx" SG_ 1506 APIM_GWNMProxy 1;
BA_ "GenSigStartValue" SG_ 1506 APIM_GWNMProxy 255;
BA_ "ContentDependant" SG_ 1506 APIM_GWNMProxy 1;
BA_ "GenSigStartValueInteger" SG_ 1506 APIM_GWNMProxy 255;
BA_ "U_T6_MCA_MY2020_Tx" SG_ 1506 APIM_AutoSarNMReserved4 1;
BA_ "U_P702_MY2021_Tx" SG_ 1506 APIM_AutoSarNMReserved4 1;
BA_ "U_CD764_MY2022_Tx" SG_ 1506 APIM_AutoSarNMReserved4 1;
BA_ "U_U55X_MY2022_Tx" SG_ 1506 APIM_AutoSarNMReserved4 1;
BA_ "U_CD542_MY2021_Tx" SG_ 1506 APIM_AutoSarNMReserved4 1;
BA_ "U_CD764_MY2022_Rx" SG_ 1506 APIM_AutoSarNMReserved4 1;
BA_ "U_U55X_MY2022_Rx" SG_ 1506 APIM_AutoSarNMReserved4 1;
BA_ "U_T6_MCA_MY2020_Rx" SG_ 1506 APIM_AutoSarNMReserved4 1;
BA_ "GenSigStartValue" SG_ 1506 APIM_AutoSarNMReserved4 255;
BA_ "ContentDependant" SG_ 1506 APIM_AutoSarNMReserved4 1;
BA_ "GenSigStartValueInteger" SG_ 1506 APIM_AutoSarNMReserved4 255;
BA_ "U_T6_MCA_MY2020_Tx" SG_ 1506 APIM_AutoSarNMReserved3 1;
BA_ "U_P702_MY2021_Tx" SG_ 1506 APIM_AutoSarNMReserved3 1;
BA_ "U_CD764_MY2022_Tx" SG_ 1506 APIM_AutoSarNMReserved3 1;
BA_ "U_U55X_MY2022_Tx" SG_ 1506 APIM_AutoSarNMReserved3 1;
BA_ "U_CD542_MY2021_Tx" SG_ 1506 APIM_AutoSarNMReserved3 1;
BA_ "U_CD764_MY2022_Rx" SG_ 1506 APIM_AutoSarNMReserved3 1;
BA_ "U_U55X_MY2022_Rx" SG_ 1506 APIM_AutoSarNMReserved3 1;
BA_ "U_T6_MCA_MY2020_Rx" SG_ 1506 APIM_AutoSarNMReserved3 1;
BA_ "GenSigStartValue" SG_ 1506 APIM_AutoSarNMReserved3 255;
BA_ "ContentDependant" SG_ 1506 APIM_AutoSarNMReserved3 1;
BA_ "GenSigStartValueInteger" SG_ 1506 APIM_AutoSarNMReserved3 255;
BA_ "U_T6_MCA_MY2020_Tx" SG_ 1506 APIM_AutoSarNMReserved2 1;
BA_ "U_P702_MY2021_Tx" SG_ 1506 APIM_AutoSarNMReserved2 1;
BA_ "U_CD764_MY2022_Tx" SG_ 1506 APIM_AutoSarNMReserved2 1;
BA_ "U_U55X_MY2022_Tx" SG_ 1506 APIM_AutoSarNMReserved2 1;
BA_ "U_CD542_MY2021_Tx" SG_ 1506 APIM_AutoSarNMReserved2 1;
BA_ "U_CD764_MY2022_Rx" SG_ 1506 APIM_AutoSarNMReserved2 1;
BA_ "U_U55X_MY2022_Rx" SG_ 1506 APIM_AutoSarNMReserved2 1;
BA_ "U_T6_MCA_MY2020_Rx" SG_ 1506 APIM_AutoSarNMReserved2 1;
BA_ "GenSigStartValue" SG_ 1506 APIM_AutoSarNMReserved2 255;
BA_ "ContentDependant" SG_ 1506 APIM_AutoSarNMReserved2 1;
BA_ "GenSigStartValueInteger" SG_ 1506 APIM_AutoSarNMReserved2 255;
BA_ "U_T6_MCA_MY2020_Tx" SG_ 1506 APIM_AutoSarNMReserved1 1;
BA_ "U_P702_MY2021_Tx" SG_ 1506 APIM_AutoSarNMReserved1 1;
BA_ "U_CD764_MY2022_Tx" SG_ 1506 APIM_AutoSarNMReserved1 1;
BA_ "U_U55X_MY2022_Tx" SG_ 1506 APIM_AutoSarNMReserved1 1;
BA_ "U_CD542_MY2021_Tx" SG_ 1506 APIM_AutoSarNMReserved1 1;
BA_ "U_CD764_MY2022_Rx" SG_ 1506 APIM_AutoSarNMReserved1 1;
BA_ "U_U55X_MY2022_Rx" SG_ 1506 APIM_AutoSarNMReserved1 1;
BA_ "U_T6_MCA_MY2020_Rx" SG_ 1506 APIM_AutoSarNMReserved1 1;
BA_ "GenSigStartValue" SG_ 1506 APIM_AutoSarNMReserved1 255;
BA_ "ContentDependant" SG_ 1506 APIM_AutoSarNMReserved1 1;
BA_ "GenSigStartValueInteger" SG_ 1506 APIM_AutoSarNMReserved1 255;
BA_ "U_T6_MCA_MY2020_Tx" SG_ 1506 APIM_AutoSarNMNodeId 1;
BA_ "U_P702_MY2021_Tx" SG_ 1506 APIM_AutoSarNMNodeId 1;
BA_ "U_CD764_MY2022_Tx" SG_ 1506 APIM_AutoSarNMNodeId 1;
BA_ "U_U55X_MY2022_Tx" SG_ 1506 APIM_AutoSarNMNodeId 1;
BA_ "U_CD542_MY2021_Tx" SG_ 1506 APIM_AutoSarNMNodeId 1;
BA_ "U_CD764_MY2022_Rx" SG_ 1506 APIM_AutoSarNMNodeId 1;
BA_ "U_U55X_MY2022_Rx" SG_ 1506 APIM_AutoSarNMNodeId 1;
BA_ "U_T6_MCA_MY2020_Rx" SG_ 1506 APIM_AutoSarNMNodeId 1;
BA_ "GenSigStartValue" SG_ 1506 APIM_AutoSarNMNodeId 226;
BA_ "ContentDependant" SG_ 1506 APIM_AutoSarNMNodeId 1;
BA_ "GenSigStartValueInteger" SG_ 1506 APIM_AutoSarNMNodeId 226;
BA_ "U_T6_MCA_MY2020_Tx" SG_ 1506 APIM_AutoSarNMControl 1;
BA_ "U_P702_MY2021_Tx" SG_ 1506 APIM_AutoSarNMControl 1;
BA_ "U_CD764_MY2022_Tx" SG_ 1506 APIM_AutoSarNMControl 1;
BA_ "U_U55X_MY2022_Tx" SG_ 1506 APIM_AutoSarNMControl 1;
BA_ "U_CD542_MY2021_Tx" SG_ 1506 APIM_AutoSarNMControl 1;
BA_ "U_CD764_MY2022_Rx" SG_ 1506 APIM_AutoSarNMControl 1;
BA_ "U_U55X_MY2022_Rx" SG_ 1506 APIM_AutoSarNMControl 1;
BA_ "U_T6_MCA_MY2020_Rx" SG_ 1506 APIM_AutoSarNMControl 1;
BA_ "ContentDependant" SG_ 1506 APIM_AutoSarNMControl 1;
BA_ "U_T6_MCA_MY2020_Rx" SG_ 651 TelematicsSrvc_D_St 1;
BA_ "U_P702_MY2021_Rx" SG_ 651 TelematicsSrvc_D_St 1;
BA_ "U_CD542_MY2021_Rx" SG_ 651 TelematicsSrvc_D_St 1;
BA_ "U_CD764_MY2022_Rx" SG_ 651 EmgcyCallMute_D_Stat 1;
BA_ "U_P702_MY2021_Rx" SG_ 651 EmgcyCallMute_D_Stat 1;
BA_ "U_U55X_MY2022_Rx" SG_ 651 EmgcyCallMute_D_Stat 1;
BA_ "U_CD542_MY2021_Rx" SG_ 651 EmgcyCallMute_D_Stat 1;
BA_ "U_T6_MCA_MY2020_Rx" SG_ 651 EmgcyCallMute_D_Stat 1;
BA_ "U_CD764_MY2022_Rx" SG_ 1098 EdmVeh_V_Dsply 1;
BA_ "U_U55X_MY2022_Rx" SG_ 1098 EdmVeh_V_Dsply 1;
BA_ "U_CD542_MY2021_Rx" SG_ 1098 EdmVeh_V_Dsply 1;
BA_ "U_T6_MCA_MY2020_Rx" SG_ 1098 EdmVeh_V_Dsply 1;
BA_ "U_P702_MY2021_Rx" SG_ 1098 EdmVeh_V_Dsply 1;
BA_ "U_CD764_MY2022_Rx" SG_ 1098 EdmSailMdeOn_B_Stat 1;
BA_ "U_U55X_MY2022_Rx" SG_ 1098 EdmSailMdeOn_B_Stat 1;
BA_ "U_CD542_MY2021_Rx" SG_ 1098 EdmSailMdeOn_B_Stat 1;
BA_ "U_T6_MCA_MY2020_Rx" SG_ 1098 EdmSailMdeOn_B_Stat 1;
BA_ "U_P702_MY2021_Rx" SG_ 1098 EdmSailMdeOn_B_Stat 1;
BA_ "U_CD764_MY2022_Rx" SG_ 1098 EdmPrev_Fe_Dsply 1;
BA_ "U_U55X_MY2022_Rx" SG_ 1098 EdmPrev_Fe_Dsply 1;
BA_ "U_CD542_MY2021_Rx" SG_ 1098 EdmPrev_Fe_Dsply 1;
BA_ "U_T6_MCA_MY2020_Rx" SG_ 1098 EdmPrev_Fe_Dsply 1;
BA_ "U_P702_MY2021_Rx" SG_ 1098 EdmPrev_Fe_Dsply 1;
BA_ "U_CD764_MY2022_Rx" SG_ 1098 EdmMsgTxt_D_Rq 1;
BA_ "U_U55X_MY2022_Rx" SG_ 1098 EdmMsgTxt_D_Rq 1;
BA_ "U_CD542_MY2021_Rx" SG_ 1098 EdmMsgTxt_D_Rq 1;
BA_ "U_T6_MCA_MY2020_Rx" SG_ 1098 EdmMsgTxt_D_Rq 1;
BA_ "U_P702_MY2021_Rx" SG_ 1098 EdmMsgTxt_D_Rq 1;
BA_ "U_CD542_MY2021_Rx" SG_ 1098 EdmLamp_D_Dsply 1;
BA_ "U_P702_MY2021_Rx" SG_ 1098 EdmLamp_D_Dsply 1;
BA_ "U_CD764_MY2022_Rx" SG_ 1098 EdmLamp_D_Dsply 1;
BA_ "U_U55X_MY2022_Rx" SG_ 1098 EdmLamp_D_Dsply 1;
BA_ "U_T6_MCA_MY2020_Rx" SG_ 1098 EdmLamp_D_Dsply 1;
BA_ "U_CD764_MY2022_Rx" SG_ 1098 EdmCurrent_Fe_Dsply 1;
BA_ "U_U55X_MY2022_Rx" SG_ 1098 EdmCurrent_Fe_Dsply 1;
BA_ "U_CD542_MY2021_Rx" SG_ 1098 EdmCurrent_Fe_Dsply 1;
BA_ "U_T6_MCA_MY2020_Rx" SG_ 1098 EdmCurrent_Fe_Dsply 1;
BA_ "U_P702_MY2021_Rx" SG_ 1098 EdmCurrent_Fe_Dsply 1;
BA_ "U_CD542_MY2021_Rx" SG_ 1098 EdmCmplnc_B_Dsply 1;
BA_ "U_P702_MY2021_Rx" SG_ 1098 EdmCmplnc_B_Dsply 1;
BA_ "U_CD764_MY2022_Rx" SG_ 1098 EdmCmplnc_B_Dsply 1;
BA_ "U_U55X_MY2022_Rx" SG_ 1098 EdmCmplnc_B_Dsply 1;
BA_ "U_T6_MCA_MY2020_Rx" SG_ 1098 EdmCmplnc_B_Dsply 1;
BA_ "U_CD764_MY2022_Rx" SG_ 1098 EdmCmplnc_Pc_Dsply 1;
BA_ "U_U55X_MY2022_Rx" SG_ 1098 EdmCmplnc_Pc_Dsply 1;
BA_ "U_CD542_MY2021_Rx" SG_ 1098 EdmCmplnc_Pc_Dsply 1;
BA_ "U_T6_MCA_MY2020_Rx" SG_ 1098 EdmCmplnc_Pc_Dsply 1;
BA_ "U_P702_MY2021_Rx" SG_ 1098 EdmCmplnc_Pc_Dsply 1;
BA_ "U_CD764_MY2022_Rx" SG_ 1098 EcoCochInstTot_Pc_Dsply 1;
BA_ "GenSigStartValue" SG_ 1098 EcoCochInstTot_Pc_Dsply 255;
BA_ "GenSigStartValueInteger" SG_ 1098 EcoCochInstTot_Pc_Dsply 255;
BA_ "U_U55X_MY2022_Rx" SG_ 629 GearPos_D_Actl_UB 1;
BA_ "U_T6_MCA_MY2020_Rx" SG_ 629 GearPos_D_Actl_UB 1;
BA_ "U_U55X_MY2022_Rx" SG_ 629 GearPos_D_Actl 1;
BA_ "U_T6_MCA_MY2020_Rx" SG_ 629 GearPos_D_Actl 1;
BA_ "GenSigSendType" SG_ 629 GearPos_D_Actl 3;
BA_ "GenSigStartValue" SG_ 629 GearPos_D_Actl 15;
BA_ "ContentDependant" SG_ 629 GearPos_D_Actl 1;
BA_ "GenSigStartValueInteger" SG_ 629 GearPos_D_Actl 15;
BA_ "U_U55X_MY2022_Rx" SG_ 629 BattTrac2_E_Max_UB 1;
BA_ "U_CD542_MY2021_Rx" SG_ 629 BattTrac2_E_Max_UB 1;
BA_ "U_U55X_MY2022_Rx" SG_ 629 BattTrac2_E_Avail_UB 1;
BA_ "U_CD542_MY2021_Rx" SG_ 629 BattTrac2_E_Avail_UB 1;
BA_ "U_U55X_MY2022_Rx" SG_ 629 BattTrac2_E_Max 1;
BA_ "U_CD542_MY2021_Rx" SG_ 629 BattTrac2_E_Max 1;
BA_ "GenSigStartValue" SG_ 629 BattTrac2_E_Max 4094;
BA_ "GenSigStartValueInteger" SG_ 629 BattTrac2_E_Max 4094;
BA_ "U_U55X_MY2022_Rx" SG_ 629 BattTrac2_E_Avail 1;
BA_ "U_CD542_MY2021_Rx" SG_ 629 BattTrac2_E_Avail 1;
BA_ "U_T6_MCA_MY2020_Rx" SG_ 629 BattULoChrgHyb_D_Stat_UB 1;
BA_ "U_U55X_MY2022_Rx" SG_ 629 TrnRng_D_Rq_UB 1;
BA_ "U_T6_MCA_MY2020_Rx" SG_ 629 TrnRng_D_Rq_UB 1;
BA_ "U_CD542_MY2021_Rx" SG_ 629 TrnRng_D_Rq_UB 1;
BA_ "U_U55X_MY2022_Rx" SG_ 629 TrnRng_D_Rq 1;
BA_ "U_T6_MCA_MY2020_Rx" SG_ 629 TrnRng_D_Rq 1;
BA_ "U_CD542_MY2021_Rx" SG_ 629 TrnRng_D_Rq 1;
BA_ "GenSigSendType" SG_ 629 TrnRng_D_Rq 3;
BA_ "GenSigStartValue" SG_ 629 TrnRng_D_Rq 14;
BA_ "ContentDependant" SG_ 629 TrnRng_D_Rq 1;
BA_ "GenSigStartValueInteger" SG_ 629 TrnRng_D_Rq 14;
BA_ "U_CD542_MY2021_Rx" SG_ 629 BattULoChrgHyb_D_Stat 1;
BA_ "U_T6_MCA_MY2020_Rx" SG_ 629 BattULoChrgHyb_D_Stat 1;
BA_ "GenSigSendType" SG_ 629 BattULoChrgHyb_D_Stat 3;
BA_ "U_CD542_MY2021_Rx" SG_ 629 BattTracHazrd_D_Stat_UB 1;
BA_ "U_CD542_MY2021_Rx" SG_ 629 BattTracHazrd_D_Stat 1;
BA_ "GenSigSendType" SG_ 629 BattTracHazrd_D_Stat 3;
BA_ "U_U55X_MY2022_Tx" SG_ 718 BEZEL_RDISP_WORD_Rx 1;
BA_ "U_CD542_MY2021_Tx" SG_ 718 BEZEL_RDISP_WORD_Rx 1;
BA_ "U_T6_MCA_MY2020_Tx" SG_ 718 BEZEL_RDISP_WORD_Rx 1;
BA_ "U_U55X_MY2022_Rx" SG_ 672 BCP_Audible_Beep_Rq 1;
BA_ "U_CD764_MY2022_Rx" SG_ 672 SetVolume 1;
BA_ "U_U55X_MY2022_Rx" SG_ 672 SetVolume 1;
BA_ "U_T6_MCA_MY2020_Rx" SG_ 672 SetVolume 1;
BA_ "GenSigSendType" SG_ 672 SetVolume 3;
BA_ "GenSigStartValue" SG_ 672 SetVolume 30;
BA_ "GenSigStartValueInteger" SG_ 672 SetVolume 30;
BA_ "WakeupSignal" SG_ 672 SetVolume 1;
BA_ "U_CD764_MY2022_Rx" SG_ 672 SetPointVolume 1;
BA_ "U_U55X_MY2022_Rx" SG_ 672 SetPointVolume 1;
BA_ "U_T6_MCA_MY2020_Rx" SG_ 672 SetPointVolume 1;
BA_ "GenSigSendType" SG_ 672 SetPointVolume 3;
BA_ "WakeupSignal" SG_ 672 SetPointVolume 1;
BA_ "U_CD542_MY2021_Rx" SG_ 672 Coding_BtnID_D 1;
BA_ "U_U55X_MY2022_Rx" SG_ 672 Coding_BtnID_D 1;
BA_ "U_T6_MCA_MY2020_Rx" SG_ 672 Coding_BtnID_D 1;
BA_ "GenSigSendType" SG_ 672 Coding_BtnID_D 3;
BA_ "WakeupSignal" SG_ 672 Coding_BtnID_D 1;
BA_ "U_CD542_MY2021_Rx" SG_ 672 Coding_BtnID_C 1;
BA_ "U_U55X_MY2022_Rx" SG_ 672 Coding_BtnID_C 1;
BA_ "U_T6_MCA_MY2020_Rx" SG_ 672 Coding_BtnID_C 1;
BA_ "GenSigSendType" SG_ 672 Coding_BtnID_C 3;
BA_ "WakeupSignal" SG_ 672 Coding_BtnID_C 1;
BA_ "U_CD542_MY2021_Rx" SG_ 672 Coding_BtnID_B 1;
BA_ "U_U55X_MY2022_Rx" SG_ 672 Coding_BtnID_B 1;
BA_ "U_T6_MCA_MY2020_Rx" SG_ 672 Coding_BtnID_B 1;
BA_ "GenSigSendType" SG_ 672 Coding_BtnID_B 3;
BA_ "WakeupSignal" SG_ 672 Coding_BtnID_B 1;
BA_ "U_CD542_MY2021_Rx" SG_ 672 Coding_BtnID_A 1;
BA_ "U_U55X_MY2022_Rx" SG_ 672 Coding_BtnID_A 1;
BA_ "U_T6_MCA_MY2020_Rx" SG_ 672 Coding_BtnID_A 1;
BA_ "GenSigSendType" SG_ 672 Coding_BtnID_A 3;
BA_ "WakeupSignal" SG_ 672 Coding_BtnID_A 1;
BA_ "U_CD764_MY2022_Rx" SG_ 672 BtnID_D 1;
BA_ "U_CD542_MY2021_Rx" SG_ 672 BtnID_D 1;
BA_ "U_U55X_MY2022_Rx" SG_ 672 BtnID_D 1;
BA_ "U_T6_MCA_MY2020_Rx" SG_ 672 BtnID_D 1;
BA_ "GenSigStartValue" SG_ 672 BtnID_D 255;
BA_ "GenSigStartValueInteger" SG_ 672 BtnID_D 255;
BA_ "WakeupSignal" SG_ 672 BtnID_D 1;
BA_ "U_CD764_MY2022_Rx" SG_ 672 BtnID_C 1;
BA_ "U_CD542_MY2021_Rx" SG_ 672 BtnID_C 1;
BA_ "U_U55X_MY2022_Rx" SG_ 672 BtnID_C 1;
BA_ "U_T6_MCA_MY2020_Rx" SG_ 672 BtnID_C 1;
BA_ "GenSigStartValue" SG_ 672 BtnID_C 255;
BA_ "GenSigStartValueInteger" SG_ 672 BtnID_C 255;
BA_ "WakeupSignal" SG_ 672 BtnID_C 1;
BA_ "U_CD764_MY2022_Rx" SG_ 672 BtnID_B 1;
BA_ "U_CD542_MY2021_Rx" SG_ 672 BtnID_B 1;
BA_ "U_U55X_MY2022_Rx" SG_ 672 BtnID_B 1;
BA_ "U_T6_MCA_MY2020_Rx" SG_ 672 BtnID_B 1;
BA_ "GenSigStartValue" SG_ 672 BtnID_B 255;
BA_ "GenSigStartValueInteger" SG_ 672 BtnID_B 255;
BA_ "WakeupSignal" SG_ 672 BtnID_B 1;
BA_ "U_CD764_MY2022_Rx" SG_ 672 BtnID_A 1;
BA_ "U_CD542_MY2021_Rx" SG_ 672 BtnID_A 1;
BA_ "U_U55X_MY2022_Rx" SG_ 672 BtnID_A 1;
BA_ "U_T6_MCA_MY2020_Rx" SG_ 672 BtnID_A 1;
BA_ "GenSigStartValue" SG_ 672 BtnID_A 255;
BA_ "GenSigStartValueInteger" SG_ 672 BtnID_A 255;
BA_ "WakeupSignal" SG_ 672 BtnID_A 1;
BA_ "GenSigSendType" SG_ 1952 TesterPhysicalReqFCIMB 3;
BA_ "GenSigSendType" SG_ 1960 TesterPhysicalResFCIMB 3;
BA_ "U_T6_MCA_MY2020_Rx" SG_ 1205 CstmDrvMdeCfg2_B_Avail 1;
BA_ "U_T6_MCA_MY2020_Rx" SG_ 1205 CstmDrvMdeCfg1_B_Avail 1;
BA_ "U_T6_MCA_MY2020_Rx" SG_ 1205 CstmDrvMde_No_Confg2 1;
BA_ "GenSigStartValue" SG_ 1205 CstmDrvMde_No_Confg2 63;
BA_ "U_T6_MCA_MY2020_Rx" SG_ 1205 CstmDrvMde_No_Confg1 1;
BA_ "GenSigStartValue" SG_ 1205 CstmDrvMde_No_Confg1 63;
BA_ "U_T6_MCA_MY2020_Rx" SG_ 1205 CstmDrvMde_No_Confg 1;
BA_ "U_T6_MCA_MY2020_Rx" SG_ 1205 CstmDrvMde5_No_Confg2 1;
BA_ "GenSigStartValue" SG_ 1205 CstmDrvMde5_No_Confg2 15;
BA_ "U_T6_MCA_MY2020_Rx" SG_ 1205 CstmDrvMde5_No_Confg1 1;
BA_ "GenSigStartValue" SG_ 1205 CstmDrvMde5_No_Confg1 15;
BA_ "U_T6_MCA_MY2020_Rx" SG_ 1205 CstmDrvMde4_No_Confg2 1;
BA_ "GenSigStartValue" SG_ 1205 CstmDrvMde4_No_Confg2 15;
BA_ "U_T6_MCA_MY2020_Rx" SG_ 1205 CstmDrvMde4_No_Confg1 1;
BA_ "GenSigStartValue" SG_ 1205 CstmDrvMde4_No_Confg1 15;
BA_ "U_T6_MCA_MY2020_Rx" SG_ 1205 CstmDrvMde3_No_Confg2 1;
BA_ "GenSigStartValue" SG_ 1205 CstmDrvMde3_No_Confg2 15;
BA_ "U_T6_MCA_MY2020_Rx" SG_ 1205 CstmDrvMde3_No_Confg1 1;
BA_ "GenSigStartValue" SG_ 1205 CstmDrvMde3_No_Confg1 15;
BA_ "U_T6_MCA_MY2020_Rx" SG_ 1205 CstmDrvMde2_No_Confg2 1;
BA_ "GenSigStartValue" SG_ 1205 CstmDrvMde2_No_Confg2 15;
BA_ "U_T6_MCA_MY2020_Rx" SG_ 1205 CstmDrvMde2_No_Confg1 1;
BA_ "GenSigStartValue" SG_ 1205 CstmDrvMde2_No_Confg1 15;
BA_ "U_T6_MCA_MY2020_Rx" SG_ 1205 CstmDrvMde1_No_Confg2 1;
BA_ "GenSigStartValue" SG_ 1205 CstmDrvMde1_No_Confg2 15;
BA_ "U_T6_MCA_MY2020_Rx" SG_ 1205 CstmDrvMde1_No_Confg1 1;
BA_ "GenSigStartValue" SG_ 1205 CstmDrvMde1_No_Confg1 15;
BA_ "U_CD764_MY2022_Rx" SG_ 1829 TesterPhysicalReqWCM 1;
BA_ "U_U55X_MY2022_Rx" SG_ 1829 TesterPhysicalReqWCM 1;
BA_ "U_CD542_MY2021_Rx" SG_ 1829 TesterPhysicalReqWCM 1;
BA_ "U_T6_MCA_MY2020_Rx" SG_ 1829 TesterPhysicalReqWCM 1;
BA_ "U_P702_MY2021_Rx" SG_ 1829 TesterPhysicalReqWCM 1;
BA_ "U_CX727_MY2021_Rx" SG_ 1829 TesterPhysicalReqWCM 1;
BA_ "GenSigSendType" SG_ 1829 TesterPhysicalReqWCM 3;
BA_ "U_CD764_MY2022_Tx" SG_ 601 ECG_MC_WORD_Rx 1;
BA_ "U_T6_MCA_MY2020_Tx" SG_ 601 ECG_MC_WORD_Rx 1;
BA_ "U_CD764_MY2022_Rx" SG_ 601 ECG_MC_WORD_Rx 1;
BA_ "U_U55X_MY2022_Rx" SG_ 601 ECG_MC_WORD_Rx 1;
BA_ "U_CD542_MY2021_Rx" SG_ 601 ECG_MC_WORD_Rx 1;
BA_ "ECGUsedRxSignal" SG_ 601 ECG_MC_WORD_Rx 1;
BA_ "U_T6_MCA_MY2020_Rx" SG_ 601 ECG_MC_WORD_Rx 1;
BA_ "U_CD764_MY2022_Tx" SG_ 593 ECG_MC_WORD_Tx 1;
BA_ "U_U55X_MY2022_Tx" SG_ 593 ECG_MC_WORD_Tx 1;
BA_ "U_CD542_MY2021_Tx" SG_ 593 ECG_MC_WORD_Tx 1;
BA_ "ECGUsedTxSignal" SG_ 593 ECG_MC_WORD_Tx 1;
BA_ "U_T6_MCA_MY2020_Tx" SG_ 593 ECG_MC_WORD_Tx 1;
BA_ "U_CD764_MY2022_Rx" SG_ 593 ECG_MC_WORD_Tx 1;
BA_ "U_CD542_MY2021_Rx" SG_ 593 ECG_MC_WORD_Tx 1;
BA_ "U_T6_MCA_MY2020_Rx" SG_ 593 ECG_MC_WORD_Tx 1;
BA_ "U_U55X_MY2022_Tx" SG_ 816 KeylessIdl_D_Rq 1;
BA_ "U_CD542_MY2021_Tx" SG_ 816 KeylessIdl_D_Rq 1;
BA_ "U_T6_MCA_MY2020_Tx" SG_ 816 KeylessIdl_D_Rq 1;
BA_ "GenSigSendType" SG_ 816 KeylessIdl_D_Rq 3;
BA_ "U_CD764_MY2022_Tx" SG_ 816 KeyPadCodeDgt7_D_Stat 1;
BA_ "U_U55X_MY2022_Tx" SG_ 816 KeyPadCodeDgt7_D_Stat 1;
BA_ "U_CD542_MY2021_Tx" SG_ 816 KeyPadCodeDgt7_D_Stat 1;
BA_ "U_T6_MCA_MY2020_Tx" SG_ 816 KeyPadCodeDgt7_D_Stat 1;
BA_ "GenSigSendType" SG_ 816 KeyPadCodeDgt7_D_Stat 3;
BA_ "WakeupSignal" SG_ 816 KeyPadCodeDgt7_D_Stat 1;
BA_ "U_CD764_MY2022_Tx" SG_ 816 KeyPadCodeDgt6_D_Stat 1;
BA_ "U_U55X_MY2022_Tx" SG_ 816 KeyPadCodeDgt6_D_Stat 1;
BA_ "U_CD542_MY2021_Tx" SG_ 816 KeyPadCodeDgt6_D_Stat 1;
BA_ "U_T6_MCA_MY2020_Tx" SG_ 816 KeyPadCodeDgt6_D_Stat 1;
BA_ "GenSigSendType" SG_ 816 KeyPadCodeDgt6_D_Stat 3;
BA_ "WakeupSignal" SG_ 816 KeyPadCodeDgt6_D_Stat 1;
BA_ "U_CD764_MY2022_Tx" SG_ 816 KeyPadCodeDgt5_D_Stat 1;
BA_ "U_U55X_MY2022_Tx" SG_ 816 KeyPadCodeDgt5_D_Stat 1;
BA_ "U_CD542_MY2021_Tx" SG_ 816 KeyPadCodeDgt5_D_Stat 1;
BA_ "U_T6_MCA_MY2020_Tx" SG_ 816 KeyPadCodeDgt5_D_Stat 1;
BA_ "GenSigSendType" SG_ 816 KeyPadCodeDgt5_D_Stat 3;
BA_ "WakeupSignal" SG_ 816 KeyPadCodeDgt5_D_Stat 1;
BA_ "U_CD764_MY2022_Tx" SG_ 816 KeyPadCodeDgt4_D_Stat 1;
BA_ "U_U55X_MY2022_Tx" SG_ 816 KeyPadCodeDgt4_D_Stat 1;
BA_ "U_CD542_MY2021_Tx" SG_ 816 KeyPadCodeDgt4_D_Stat 1;
BA_ "U_T6_MCA_MY2020_Tx" SG_ 816 KeyPadCodeDgt4_D_Stat 1;
BA_ "GenSigSendType" SG_ 816 KeyPadCodeDgt4_D_Stat 3;
BA_ "WakeupSignal" SG_ 816 KeyPadCodeDgt4_D_Stat 1;
BA_ "U_CD764_MY2022_Tx" SG_ 816 KeyPadCodeDgt3_D_Stat 1;
BA_ "U_U55X_MY2022_Tx" SG_ 816 KeyPadCodeDgt3_D_Stat 1;
BA_ "U_CD542_MY2021_Tx" SG_ 816 KeyPadCodeDgt3_D_Stat 1;
BA_ "U_T6_MCA_MY2020_Tx" SG_ 816 KeyPadCodeDgt3_D_Stat 1;
BA_ "GenSigSendType" SG_ 816 KeyPadCodeDgt3_D_Stat 3;
BA_ "WakeupSignal" SG_ 816 KeyPadCodeDgt3_D_Stat 1;
BA_ "U_CD764_MY2022_Tx" SG_ 816 KeyPadCodeDgt2_D_Stat 1;
BA_ "U_U55X_MY2022_Tx" SG_ 816 KeyPadCodeDgt2_D_Stat 1;
BA_ "U_CD542_MY2021_Tx" SG_ 816 KeyPadCodeDgt2_D_Stat 1;
BA_ "U_T6_MCA_MY2020_Tx" SG_ 816 KeyPadCodeDgt2_D_Stat 1;
BA_ "GenSigSendType" SG_ 816 KeyPadCodeDgt2_D_Stat 3;
BA_ "WakeupSignal" SG_ 816 KeyPadCodeDgt2_D_Stat 1;
BA_ "U_CD764_MY2022_Tx" SG_ 816 KeyPadCodeDgt1_D_Stat 1;
BA_ "U_U55X_MY2022_Tx" SG_ 816 KeyPadCodeDgt1_D_Stat 1;
BA_ "U_CD542_MY2021_Tx" SG_ 816 KeyPadCodeDgt1_D_Stat 1;
BA_ "U_T6_MCA_MY2020_Tx" SG_ 816 KeyPadCodeDgt1_D_Stat 1;
BA_ "GenSigSendType" SG_ 816 KeyPadCodeDgt1_D_Stat 3;
BA_ "WakeupSignal" SG_ 816 KeyPadCodeDgt1_D_Stat 1;
BA_ "U_CD764_MY2022_Tx" SG_ 816 CntrStk2_D_RqAssoc 1;
BA_ "U_U55X_MY2022_Tx" SG_ 816 CntrStk2_D_RqAssoc 1;
BA_ "U_CD542_MY2021_Tx" SG_ 816 CntrStk2_D_RqAssoc 1;
BA_ "U_T6_MCA_MY2020_Tx" SG_ 816 CntrStk2_D_RqAssoc 1;
BA_ "GenSigSendType" SG_ 816 CntrStk2_D_RqAssoc 3;
BA_ "GenSigStartValue" SG_ 816 CntrStk2_D_RqAssoc 3;
BA_ "GenSigStartValueInteger" SG_ 816 CntrStk2_D_RqAssoc 3;
BA_ "WakeupSignal" SG_ 816 CntrStk2_D_RqAssoc 1;
BA_ "U_T6_MCA_MY2020_Rx" SG_ 636 WifiHtsptFqBand_D_Stat 1;
BA_ "U_P702_MY2021_Rx" SG_ 636 WifiHtsptFqBand_D_Stat 1;
BA_ "U_CD764_MY2022_Rx" SG_ 636 WifiHtsptFqBand_D_Stat 1;
BA_ "U_CD542_MY2021_Rx" SG_ 636 WifiHtsptFqBand_D_Stat 1;
BA_ "U_T6_MCA_MY2020_Rx" SG_ 636 WifiHtspt_D_Falt 1;
BA_ "U_P702_MY2021_Rx" SG_ 636 WifiHtspt_D_Falt 1;
BA_ "U_CD764_MY2022_Rx" SG_ 636 WifiHtspt_D_Falt 1;
BA_ "U_CD542_MY2021_Rx" SG_ 636 WifiHtspt_D_Falt 1;
BA_ "U_U55X_MY2022_Rx" SG_ 636 WifiNoDevcCnnct_No_Actl 1;
BA_ "U_T6_MCA_MY2020_Rx" SG_ 636 WifiNoDevcCnnct_No_Actl 1;
BA_ "U_P702_MY2021_Rx" SG_ 636 WifiNoDevcCnnct_No_Actl 1;
BA_ "U_CD764_MY2022_Rx" SG_ 636 WifiNoDevcCnnct_No_Actl 1;
BA_ "U_CD542_MY2021_Rx" SG_ 636 WifiNoDevcCnnct_No_Actl 1;
BA_ "U_U55X_MY2022_Rx" SG_ 636 WifiHtsptCnnct_D_Stat 1;
BA_ "U_T6_MCA_MY2020_Rx" SG_ 636 WifiHtsptCnnct_D_Stat 1;
BA_ "U_P702_MY2021_Rx" SG_ 636 WifiHtsptCnnct_D_Stat 1;
BA_ "U_CD764_MY2022_Rx" SG_ 636 WifiHtsptCnnct_D_Stat 1;
BA_ "U_CD542_MY2021_Rx" SG_ 636 WifiHtsptCnnct_D_Stat 1;
BA_ "U_U55X_MY2022_Rx" SG_ 636 Telematics_D_Falt 1;
BA_ "U_T6_MCA_MY2020_Rx" SG_ 636 Telematics_D_Falt 1;
BA_ "U_P702_MY2021_Rx" SG_ 636 Telematics_D_Falt 1;
BA_ "U_CD764_MY2022_Rx" SG_ 636 Telematics_D_Falt 1;
BA_ "U_CD542_MY2021_Rx" SG_ 636 Telematics_D_Falt 1;
BA_ "U_U55X_MY2022_Rx" SG_ 636 WifiEnbl_D_Stat 1;
BA_ "U_T6_MCA_MY2020_Rx" SG_ 636 WifiEnbl_D_Stat 1;
BA_ "U_P702_MY2021_Rx" SG_ 636 WifiEnbl_D_Stat 1;
BA_ "U_CD764_MY2022_Rx" SG_ 636 WifiEnbl_D_Stat 1;
BA_ "U_CD542_MY2021_Rx" SG_ 636 WifiEnbl_D_Stat 1;
BA_ "U_U55X_MY2022_Rx" SG_ 636 WifiHtsptVisbl_D_Stat 1;
BA_ "U_T6_MCA_MY2020_Rx" SG_ 636 WifiHtsptVisbl_D_Stat 1;
BA_ "U_P702_MY2021_Rx" SG_ 636 WifiHtsptVisbl_D_Stat 1;
BA_ "U_CD764_MY2022_Rx" SG_ 636 WifiHtsptVisbl_D_Stat 1;
BA_ "U_CD542_MY2021_Rx" SG_ 636 WifiHtsptVisbl_D_Stat 1;
BA_ "U_U55X_MY2022_Rx" SG_ 636 WifiHtsptScrty_D_Stat 1;
BA_ "U_T6_MCA_MY2020_Rx" SG_ 636 WifiHtsptScrty_D_Stat 1;
BA_ "U_P702_MY2021_Rx" SG_ 636 WifiHtsptScrty_D_Stat 1;
BA_ "U_CD764_MY2022_Rx" SG_ 636 WifiHtsptScrty_D_Stat 1;
BA_ "U_CD542_MY2021_Rx" SG_ 636 WifiHtsptScrty_D_Stat 1;
BA_ "U_U55X_MY2022_Rx" SG_ 636 WifiHtsptEnbl_D_Stat 1;
BA_ "U_T6_MCA_MY2020_Rx" SG_ 636 WifiHtsptEnbl_D_Stat 1;
BA_ "U_P702_MY2021_Rx" SG_ 636 WifiHtsptEnbl_D_Stat 1;
BA_ "U_CD764_MY2022_Rx" SG_ 636 WifiHtsptEnbl_D_Stat 1;
BA_ "U_CD542_MY2021_Rx" SG_ 636 WifiHtsptEnbl_D_Stat 1;
BA_ "U_U55X_MY2022_Rx" SG_ 636 WifiDevcListNew_B_Stat 1;
BA_ "U_T6_MCA_MY2020_Rx" SG_ 636 WifiDevcListNew_B_Stat 1;
BA_ "U_P702_MY2021_Rx" SG_ 636 WifiDevcListNew_B_Stat 1;
BA_ "U_CD764_MY2022_Rx" SG_ 636 WifiDevcListNew_B_Stat 1;
BA_ "U_CD542_MY2021_Rx" SG_ 636 WifiDevcListNew_B_Stat 1;
BA_ "U_U55X_MY2022_Rx" SG_ 636 WifiDataUsage_Pc_Actl 1;
BA_ "U_T6_MCA_MY2020_Rx" SG_ 636 WifiDataUsage_Pc_Actl 1;
BA_ "U_P702_MY2021_Rx" SG_ 636 WifiDataUsage_Pc_Actl 1;
BA_ "U_CD764_MY2022_Rx" SG_ 636 WifiDataUsage_Pc_Actl 1;
BA_ "U_CD542_MY2021_Rx" SG_ 636 WifiDataUsage_Pc_Actl 1;
BA_ "U_U55X_MY2022_Rx" SG_ 636 WifiDataUsage_D_Stat 1;
BA_ "U_T6_MCA_MY2020_Rx" SG_ 636 WifiDataUsage_D_Stat 1;
BA_ "U_P702_MY2021_Rx" SG_ 636 WifiDataUsage_D_Stat 1;
BA_ "U_CD764_MY2022_Rx" SG_ 636 WifiDataUsage_D_Stat 1;
BA_ "U_CD542_MY2021_Rx" SG_ 636 WifiDataUsage_D_Stat 1;
BA_ "U_T6_MCA_MY2020_Rx" SG_ 636 ModemSigStren_D_Stat 1;
BA_ "U_P702_MY2021_Rx" SG_ 636 ModemSigStren_D_Stat 1;
BA_ "U_CD764_MY2022_Rx" SG_ 636 ModemSigStren_D_Stat 1;
BA_ "U_CD542_MY2021_Rx" SG_ 636 ModemSigStren_D_Stat 1;
BA_ "GenSigStartValue" SG_ 636 ModemSigStren_D_Stat 6;
BA_ "GenSigStartValueInteger" SG_ 636 ModemSigStren_D_Stat 6;
BA_ "U_P702_MY2021_Rx" SG_ 636 ModemTechnology_D2_Stat 1;
BA_ "U_U55X_MY2022_Rx" SG_ 636 ModemTechnology_D2_Stat 1;
BA_ "U_T6_MCA_MY2020_Rx" SG_ 636 ModemTechnology_D2_Stat 1;
BA_ "U_CD764_MY2022_Rx" SG_ 636 ModemTechnology_D2_Stat 1;
BA_ "U_CD542_MY2021_Rx" SG_ 636 ModemTechnology_D2_Stat 1;
BA_ "U_U55X_MY2022_Rx" SG_ 636 WifiHtsptCrdntl_B_Stat 1;
BA_ "U_T6_MCA_MY2020_Rx" SG_ 636 WifiHtsptCrdntl_B_Stat 1;
BA_ "U_CD764_MY2022_Rx" SG_ 636 WifiHtsptCrdntl_B_Stat 1;
BA_ "U_CD542_MY2021_Rx" SG_ 636 WifiHtsptCrdntl_B_Stat 1;
BA_ "U_T6_MCA_MY2020_Rx" SG_ 636 WifiHtsptFq_D_Avail 1;
BA_ "U_P702_MY2021_Rx" SG_ 636 WifiHtsptFq_D_Avail 1;
BA_ "U_CD764_MY2022_Rx" SG_ 636 WifiHtsptFq_D_Avail 1;
BA_ "U_CD542_MY2021_Rx" SG_ 636 WifiHtsptFq_D_Avail 1;
BA_ "U_U55X_MY2022_Rx" SG_ 636 WifiDataUsageOn_D_Stat 1;
BA_ "U_T6_MCA_MY2020_Rx" SG_ 636 WifiDataUsageOn_D_Stat 1;
BA_ "U_P702_MY2021_Rx" SG_ 636 WifiDataUsageOn_D_Stat 1;
BA_ "U_CD764_MY2022_Rx" SG_ 636 WifiDataUsageOn_D_Stat 1;
BA_ "U_CD542_MY2021_Rx" SG_ 636 WifiDataUsageOn_D_Stat 1;
BA_ "U_CD764_MY2022_Tx" SG_ 807 ElDistTripUnit_D_Stat 1;
BA_ "U_U55X_MY2022_Tx" SG_ 807 ElDistTripUnit_D_Stat 1;
BA_ "U_CD542_MY2021_Tx" SG_ 807 ElDistTripUnit_D_Stat 1;
BA_ "U_T6_MCA_MY2020_Tx" SG_ 807 ElDistTripUnit_D_Stat 1;
BA_ "U_U55X_MY2022_Rx" SG_ 807 ElDistTripUnit_D_Stat 1;
BA_ "U_CD542_MY2021_Rx" SG_ 807 ElDistTripUnit_D_Stat 1;
BA_ "U_T6_MCA_MY2020_Rx" SG_ 807 ElDistTripUnit_D_Stat 1;
BA_ "GenSigSendType" SG_ 807 ElDistTripUnit_D_Stat 3;
BA_ "U_CD764_MY2022_Tx" SG_ 807 ElDistTrip2_No_Dsply 1;
BA_ "U_U55X_MY2022_Tx" SG_ 807 ElDistTrip2_No_Dsply 1;
BA_ "U_CD542_MY2021_Tx" SG_ 807 ElDistTrip2_No_Dsply 1;
BA_ "U_T6_MCA_MY2020_Tx" SG_ 807 ElDistTrip2_No_Dsply 1;
BA_ "U_U55X_MY2022_Rx" SG_ 807 ElDistTrip2_No_Dsply 1;
BA_ "U_CD542_MY2021_Rx" SG_ 807 ElDistTrip2_No_Dsply 1;
BA_ "U_T6_MCA_MY2020_Rx" SG_ 807 ElDistTrip2_No_Dsply 1;
BA_ "GenSigSendType" SG_ 807 ElDistTrip2_No_Dsply 3;
BA_ "U_CD764_MY2022_Tx" SG_ 807 ElDistTrip1_No_Dsply 1;
BA_ "U_U55X_MY2022_Tx" SG_ 807 ElDistTrip1_No_Dsply 1;
BA_ "U_CD542_MY2021_Tx" SG_ 807 ElDistTrip1_No_Dsply 1;
BA_ "U_T6_MCA_MY2020_Tx" SG_ 807 ElDistTrip1_No_Dsply 1;
BA_ "U_U55X_MY2022_Rx" SG_ 807 ElDistTrip1_No_Dsply 1;
BA_ "U_CD542_MY2021_Rx" SG_ 807 ElDistTrip1_No_Dsply 1;
BA_ "U_T6_MCA_MY2020_Rx" SG_ 807 ElDistTrip1_No_Dsply 1;
BA_ "GenSigSendType" SG_ 807 ElDistTrip1_No_Dsply 3;
BA_ "U_CD764_MY2022_Tx" SG_ 807 ElDistTripCur_No_Dsply 1;
BA_ "U_U55X_MY2022_Tx" SG_ 807 ElDistTripCur_No_Dsply 1;
BA_ "U_CD542_MY2021_Tx" SG_ 807 ElDistTripCur_No_Dsply 1;
BA_ "U_U55X_MY2022_Rx" SG_ 807 ElDistTripCur_No_Dsply 1;
BA_ "U_CD542_MY2021_Rx" SG_ 807 ElDistTripCur_No_Dsply 1;
BA_ "GenSigSendType" SG_ 807 ElDistTripCur_No_Dsply 3;
BA_ "U_CD764_MY2022_Rx" SG_ 974 EngExhMdeHrStrt_D_Stat 1;
BA_ "U_U55X_MY2022_Rx" SG_ 974 EngExhMdeHrStrt_D_Stat 1;
BA_ "U_CD764_MY2022_Rx" SG_ 974 EngExhMdeHrEnd_D_Stat 1;
BA_ "U_U55X_MY2022_Rx" SG_ 974 EngExhMdeHrEnd_D_Stat 1;
BA_ "U_CD764_MY2022_Rx" SG_ 974 EngExhMdeHrEnbl_D_Stat 1;
BA_ "U_U55X_MY2022_Rx" SG_ 974 EngExhMdeHrEnbl_D_Stat 1;
BA_ "U_CD764_MY2022_Rx" SG_ 974 DcacOut_Pw_DsplyMx 1;
BA_ "U_U55X_MY2022_Rx" SG_ 974 DcacOut_Pw_DsplyMx 1;
BA_ "U_CD542_MY2021_Rx" SG_ 974 DcacOut_Pw_DsplyMx 1;
BA_ "U_U55X_MY2022_Rx" SG_ 974 DcacOut1_Pw_Dsply 1;
BA_ "U_CD542_MY2021_Rx" SG_ 974 DcacOut1_Pw_Dsply 1;
BA_ "U_U55X_MY2022_Rx" SG_ 974 DcacOut2_Pw_Dsply 1;
BA_ "U_CD542_MY2021_Rx" SG_ 974 DcacOut2_Pw_Dsply 1;
BA_ "U_U55X_MY2022_Rx" SG_ 974 DcacHw_D_Confg 1;
BA_ "U_CD542_MY2021_Rx" SG_ 974 DcacHw_D_Confg 1;
BA_ "GenSigStartValueInteger" SG_ 974 DcacHw_D_Confg 1;
BA_ "U_U55X_MY2022_Rx" SG_ 974 DcacFaltMsgTxt_D_Rq 1;
BA_ "U_CD542_MY2021_Rx" SG_ 974 DcacFaltMsgTxt_D_Rq 1;
BA_ "GenSigStartValueInteger" SG_ 974 DcacFaltMsgTxt_D_Rq 1;
BA_ "U_U55X_MY2022_Rx" SG_ 974 DcacLoFuelMsgTxt_D_Rq 1;
BA_ "U_CD542_MY2021_Rx" SG_ 974 DcacLoFuelMsgTxt_D_Rq 1;
BA_ "U_U55X_MY2022_Rx" SG_ 974 DcacEngOnMsgTxt_D_Rq 1;
BA_ "U_CD542_MY2021_Rx" SG_ 974 DcacEngOnMsgTxt_D_Rq 1;
BA_ "U_U55X_MY2022_Rx" SG_ 974 DcacElPw_D_Stat 1;
BA_ "U_CD542_MY2021_Rx" SG_ 974 DcacElPw_D_Stat 1;
BA_ "GenSigStartValue" SG_ 974 DcacElPw_D_Stat 1;
BA_ "GenSigStartValueInteger" SG_ 974 DcacElPw_D_Stat 1;
BA_ "U_CD764_MY2022_Tx" SG_ 805 InstFeTripUnit_D_Stat 1;
BA_ "U_U55X_MY2022_Tx" SG_ 805 InstFeTripUnit_D_Stat 1;
BA_ "U_CD542_MY2021_Tx" SG_ 805 InstFeTripUnit_D_Stat 1;
BA_ "U_T6_MCA_MY2020_Tx" SG_ 805 InstFeTripUnit_D_Stat 1;
BA_ "U_CD542_MY2021_Rx" SG_ 805 InstFeTripUnit_D_Stat 1;
BA_ "U_U55X_MY2022_Rx" SG_ 805 InstFeTripUnit_D_Stat 1;
BA_ "U_T6_MCA_MY2020_Rx" SG_ 805 InstFeTripUnit_D_Stat 1;
BA_ "U_CD764_MY2022_Tx" SG_ 805 InstFe_No_Dsply 1;
BA_ "U_U55X_MY2022_Tx" SG_ 805 InstFe_No_Dsply 1;
BA_ "U_CD542_MY2021_Tx" SG_ 805 InstFe_No_Dsply 1;
BA_ "U_T6_MCA_MY2020_Tx" SG_ 805 InstFe_No_Dsply 1;
BA_ "U_CD542_MY2021_Rx" SG_ 805 InstFe_No_Dsply 1;
BA_ "U_U55X_MY2022_Rx" SG_ 805 InstFe_No_Dsply 1;
BA_ "U_T6_MCA_MY2020_Rx" SG_ 805 InstFe_No_Dsply 1;
VAL_ 1012 ChrgLocSaved_B_Dsply 1 "Yes" 0 "No" ;
VAL_ 1012 ChrgLocLongPostv_B_Sav 1 "Yes" 0 "No" ;
VAL_ 1012 ChrgLocLattPostv_B_Sav 1 "Yes" 0 "No" ;
VAL_ 1012 AirCondRec_B_RqVehEl 1 "Yes" 0 "No" ;
VAL_ 1012 ChrgNowCurnt_B_Dsply 1 "On" 0 "Off" ;
VAL_ 1011 ChrgLocLongPostv_B_Uns 1 "Yes" 0 "No" ;
VAL_ 1011 ChrgLocLattPostv_B_Uns 1 "Yes" 0 "No" ;
VAL_ 1011 VehShutDownMsgTxt_D_Rq 3 "NotUsed" 2 "ProhibitedRestart" 1 "ShutdownWarning" 0 "NoMessage" ;
VAL_ 533 AutoEpbZoomView_B_Stat 1 "Active" 0 "Inactive" ;
VAL_ 533 ClrExitAsstEnbl_D_RqMnu 3 "NotUsed" 0 "Inactive" 2 "Enable" 1 "Disable" ;
VAL_ 533 PaakMyKey_D_Rq 3 "NotUsed" 2 "ConfirmNewPaakMyKey" 1 "RequestNewPaakMyKey" 0 "None" ;
VAL_ 533 AutoEpbButtn_B_Stat 1 "Pressed" 0 "Not_Pressed" ;
VAL_ 533 TrlrAidMde_D_Rq 3 "Mode_3" 2 "Mode_2" 1 "Mode_1" 0 "NoRequest" ;
VAL_ 533 TCU_Init_Actvtn_St 3 "NotUsed" 2 "InitialActivateDeny" 1 "InitialActivateAccept" 0 "Invalid" ;
VAL_ 533 TCU_Final_Actvtn_St 3 "NotUsed" 2 "FinalActivateDeny" 1 "FinalActivateAccept" 0 "Invalid" ;
VAL_ 533 DcacPw_D_Rq 3 "High" 2 "Low" 1 "Off" 0 "Null" ;
VAL_ 533 DcacPwReset_B_Rq 1 "Reset" 0 "Null" ;
VAL_ 533 LghtAmbDrvMde_D_Rq 3 "NotUsed" 2 "Automatic" 1 "Manual" 0 "Null" ;
VAL_ 533 OtaTrg_D_Stat 3 "NotUsed_1" 2 "Accepted" 1 "NotAccepted" 0 "Null" ;
VAL_ 533 DcacPwLoButtn_B_Stat 1 "Pressed" 0 "Not_Pressed" ;
VAL_ 533 DcacPwOffButtn_B_Stat 1 "Pressed" 0 "Not_Pressed" ;
VAL_ 533 DcacPwHiButtn_B_Stat 1 "Pressed" 0 "Not_Pressed" ;
VAL_ 533 DcacPwResetButtn_B_Stat 1 "Pressed" 0 "Not_Pressed" ;
VAL_ 533 DcacPwButtn_B_Falt 1 "Faulted" 0 "NotFaulted" ;
VAL_ 533 OnbChrgGoTTouch_D_Rq 3 "NotUsed" 2 "On" 1 "Off" 0 "Null" ;
VAL_ 533 OnbChrgGoTPrcond_D_Rq 3 "High" 2 "Medium" 1 "Low" 0 "Off" ;
VAL_ 533 OnbChrgGoTOn_D_Rq 3 "NotUsed" 2 "On" 1 "Off" 0 "Null" ;
VAL_ 533 OnbChrgGoTMnte_D_Rq 15 "NotUsed_4" 14 "NotUsed_3" 13 "NotUsed_2" 12 "NotUsed_1" 11 "Minute_55" 10 "Minute_50" 9 "Minute_45" 8 "Minute_40" 7 "Minute_35" 6 "Minute_30" 5 "Minute_25" 4 "Minute_20" 3 "Minute_15" 2 "Minute_10" 1 "Minute_5" 0 "Minute_0" ;
VAL_ 533 OnbChrgGoTHr_T_Rq 31 "Faulty" 30 "NoDataExists" ;
VAL_ 533 OnbChrgGoTExtHtr_D_Rq 3 "NotUsed" 2 "On" 1 "Off" 0 "Null" ;
VAL_ 533 OnbChrgGoTDelete_B_Rq 1 "Request" 0 "NoRequest" ;
VAL_ 533 OnbChrgClearAll_B_Rq 1 "Request" 0 "NoRequest" ;
VAL_ 533 OnbChrgGoTUpdate_B_Rq 1 "Request" 0 "NoRequest" ;
VAL_ 533 TrlrAlarmButtn_B_Stat 1 "On" 0 "Off" ;
VAL_ 533 DcacMdeButtn_B_Stat 1 "Pressed" 0 "Not_Pressed" ;
VAL_ 533 DcacGfciTestBttn_B_Stat 1 "Pressed" 0 "Not_Pressed" ;
VAL_ 533 TrlrHitch_D_RqMnu 15 "NotUsed_10" 14 "NotUsed_9" 13 "NotUsed_8" 12 "NotUsed_7" 11 "NotUsed_6" 10 "NotUsed_5" 9 "NotUsed_4" 8 "NotUsed_3" 7 "NotUsed_2" 6 "NotUsed_1" 5 "GoToTraileringDomain" 4 "Confirm" 3 "TurnOnTba" 2 "TurnOnAutohitch" 1 "CancelAutohitch" 0 "NoRequest" ;
VAL_ 533 DcacPwButtn_B_Stat 1 "Pressed" 0 "Not_Pressed" ;
VAL_ 801 CDWarnChime_St 1 "On" 0 "Off" ;
VAL_ 801 SoftWarning 1 "Chime_On" 0 "Chime_Off" ;
VAL_ 801 HardWarning 1 "Chime_On" 0 "Chime_Off" ;
VAL_ 801 InfoWarning 1 "Chime_On" 0 "Chime_Off" ;
VAL_ 801 DrvDsplyPalette_D_Stat 7 "NotUsed_3" 6 "NotUsed_2" 5 "ManualNightDark" 4 "ManualNightBright" 3 "ManualDay" 2 "AutoNight" 1 "AutoDay" 0 "Null" ;
VAL_ 878 ClimtSyncRear2_B_Stat 1 "Pressed" 0 "Not_Pressed" ;
VAL_ 878 ClimtStHeatRr2_B_Stat 1 "Pressed" 0 "Not_Pressed" ;
VAL_ 878 ClimtStHeatRl2_B_Stat 1 "Pressed" 0 "Not_Pressed" ;
VAL_ 878 ClimtStCoolRr2_B_Stat 1 "Pressed" 0 "Not_Pressed" ;
VAL_ 878 ClimtStCoolRl2_B_Stat 1 "Pressed" 0 "Not_Pressed" ;
VAL_ 878 ClimtSeatRr2_D_Rq 128 "H3_High_Heat_MAX" 64 "H2_Medium_Heat" 32 "H1_Low_Heat" 16 "C3_High_Cool_MAX" 8 "C2_Medium_Cool" 4 "C1_Low_Cool" 2 "Off" ;
VAL_ 878 ClimtSeatRl2_D_Rq 128 "H3_High_Heat_MAX" 64 "H2_Medium_Heat" 32 "H1_Low_Heat" 16 "C3_High_Cool_MAX" 8 "C2_Medium_Cool" 4 "C1_Low_Cool" 2 "Off" ;
VAL_ 878 ClimtRrTe3rd2_D_Stat 3 "NotUsed" 2 "Decrement" 1 "Increment" 0 "Inactive" ;
VAL_ 878 ClimtRrPw3rd2_B_Stat 1 "Pressed" 0 "Not_Pressed" ;
VAL_ 878 ClimtRrPnl3rd2_B_Stat 1 "Pressed" 0 "Not_Pressed" ;
VAL_ 878 ClimtRrPf3rd2_B_Stat 1 "Pressed" 0 "Not_Pressed" ;
VAL_ 878 ClimtRrFlr3rd2_B_Stat 1 "Pressed" 0 "Not_Pressed" ;
VAL_ 878 ClimtRrBlwr3rd2_D_Stat 3 "NotUsed" 2 "Decrement" 1 "Increment" 0 "Inactive" ;
VAL_ 878 ClimtRrAuto3rd2_B_Stat 1 "Pressed" 0 "Not_Pressed" ;
VAL_ 878 ClimtRearView2_D_Stat 3 "ThirdRow" 2 "SecondRow" 1 "Both" 0 "NotDisplayed" ;
VAL_ 878 ClimtRearTe2_D_Stat 3 "NotUsed" 2 "Decrement" 1 "Increment" 0 "Inactive" ;
VAL_ 878 ClimtRearTe2_An_Actl 511 "Faulty" ;
VAL_ 878 ClimtRearPw2_B_Stat 1 "Pressed" 0 "Not_Pressed" ;
VAL_ 878 ClimtRearPnlFlr2_B_Stat 1 "Pressed" 0 "Not_Pressed" ;
VAL_ 878 ClimtRearPnl2_B_Stat 1 "Pressed" 0 "Not_Pressed" ;
VAL_ 878 ClimtRearFlr2_B_Stat 1 "Pressed" 0 "Not_Pressed" ;
VAL_ 878 ClimtRearBlwr2_D_Stat 3 "NotUsed" 2 "Decrement" 1 "Increment" 0 "Inactive" ;
VAL_ 878 ClimtRearBlwr2_An_Actl 511 "Faulty" ;
VAL_ 878 ClimtRearAuto2_B_Stat 1 "Pressed" 0 "Not_Pressed" ;
VAL_ 258 GPS_Track_D_Rq 3 "NotUsed_1" 2 "NewGPSTrack" 1 "GPSTrackActive" 0 "Inactive" ;
VAL_ 258 APIM_SwPartNo_D_Rq 3 "NotUsed" 2 "Request" 1 "NoRequest" 0 "Inactive" ;
VAL_ 258 TCU_Init_Actvtn_Rq 3 "NotUsed" 2 "InitialActivateRequest" 1 "NoRequest" 0 "Inactive" ;
VAL_ 258 TCU_Final_Actvtn_Rq 3 "NotUsed" 2 "FinalActiveRequested" 1 "NoRequest" 0 "Inactive" ;
VAL_ 1247 TrlrBrkCtl3_B_Falt 1 "True" 0 "False" ;
VAL_ 1247 StopLamp_B_RqTrlrAft 1 "True" 0 "False" ;
VAL_ 413 LBS1_ListStatus 0 "Inactive" 1 "Valid" 2 "Updating" 3 "Reserved" ;
VAL_ 556 DrvAsstMnuButtn_B_Stat 1 "Pressed" 0 "Not_Pressed" ;
VAL_ 556 Manual_Temp_Setting 31 "Full_Heat" 30 "Setting_30" 29 "Setting_29" 28 "Setting_28" 27 "Setting_27" 26 "Setting_26" 25 "Setting_25" 24 "Setting_24" 23 "Setting_23" 22 "Setting_22" 21 "Setting_21" 20 "Setting_20" 19 "Setting_19" 18 "Setting_18" 17 "Setting_17" 16 "Setting_16" 15 "Setting_15" 14 "Setting_14" 13 "Setting_13" 12 "Setting_12" 11 "Setting_11" 10 "Setting_10" 9 "Setting_9" 8 "Setting_8" 7 "Setting_7" 6 "Setting_6" 5 "Setting_5" 4 "Setting_4" 3 "Setting_3" 2 "Setting_2" 1 "Full_Cool" 0 "Off" ;
VAL_ 556 EFP_Bezel_Diag_St 15 "Reserved" 3 "CalibrationPartNumber" 2 "HardwarePartNumber" 1 "SoftwarePartNumber" 0 "Inactive_NOP" ;
VAL_ 556 Bezel_Beep_St 0 "Invalid" 2 "Disabled" 1 "Enabled" ;
VAL_ 556 Bezel_Beeps_Supported 2 "Not_Supported" 1 "Supported" 0 "Invalid" ;
VAL_ 556 PassRstrnInd_Stat 7 "Invalid" 6 "Unused_2" 5 "Unused_1" 4 "Both_Indicators_Faulted" 3 "AirbagOff_Indicator_fault" 2 "AirbagOn_Indicator_fault" 1 "Normal" 0 "Not_Supported" ;
VAL_ 259 SDARS_ChipControl_Rq 7 "NotUsed_4" 6 "NotUsed_3" 5 "NotUsed_2" 4 "NotUsed_1" 3 "Reset" 2 "PowerDown" 1 "PowerUp" 0 "Inactive" ;
VAL_ 259 SDARS_AlertStatus_Rq 2 "Disable" 1 "Enable" 0 "Inactive" ;
VAL_ 538 MK_SpeedMinderConf_St 31 "mph90" 30 "mph85" 29 "mph80" 28 "mph75" 27 "mph70" 26 "mph65" 25 "mph60" 24 "mph55" 23 "mph50" 22 "mph45" 21 "mph40" 20 "Kmh165" 19 "Kmh160" 18 "Kmh155" 17 "Kmh150" 16 "Kmh145" 15 "Kmh140" 14 "Kmh135" 13 "Kmh130" 12 "Kmh125" 11 "Kmh120" 10 "Kmh115" 9 "Kmh110" 8 "Kmh105" 7 "Kmh100" 6 "kmh95" 5 "kmh90" 4 "kmh85" 3 "kmh80" 2 "kmh75" 1 "kmh70" 0 "Off" ;
VAL_ 538 MK_SpeedLimitConf_St 31 "mph90" 30 "mph85" 29 "mph80" 28 "mph75" 27 "mph70" 26 "mph65" 25 "mph60" 24 "mph55" 23 "mph50" 22 "mph45" 21 "mph40" 20 "Kmh165" 19 "Kmh160" 18 "Kmh155" 17 "Kmh150" 16 "Kmh145" 15 "Kmh140" 14 "Kmh135" 13 "Kmh130" 12 "Kmh125" 11 "Kmh120" 10 "Kmh115" 9 "Kmh110" 8 "Kmh105" 7 "Kmh100" 6 "kmh95" 5 "kmh90" 4 "kmh85" 3 "kmh80" 2 "kmh75" 1 "kmh70" 0 "Off" ;
VAL_ 538 MK_ESCRestrictConf_St 3 "NotUsed" 2 "On" 1 "Off" 0 "Null" ;
VAL_ 538 MK_ECalRestrictConf_St 3 "NotUsed" 2 "On" 1 "Off" 0 "Null" ;
VAL_ 538 MK_DNDRestrictConf_St 3 "NotUsed" 2 "On" 1 "Off" 0 "Null" ;
VAL_ 538 MK_AudioLimitConfig_St 3 "NotUsed" 2 "On" 1 "Off" 0 "Null" ;
VAL_ 422 MK_UserMyKeyCount_Rsp 15 "Inactive" 14 "Unlimited" 13 "Thirteen" 12 "Twelve" 11 "Eleven" 10 "Ten" 9 "Nine" 8 "Eight" 7 "Seven" 6 "Six" 5 "Five" 4 "Four" 3 "Three" 2 "Two" 1 "One" 0 "Zero" ;
VAL_ 422 MK_CreateMyKey_Rsp 7 "NotUsed_3" 6 "NotUsed_2" 5 "NotUsed_1" 4 "Success" 3 "GenericFailure" 2 "NoKeyInSlot" 1 "KeyInSlotAlreadyMyKey" 0 "Inactive" ;
VAL_ 422 MK_AdminMyKeyCount_Rsp 15 "Inactive" 14 "Unlimited" 13 "Thirteen" 12 "Twelve" 11 "Eleven" 10 "Ten" 9 "Nine" 8 "Eight" 7 "Seven" 6 "Six" 5 "Five" 4 "Four" 3 "Three" 2 "Two" 1 "One" 0 "Zero" ;
VAL_ 1020 CtrStkPersIndex2_D_Actl 7 "Unused_3" 6 "Unused_2" 5 "Unused_1" 4 "Vehicle" 3 "PERS_4" 2 "PERS_3" 1 "PERS_2" 0 "PERS_1" ;
VAL_ 1020 CtrStkDsplyOp2_D_Rq 7 "Unused_2" 6 "Unused_1" 5 "Copy" 4 "Restore" 3 "Upload" 2 "Set" 1 "Query" 0 "Null" ;
VAL_ 1007 PersIndexIpc2_D_Actl 7 "Unused_3" 6 "Unused_2" 5 "Unused_1" 4 "Vehicle" 3 "PERS_4" 2 "PERS_3" 1 "PERS_2" 0 "PERS_1" ;
VAL_ 884 UltraFreshCabn_D_Stat 7 "NotUsed_2" 6 "NotUsed_1" 5 "NotSupported" 4 "Interrupted" 3 "Complete" 2 "Active" 1 "Inactive" 0 "Null" ;
VAL_ 884 PmSnsCabn_D_Stat 7 "NotUsed_1" 6 "IntermittentInhibit" 5 "NoIssue" 4 "BlankField" 3 "ReplaceSensor" 2 "CleanSensor" 1 "Unsupported" 0 "Initializing" ;
VAL_ 884 PmCabn_Conc_Actl 511 "Faulty" 510 "NoDataExists" ;
VAL_ 884 PmCabn20Mnte_Conc_Actl 511 "Faulty" 510 "NoDataExists" ;
VAL_ 884 PmCabn18Mnte_Conc_Actl 511 "Faulty" 510 "NoDataExists" ;
VAL_ 884 PmCabn16Mnte_Conc_Actl 511 "Faulty" 510 "NoDataExists" ;
VAL_ 884 PmCabn14Mnte_Conc_Actl 511 "Faulty" 510 "NoDataExists" ;
VAL_ 884 PmCabn12Mnte_Conc_Actl 511 "Faulty" 510 "NoDataExists" ;
VAL_ 883 PmCabn10Mnte_Conc_Actl 511 "Faulty" 510 "NoDataExists" ;
VAL_ 883 PmCabn08Mnte_Conc_Actl 511 "Faulty" 510 "NoDataExists" ;
VAL_ 883 PmCabn06Mnte_Conc_Actl 511 "Faulty" 510 "NoDataExists" ;
VAL_ 883 PmCabn04Mnte_Conc_Actl 511 "Faulty" 510 "NoDataExists" ;
VAL_ 883 PmCabn02Mnte_Conc_Actl 511 "Faulty" 510 "NoDataExists" ;
VAL_ 1090 VehElRnge_L_Dsply 4094 "NoDataExists" 4095 "Fault" ;
VAL_ 1090 Mtr2State_D_ActlMntr 7 "Faulty" 6 "NoDataExists" 5 "NotUsed_1" 4 "ReadinessState" 3 "DeactivationState" 2 "PowerGeneration" 1 "PowerConsumption" 0 "Null" ;
VAL_ 1090 Inv1Ain_I_ActlMntr 32767 "Faulty" 32766 "NoDataExists" ;
VAL_ 1090 HybVehMde_D_ActlMntr 7 "Faulty" 6 "NoDataExists" 5 "NotUsed_2" 4 "NotUsed_1" 3 "Fuel" 2 "HybridElectric" 1 "AllElectric" 0 "Null" ;
VAL_ 1090 ChrgStat_D_ActlMntr 7 "Faulty" 6 "NoDataExists" 5 "NotUsed" 4 "ChargingCompleted" 3 "NotCharging" 2 "ChargingInDrivingState" 1 "ChargingInParkingState" 0 "Null" ;
VAL_ 677 SeatFnPsgr_D_Rq3 7 "CushionMassage" 6 "LumbarMassage" 5 "UpperBolster" 4 "LowerBolster" 3 "UpperLumbar" 2 "MiddleLumbar" 1 "LowerLumbar" 0 "Null" ;
VAL_ 677 SeatFnDrv_D_Rq3 7 "CushionMassage" 6 "LumbarMassage" 5 "UpperBolster" 4 "LowerBolster" 3 "UpperLumbar" 2 "MiddleLumbar" 1 "LowerLumbar" 0 "Null" ;
VAL_ 677 SeatMasgPsngrRr_D_Rq2 15 "NotUsed_10" 14 "NotUsed_9" 13 "NotUsed_8" 12 "NotUsed_7" 11 "NotUsed_6" 10 "Pattern10" 9 "Pattern9" 8 "Pattern8" 7 "Pattern7" 6 "Pattern6" 5 "Pattern5" 4 "Pattern4" 3 "Pattern3" 2 "Pattern2" 1 "Pattern1" 0 "Null" ;
VAL_ 677 SeatMasgDrvRr_D_Rq2 15 "NotUsed_10" 14 "NotUsed_9" 13 "NotUsed_8" 12 "NotUsed_7" 11 "NotUsed_6" 10 "Pattern10" 9 "Pattern9" 8 "Pattern8" 7 "Pattern7" 6 "Pattern6" 5 "Pattern5" 4 "Pattern4" 3 "Pattern3" 2 "Pattern2" 1 "Pattern1" 0 "Null" ;
VAL_ 677 SeatFnChngPsgr2_D_Rq3 15 "Faulty" 14 "NotUsed9" 13 "NotUsed8" 12 "NotUsed7" 11 "NotUsed6" 10 "High_2" 9 "Med_2" 8 "Low_2" 7 "Off_2" 6 "High" 5 "Low" 4 "Off" 3 "Decrease" 2 "Increase" 1 "NotUsed1" 0 "Inactive" ;
VAL_ 677 SeatFnChngDrv2_D_Rq3 15 "Faulty" 14 "NotUsed9" 13 "NotUsed8" 12 "NotUsed7" 11 "NotUsed6" 10 "High_2" 9 "Med_2" 8 "Low_2" 7 "Off_2" 6 "High" 5 "Low" 4 "Off" 3 "Decrease" 2 "Increase" 1 "NotUsed1" 0 "Inactive" ;
VAL_ 1238 TjaLaneBiasEnbl_D_Stat 3 "NotUsed" 0 "Inactive" 2 "Enable" 1 "Disable" ;
VAL_ 1238 TjaLaneBias_D_Stat 7 "NotUsed" 6 "ElBiasRight" 5 "ElBiasLeft" 4 "SystemBiasRight" 3 "SystemBiasLeft" 2 "ManualBiasRight" 1 "ManualBiasLeft" 0 "NoBias" ;
VAL_ 1238 IaccVAdjReas_D_Dsply 15 "NotUsed_21" 11 "NotUsed_1" 10 "SpeedSign" 9 "LeftRamp" 8 "RightRamp" 7 "Roundabout_CCW" 6 "Roundabout_CW" 5 "LeftCurve" 4 "RightCurve" 3 "LeftTurnIntersection" 2 "RightTurnIntersection" 1 "RoadGeometryUnavailable" 0 "NoDisplay" ;
VAL_ 1041 ElCmprPerfErr_D_Falt 3 "NotUsed" 2 "Pass" 1 "Fail" 0 "Not_Diagnose_Yet" ;
VAL_ 1041 ElCmprInnrErr_D_Falt 3 "NotUsed" 2 "Pass" 1 "Fail" 0 "Not_Diagnose_Yet" ;
VAL_ 1041 ElCmprLostComm_D_Falt 3 "NotUsed" 2 "Pass" 1 "Fail" 0 "Not_Diagnose_Yet" ;
VAL_ 1041 ElCmprOverLoad_D_Falt 3 "NotUsed" 2 "Pass" 1 "Fail" 0 "Not_Diagnose_Yet" ;
VAL_ 1041 ElCmprOverTe_D_Falt 3 "NotUsed" 2 "Pass" 1 "Fail" 0 "Not_Diagnose_Yet" ;
VAL_ 1041 ElCmprBattURng_D_Falt 3 "NotUsed" 2 "Pass" 1 "Fail" 0 "Not_Diagnose_Yet" ;
VAL_ 1041 ElCmprBattSysU_D_Falt 3 "NotUsed" 2 "Pass" 1 "Fail" 0 "Not_Diagnose_Yet" ;
VAL_ 1041 ElCmprSysU_D_Falt 3 "NotUsed" 2 "Pass" 1 "Fail" 0 "Not_Diagnose_Yet" ;
VAL_ 1041 ElCmprUHi_D_Stat 3 "Overvoltage" 2 "Undervoltage" 1 "InRange" 0 "Undetermined" ;
VAL_ 1041 ElCmprOverTe_D_Stat 3 "OverTempStop" 2 "OverTempWarning" 1 "Normal" 0 "Undefined" ;
VAL_ 1041 ElCmpr_N_Actl 255 "Invalid" ;
VAL_ 1041 ElCmpr_Pw_Actl 255 "Invalid" ;
VAL_ 1041 ElCmpr_D_Stat 7 "Signal_Invalid" 6 "Comp_Off_ActlSpd_Abnormal" 5 "Comp_Off_TrgtSpd_OutRange" 4 "Comp_Shutdown" 3 "Comp_Stopped_Self_Protect" 2 "Comp_Degraded" 1 "Comp_On" 0 "Comp_Off" ;
VAL_ 557 AudioToneTouchY_D_Stat 255 "Value254" 2 "Value1_up_to_0xFE_Value253" 1 "Value0" 0 "Null" ;
VAL_ 557 AudioToneTouchX_D_Stat 255 "Value254" 2 "Value1_up_to_0xFE_Value253" 1 "Value0" 0 "Null" ;
VAL_ 557 AudioToneTouch_D_Stat 3 "NotUsed" 2 "Enabled" 1 "Disabled" 0 "Null" ;
VAL_ 1236 ApaSlotRight3_D_Stat 7 "NotUsed_3" 6 "NotUsed_2" 5 "NotUsed_1" 4 "IPeReady" 3 "IPeFound" 2 "IPaReady" 1 "IPaFound" 0 "None" ;
VAL_ 1236 ApaSlotRight3_B_Altr 1 "Available" 0 "NotAvailable" ;
VAL_ 1236 ApaSlotRight2_D_Stat 7 "NotUsed_3" 6 "NotUsed_2" 5 "NotUsed_1" 4 "IPeReady" 3 "IPeFound" 2 "IPaReady" 1 "IPaFound" 0 "None" ;
VAL_ 1236 ApaSlotRight2_B_Altr 1 "Available" 0 "NotAvailable" ;
VAL_ 1236 ApaSlotRight1_D_Stat 7 "NotUsed_3" 6 "NotUsed_2" 5 "NotUsed_1" 4 "IPeReady" 3 "IPeFound" 2 "IPaReady" 1 "IPaFound" 0 "None" ;
VAL_ 1236 ApaSlotRight1_B_Altr 1 "Available" 0 "NotAvailable" ;
VAL_ 1236 ApaSlotRear_D_Stat 1 "True" 0 "False" ;
VAL_ 1235 ApaSlotFront_D_Stat 1 "True" 0 "False" ;
VAL_ 1235 ApaSlotLeft3_D_Stat 7 "NotUsed_3" 6 "NotUsed_2" 5 "NotUsed_1" 4 "IPeReady" 3 "IPeFound" 2 "IPaReady" 1 "IPaFound" 0 "None" ;
VAL_ 1235 ApaSlotLeft3_B_Altr 1 "Available" 0 "NotAvailable" ;
VAL_ 1235 ApaSlotLeft2_D_Stat 7 "NotUsed_3" 6 "NotUsed_2" 5 "NotUsed_1" 4 "IPeReady" 3 "IPeFound" 2 "IPaReady" 1 "IPaFound" 0 "None" ;
VAL_ 1235 ApaSlotLeft2_B_Altr 1 "Unavailable" 0 "Available" ;
VAL_ 1235 ApaSlotLeft1_D_Stat 7 "NotUsed_3" 6 "NotUsed_2" 5 "NotUsed_1" 4 "IPeReady" 3 "IPeFound" 2 "IPaReady" 1 "IPaFound" 0 "None" ;
VAL_ 1235 ApaSlotLeft1_B_Altr 1 "Unavailable" 0 "Available" ;
VAL_ 1234 RmtCtlSnsBlckg_B_Stat 1 "Yes" 0 "No" ;
VAL_ 1234 RmtCtlConfgSrc_D_Stat 7 "NotUsed_2" 6 "NotUsed_1" 5 "BPO" 4 "ApaHmi" 3 "FAP_Handover" 2 "User" 1 "None" 0 "NotDetermined" ;
VAL_ 1234 RmtCtlTrjctry_D_Avail 3 "NotUsed" 2 "Available" 1 "NotAvailable" 0 "Null" ;
VAL_ 1234 RmtCtlSns_D_Err 1 "Yes" 0 "No" ;
VAL_ 1234 RmtCtlPathPlan_D_Stat 7 "NotUsed_3" 6 "NotUsed_2" 5 "NotUsed_1" 4 "FinishedMovesExceeded" 3 "FinishedDistanceExceeded" 2 "Finished" 1 "Ongoing" 0 "None" ;
VAL_ 1234 RmtCtlPathPlan_B_Err 1 "Yes" 0 "No" ;
VAL_ 1234 RmtCtlAdas_D_Stat 7 "Paused" 6 "Abort" 5 "ManeuverFinished" 4 "EndPositionReached" 3 "Backward" 2 "Forward" 1 "ManeuverBegin" 0 "Inactive" ;
VAL_ 1234 RmtCtlAdas_B_Err 1 "Yes" 0 "No" ;
VAL_ 976 VehLong2_A_Actl_UB 1 "Fresh_data" 0 "Unchanged_data" ;
VAL_ 976 VehLong2_A_Actl 8191 "Faulty" 8190 "NoDataExists" ;
VAL_ 898 SecondRowBcklPsngrMid 3 "Unknown" 2 "Unbelted" 1 "Belted" 0 "Faulty" ;
VAL_ 898 SecondRowBuckleDrvMid 3 "Unknown" 2 "Unbelted" 1 "Belted" 0 "Faulty" ;
VAL_ 898 FourthRowBucklePsngr 3 "Unknown" 2 "Unbelted" 1 "Belted" 0 "Faulty" ;
VAL_ 898 FourthRowBuckleMid 3 "Unknown" 2 "Unbelted" 1 "Belted" 0 "Faulty" ;
VAL_ 898 FourthRowBuckleDriver 3 "Unknown" 2 "Unbelted" 1 "Belted" 0 "Faulty" ;
VAL_ 898 Row3PsngrPrsnc_D_Actl 3 "Unknown" 2 "Empty" 1 "Occupied" 0 "Fault" ;
VAL_ 898 Row3MidPrsnc_D_Actl 3 "Unknown" 2 "Empty" 1 "Occupied" 0 "Fault" ;
VAL_ 898 Row3DrvPrsnc_D_Actl 3 "Unknown" 2 "Empty" 1 "Occupied" 0 "Fault" ;
VAL_ 898 Row2PsngrPrsnc_D_Actl 3 "Unknown" 2 "Empty" 1 "Occupied" 0 "Fault" ;
VAL_ 898 Row2MidPrsnc_D_Actl 3 "Unknown" 2 "Empty" 1 "Occupied" 0 "Fault" ;
VAL_ 898 Row2DrvPrsnc_D_Actl 3 "Unknown" 2 "Empty" 1 "Occupied" 0 "Fault" ;
VAL_ 925 VehElEffTrip_No_Dsply 127 "Faulty" 126 "NoDataExists" ;
VAL_ 925 TripSumDrvE_Pc_Dsply 1023 "Faulty" 1022 "NoDataExists" ;
VAL_ 925 TripExtFctrE_Pc_Dsply 1023 "Faulty" 1022 "NoDataExists" ;
VAL_ 925 TripClimE_Pc_Dsply 1023 "Faulty" 1022 "NoDataExists" ;
VAL_ 925 TripBattULoE_Pc_Dsply 1023 "Faulty" 1022 "NoDataExists" ;
VAL_ 473 NAV_StorePreset2_Rq 31 "Reserved" 30 "Preset30" 29 "Preset29" 28 "Preset28" 27 "Preset27" 26 "Preset26" 25 "Preset25" 24 "Preset24" 23 "Preset23" 22 "Preset22" 21 "Preset21" 20 "Preset20" 19 "Preset19" 18 "Preset18" 17 "Preset17" 16 "Preset16" 15 "Preset15" 14 "Preset14" 13 "Preset13" 12 "Preset12" 11 "Preset11" 10 "Preset10" 9 "Preset9" 8 "Preset8" 7 "Preset7" 6 "Preset6" 5 "Preset5" 4 "Preset4" 3 "Preset3" 2 "Preset2" 1 "Preset1" 0 "Inactive" ;
VAL_ 473 NAV_SetAFMode_Rq 0 "Inactive" 1 "AfOn" 2 "AfOff" 3 "Auto" ;
VAL_ 473 NAV_StorePreset_Rq 10 "Preset10" 9 "Preset9" 8 "Preset8" 7 "Preset7" 0 "Inactive" 1 "Preset1" 2 "Preset2" 3 "Preset3" 4 "Preset4" 5 "Preset5" 6 "Preset6" ;
VAL_ 473 HMI_StorePreset2_Rq 31 "Reserved" 30 "Preset30" 29 "Preset29" 28 "Preset28" 27 "Preset27" 26 "Preset26" 25 "Preset25" 24 "Preset24" 23 "Preset23" 22 "Preset22" 21 "Preset21" 20 "Preset20" 19 "Preset19" 18 "Preset18" 17 "Preset17" 16 "Preset16" 15 "Preset15" 14 "Preset14" 13 "Preset13" 12 "Preset12" 11 "Preset11" 10 "Preset10" 9 "Preset9" 8 "Preset8" 7 "Preset7" 6 "Preset6" 5 "Preset5" 4 "Preset4" 3 "Preset3" 2 "Preset2" 1 "Preset1" 0 "Inactive" ;
VAL_ 473 NAV_SetTUServiceLink_Rq 3 "reserved" 2 "Inactive" 1 "Active" 0 "Invalid" ;
VAL_ 473 NAV_SetTAMode_Rq 0 "Inactive" 1 "TaLocalOn" 2 "TaDistantOn" 3 "TaOff" ;
VAL_ 473 NAV_SetReg_Rq 2 "On" 1 "Off" 0 "Inactive" ;
VAL_ 473 NAV_SelectPTYCodeSet_Rq 0 "Inactive" 1 "SetCode" ;
VAL_ 473 NAV_CDSetShuffle_Rq 0 "Inactive" 1 "On" 2 "Off" 3 "OnFolder" ;
VAL_ 473 NAV_CDSetRepeat_Rq 0 "Inactive" 1 "RepeatOnTrack" 2 "Off" 3 "OnFolder" ;
VAL_ 473 NAV_CDSetIntroScan_Rq 0 "Inactive" 1 "On" 2 "Off" 3 "OnFolder" ;
VAL_ 810 ExtLghtDsply_B_StatArb 1 "On" 0 "Off" ;
VAL_ 810 OneTEditActv_B_RqCld 1 "Yes" 0 "No" ;
VAL_ 482 SDARS_Firm_Update2_St 0 "Invalid" 2 "Active" 1 "Inactive" ;
VAL_ 482 SDARS_UnSubscrb_Chan2_St 0 "Invalid" 2 "Active" 1 "Inactive" ;
VAL_ 482 SDARS_UnSubscrb2_St 0 "Invalid" 2 "Active" 1 "Inactive" ;
VAL_ 482 SDARS_Subscription2_St 0 "Invalid" 2 "Active" 1 "Inactive" ;
VAL_ 482 SDARS_Seek_Scan2_St 1 "NoChannelsAvailable" 0 "Invalid" ;
VAL_ 482 SDARS_Receive_Err2_St 0 "Invalid" 2 "Active" 1 "Inactive" ;
VAL_ 482 SDARS_Loss_Ant2_St 0 "Invalid" 2 "Active" 1 "Inactive" ;
VAL_ 482 SDARS_Invalid_Chan2_St 0 "Invalid" 2 "Active" 1 "Inactive" ;
VAL_ 482 SDARS_GCI_Update2_St 0 "Invalid" 2 "Active" 1 "Inactive" ;
VAL_ 482 SDARS_Error_Conf2_St 0 "Invalid" 2 "SDARS_OFF" 1 "SDARS_ON" ;
VAL_ 482 SDARS_Antenna_Err2_St 0 "Invalid" 2 "Active" 1 "Inactive" ;
VAL_ 764 SdarsSampleRate_D_Stat 3 "NotUsed_1" 2 "SampleRate_48000Hz" 1 "SampleRate_44100Hz" 0 "Null" ;
VAL_ 764 SdarsBaudRate_D_Stat 7 "NotUsed_3" 6 "NotUsed_2" 5 "NotUsed_1" 4 "BaudRate_460800bps" 3 "BaudRate_230400bps" 2 "BaudRate_115200bps" 1 "BaudRate_57600bps" 0 "Null" ;
VAL_ 764 SDARS_ChannelUpdate_St 3 "NotUsed_1" 2 "NewUpdatesAvailable" 1 "NoUpdates" 0 "Inactive" ;
VAL_ 764 SDARS_Channel_Lock2 0 "Invalid" 2 "Unlocked" 1 "Locked" ;
VAL_ 628 CamraRearBttn_D_Stat_UB 1 "Fresh_data" 0 "Unchanged_data" ;
VAL_ 628 CamraRearBttn_D_Stat 1 "Pressed" 0 "Not_Pressed" ;
VAL_ 628 GearEngag_D_Actl_UB 1 "Fresh_data" 0 "Unchanged_data" ;
VAL_ 628 GearEngag_D_Actl 7 "Undefined" 6 "Fwd_Clutch_Fully_Engaged" 5 "Neutral_Idle" 4 "Disengaged_to_Neutral_Idle" 3 "Disengaged_to_Neutral_Park" 2 "Engagement_in_Progress" 1 "InitializeFwdClutchEngagmt" 0 "Park_Neutral" ;
VAL_ 628 RvltnMatchAllw_D_Stat_UB 1 "Fresh_data" 0 "Unchanged_data" ;
VAL_ 628 RvltnMatchAllw_D_Stat 3 "RevolutionMatchDisabled" 2 "RevolutionMatchEnabled" 1 "ChangeWithDriveMode" 0 "NoSelection" ;
VAL_ 628 SeatScrnPsngrOn_B_Rq 1 "On" 0 "Off" ;
VAL_ 628 SeatScrnPsngrOn_B_Rq_UB 1 "Fresh_data" 0 "Unchanged_data" ;
VAL_ 628 CamraRearOn_B_RqBalrl_UB 1 "Fresh_data" 0 "Unchanged_data" ;
VAL_ 628 CamraRearOn_B_RqBalrr_UB 1 "Fresh_data" 0 "Unchanged_data" ;
VAL_ 628 CamraRearOn_B_RqBalrr 1 "Active" 0 "Inactive" ;
VAL_ 628 CamraRearOn_B_RqBalrl 1 "Active" 0 "Inactive" ;
VAL_ 628 PwFlwFuelDrv_D_Dsply 7 "NotUsed_4" 6 "NotUsed_3" 5 "NotUsed_2" 4 "NotUsed_1" 3 "FlwFromFuelToAllWhls" 2 "FlwFromFuelToFrontWhls" 1 "FlwFromFuelToRearWhls" 0 "NoFlow" ;
VAL_ 628 PwFlwFuelClimt_B_Dsply 1 "On" 0 "Off" ;
VAL_ 628 PwFlwFuelBatt_B_Dsply 1 "On" 0 "Off" ;
VAL_ 628 PwFlwBattGen_D_Dsply 1 "On" 0 "Off" ;
VAL_ 628 PwFlwBattClimt_B_Dsply 1 "On" 0 "Off" ;
VAL_ 628 PwFlwBatt_D_Dsply 15 "NotUsed_8" 14 "NotUsed_7" 13 "NotUsed_6" 12 "NotUsed_5" 11 "NotUsed_4" 10 "NotUsed_3" 9 "NotUsed_2" 8 "NotUsed_1" 7 "FlwFromWallToBatt" 6 "FlwFromAllWhlsToBatt" 5 "FlwFromBattToAllWhls" 4 "FlwFromFrontWhlsToBatt" 3 "FlwFromBattToFrontWhls" 2 "FlwFromRearWhlsToBatt" 1 "FlwFromBattToRearWhls" 0 "NoFlow" ;
VAL_ 628 PwFlwFuelDrv_D_Dsply_UB 1 "Fresh_data" 0 "Unchanged_data" ;
VAL_ 628 PwFlwFuelClimt_B_Dsply_UB 1 "Fresh_data" 0 "Unchanged_data" ;
VAL_ 628 PwFlwFuelBatt_B_Dsply_UB 1 "Fresh_data" 0 "Unchanged_data" ;
VAL_ 628 PwFlwBattGen_D_Dsply_UB 1 "Fresh_data" 0 "Unchanged_data" ;
VAL_ 628 PwFlwBattClimt_B_Dsply_UB 1 "Fresh_data" 0 "Unchanged_data" ;
VAL_ 628 PwFlwBatt_D_Dsply_UB 1 "Fresh_data" 0 "Unchanged_data" ;
VAL_ 628 TrailCtlMsgTxt_D_Rq 15 "Message15" 14 "Message14" 13 "Message13" 12 "Message12" 11 "Message11" 10 "Message10" 9 "Message9" 8 "Message8" 7 "Message7" 6 "Message6" 5 "Message5" 4 "Message4" 3 "Message3" 2 "Message2" 1 "Message1" 0 "NoMessage" ;
VAL_ 628 TrailCtlMsgTxt_D_Rq_UB 1 "Fresh_data" 0 "Unchanged_data" ;
VAL_ 628 TrailCtl_D_Stat_UB 1 "Fresh_data" 0 "Unchanged_data" ;
VAL_ 628 TrailCtl_D_Stat 7 "Faulty" 6 "DescentOnly" 5 "EnabledDeny" 4 "StandbyOverThreshold" 3 "StandbyOverride" 2 "Active" 1 "EnabledDescent" 0 "Off" ;
VAL_ 628 Veh_V_DsplyTrailCtlSet 63 "Faulty" ;
VAL_ 628 Veh_V_DsplyTrailCtlSet_UB 1 "Fresh_data" 0 "Unchanged_data" ;
VAL_ 628 SeatScrnDrvOn_B_Rq_UB 1 "Fresh_data" 0 "Unchanged_data" ;
VAL_ 628 SeatScrnDrvOn_B_Rq 1 "On" 0 "Off" ;
VAL_ 770 BattTracVrtOck_B_Stat 1 "Yes" 0 "No" ;
VAL_ 770 ScPayloadUpdate_B_Stat 3 "NotUsed" 2 "Complete" 1 "InProcess" 0 "Null" ;
VAL_ 770 ScChrgrPwMax_Pw_Actl 4095 "Faulty" ;
VAL_ 770 ScEnbl_B_Stat 1 "On" 0 "Off" ;
VAL_ 785 VehVLimMsgTxt_B_Rq 1 "Yes" 0 "No" ;
VAL_ 785 BattElecPerf_D2_Actl 7 "NotUsed" 6 "SeverelyLimitedPerformance" 5 "LimitedPerformance" 4 "SeverelyLimPerf_MotorTe" 3 "LimitedPerf_MotorTe" 2 "SeverelyLimPerf_BatteryTe" 1 "LimitedPerf_BatteryTe" 0 "NoMessage" ;
VAL_ 785 RgenAnimation_B_Dsply 1 "Active" 0 "Inactive" ;
VAL_ 785 BattTracLimPerf_D_Dsply 3 "NotUsed" 2 "SeverelyLimitedPerformance" 1 "LimitedPerformance" 0 "NoDisplay" ;
VAL_ 785 EcoIdl_D_Stat 3 "NotUsed" 2 "Enabled" 1 "Disabled" 0 "Null" ;
VAL_ 785 DteVehOffst_L_Dsply 8191 "Faulty" 8190 "NoDataExists" ;
VAL_ 785 DteVehOffstMsgTxt_D_Rq 15 "NotUsed_7" 14 "NotUsed_6" 13 "NotUsed_5" 12 "NotUsed_4" 11 "NotUsed_3" 10 "NotUsed_2" 9 "NotUsed_1" 8 "PowerToTheBox" 7 "Payload" 6 "TrailerTowing_Off" 5 "TrailerTowing_On" 4 "TrafficAlongRoute" 3 "ExternalTemperature" 2 "HillyTerrain" 1 "DestinationRoute" 0 "NoMessage" ;
VAL_ 785 PwPckTqRdyChime_B_Rq 3 "NotUsed" 2 "Shutdown" 1 "Startup" 0 "Null" ;
VAL_ 785 BattTracLoThres_D_Stat 7 "NotUsed" 6 "Thres80km_50mi" 5 "Thres50km_31mi" 4 "Thres30km_18mi" 3 "Thres50mi_80km" 2 "Thres30mi_48km" 1 "Thres20mi_32km" 0 "Null" ;
VAL_ 785 BattTracLoMsgTxt_D_Rq 7 "NotUsed_2" 6 "NotUsed_1" 5 "ZeroDteBatteryDepleted" 4 "ClimateLowDteSecondAlert" 3 "ClimateLowDteFirstAlert" 2 "LowDteSecondAlert" 1 "LowDteFirstAlert" 0 "Null" ;
VAL_ 785 BattTracLoSoc_D_Dsply 3 "NotUsed" 2 "ZeroDteDepletedBattery" 1 "LoDte" 0 "Null" ;
VAL_ 391 ACU_CtrlChimeChan_Rq 3 "Reserved2" 2 "Reserved1" 1 "Mute" 0 "Inactive" ;
VAL_ 415 LBC3_Opcode 3 "NotUsed" 2 "SetItemIfno_Rq" 1 "GetItemInfo_Rq" 0 "Inactive" ;
VAL_ 501 Dsp_PresetArea_Rq 0 "Inactive" 1 "GetFm1PresetData" 2 "GetFm2PresetData" 3 "GetFm3PresetData" 4 "GetFmAstPresetData" 5 "GetAmAstPresetData" 6 "GetAmPresetData" 7 "GetFmStationListPresetData" ;
VAL_ 501 Dsp_SetRadSeekMode_Rq 15 "Reseved" 14 "ContAutoDown" 0 "Inactive" 1 "SeekOff" 2 "AutoUp" 3 "AutoDown" 4 "ManSingleStepUp" 5 "ManSingleStepDown" 6 "ContManualUp" 7 "ContManualDown" 8 "ScanUp" 9 "ScanDown" 10 "PtySeekUp" 11 "PtySeekDown" 12 "Autostore" 13 "ContAutoUp" ;
VAL_ 501 Dsp_SetCRadioBand_Rq 0 "Inactive" 1 "Fm1" 2 "Fm2" 3 "Fm3" 4 "FmAst" 5 "Am" 6 "AmAst" ;
VAL_ 501 Dsp_FreezeFMSL_Rq 3 "NotUsed" 2 "True" 1 "False" 0 "Inactive" ;
VAL_ 651 TelematicsSrvc_D_St 7 "NotUsed" 6 "NotifyNotActivatedYet" 5 "NotActivatedYet" 4 "NotifyExpired" 3 "Expired" 2 "ExpiringSoon" 1 "Active" 0 "Null" ;
VAL_ 651 EmgcyCallMute_D_Stat 7 "NotUsed4" 6 "NotUsed3" 5 "NotUsed2" 4 "NotUsed1" 3 "ManualEmergencyCallMute" 2 "AutomaticEmergencyCallMute" 1 "EmergencyCallUnmute" 0 "Null" ;
VAL_ 1098 EdmSailMdeOn_B_Stat 1 "On" 0 "Off" ;
VAL_ 1098 EdmMsgTxt_D_Rq 15 "NotUsed_4" 14 "NotUsed_3" 13 "NotUsed_2" 12 "NotUsed_1" 11 "OverallGoodScore" 10 "WorkOnCompliance" 9 "GoodCompliance" 8 "WorkOnGearShifting" 7 "GoodGearShifting" 6 "WorkOnEfficientSpeed" 5 "GoodEfficientSpeed" 4 "WorkOnDeceleration" 3 "GoodDeceleration" 2 "WorkOnAcceleration" 1 "GoodAcceleration" 0 "NoMessage" ;
VAL_ 1098 EdmLamp_D_Dsply 15 "NotUsed_7" 14 "NotUsed_6" 13 "NotUsed_5" 12 "NotUsed_4" 11 "NotUsed_3" 10 "NotUsed_2" 9 "NotUsed_1" 8 "CoastingEngineBrake" 7 "CoastingShiftToNeutral" 6 "FreewayJunction" 5 "Curve2" 4 "Curve1" 3 "SpeedLimit" 2 "Crossing" 1 "FreewayExit" 0 "NoRecommendation" ;
VAL_ 1098 EdmCmplnc_B_Dsply 1 "Yes" 0 "No" ;
VAL_ 629 GearPos_D_Actl_UB 1 "Fresh_data" 0 "Unchanged_data" ;
VAL_ 629 GearPos_D_Actl 15 "Unknown" 14 "Reverse" 13 "Undefined_5" 12 "Undefined_4" 11 "Undefined_3" 10 "Tenth" 9 "Ninth" 8 "Eighth" 7 "Seventh" 6 "Sixth" 5 "Fifth" 4 "Fourth" 3 "Third" 2 "Second" 1 "First" 0 "Neutral" ;
VAL_ 629 BattTrac2_E_Max_UB 1 "Fresh_data" 0 "Unchanged_data" ;
VAL_ 629 BattTrac2_E_Avail_UB 1 "Fresh_data" 0 "Unchanged_data" ;
VAL_ 629 BattTrac2_E_Max 4095 "Faulty" 4094 "NoDataExists" ;
VAL_ 629 BattTrac2_E_Avail 4095 "Faulty" 4094 "NoDataExists" ;
VAL_ 629 BattULoChrgHyb_D_Stat_UB 1 "Fresh_data" 0 "Unchanged_data" ;
VAL_ 629 TrnRng_D_Rq_UB 1 "Fresh_data" 0 "Unchanged_data" ;
VAL_ 629 TrnRng_D_Rq 15 "Fault" 14 "Unknown_Position" 13 "NotUsed_2" 12 "NotUsed_1" 11 "Range6" 10 "Range5" 9 "Range4" 8 "Range3_M3_L3" 7 "Range2_M2_L2" 6 "Range1_M1_L1" 5 "Low" 4 "Sport_DriveSport_Mposition" 3 "Drive" 2 "Neutral" 1 "Reverse" 0 "Park" ;
VAL_ 629 BattULoChrgHyb_D_Stat 7 "NotUsed_4" 6 "NotUsed_3" 5 "NotUsed_2" 4 "NotUsed_1" 3 "VehicleServiceRequired" 2 "EvRangeLossDueToLoadActive" 1 "BatteryServiceRequired" 0 "Null" ;
VAL_ 629 BattTracHazrd_D_Stat_UB 1 "Fresh_data" 0 "Unchanged_data" ;
VAL_ 629 BattTracHazrd_D_Stat 3 "Disabled" 2 "HazardConfirmed" 1 "ExternalMonitoringRequired" 0 "NoHazardDetected" ;
VAL_ 672 BCP_Audible_Beep_Rq 1 "Active" 0 "Inactive" ;
VAL_ 672 Coding_BtnID_D 1 "Pressed" 0 "Not_Pressed" ;
VAL_ 672 Coding_BtnID_C 1 "Pressed" 0 "Not_Pressed" ;
VAL_ 672 Coding_BtnID_B 1 "Pressed" 0 "Not_Pressed" ;
VAL_ 672 Coding_BtnID_A 1 "Pressed" 0 "Not_Pressed" ;
VAL_ 1205 CstmDrvMdeCfg2_B_Avail 1 "Available" 0 "NotAvailable" ;
VAL_ 1205 CstmDrvMdeCfg1_B_Avail 1 "Available" 0 "NotAvailable" ;
VAL_ 816 KeylessIdl_D_Rq 3 "Cancel" 2 "IgnitionOff" 1 "Active" 0 "Inactive" ;
VAL_ 816 KeyPadCodeDgt7_D_Stat 15 "NotUsed_4" 14 "NotUsed_3" 13 "NotUsed_2" 12 "NotUsed_1" 11 "Button7_8and9_0" 10 "Button0" 9 "Button9_0or9" 8 "Button8" 7 "Button7_8or7" 6 "Button6" 5 "Button5_6or5" 4 "Button4" 3 "Button3_4or3" 2 "Button2" 1 "Button1_2or1" 0 "EndofString" ;
VAL_ 816 KeyPadCodeDgt6_D_Stat 15 "NotUsed_4" 14 "NotUsed_3" 13 "NotUsed_2" 12 "NotUsed_1" 11 "Button7_8and9_0" 10 "Button0" 9 "Button9_0or9" 8 "Button8" 7 "Button7_8or7" 6 "Button6" 5 "Button5_6or5" 4 "Button4" 3 "Button3_4or3" 2 "Button2" 1 "Button1_2or1" 0 "EndofString" ;
VAL_ 816 KeyPadCodeDgt5_D_Stat 15 "NotUsed_4" 14 "NotUsed_3" 13 "NotUsed_2" 12 "NotUsed_1" 11 "Button7_8and9_0" 10 "Button0" 9 "Button9_0or9" 8 "Button8" 7 "Button7_8or7" 6 "Button6" 5 "Button5_6or5" 4 "Button4" 3 "Button3_4or3" 2 "Button2" 1 "Button1_2or1" 0 "EndofString" ;
VAL_ 816 KeyPadCodeDgt4_D_Stat 15 "NotUsed_4" 14 "NotUsed_3" 13 "NotUsed_2" 12 "NotUsed_1" 11 "Button7_8and9_0" 10 "Button0" 9 "Button9_0or9" 8 "Button8" 7 "Button7_8or7" 6 "Button6" 5 "Button5_6or5" 4 "Button4" 3 "Button3_4or3" 2 "Button2" 1 "Button1_2or1" 0 "EndofString" ;
VAL_ 816 KeyPadCodeDgt3_D_Stat 15 "NotUsed_4" 14 "NotUsed_3" 13 "NotUsed_2" 12 "NotUsed_1" 11 "Button7_8and9_0" 10 "Button0" 9 "Button9_0or9" 8 "Button8" 7 "Button7_8or7" 6 "Button6" 5 "Button5_6or5" 4 "Button4" 3 "Button3_4or3" 2 "Button2" 1 "Button1_2or1" 0 "EndofString" ;
VAL_ 816 KeyPadCodeDgt2_D_Stat 15 "NotUsed_4" 14 "NotUsed_3" 13 "NotUsed_2" 12 "NotUsed_1" 11 "Button7_8and9_0" 10 "Button0" 9 "Button9_0or9" 8 "Button8" 7 "Button7_8or7" 6 "Button6" 5 "Button5_6or5" 4 "Button4" 3 "Button3_4or3" 2 "Button2" 1 "Button1_2or1" 0 "EndofString" ;
VAL_ 816 KeyPadCodeDgt1_D_Stat 15 "NotUsed_4" 14 "NotUsed_3" 13 "NotUsed_2" 12 "NotUsed_1" 11 "Button7_8and9_0" 10 "Button0" 9 "Button9_0or9" 8 "Button8" 7 "Button7_8or7" 6 "Button6" 5 "Button5_6or5" 4 "Button4" 3 "Button3_4or3" 2 "Button2" 1 "Button1_2or1" 0 "EndofString" ;
VAL_ 816 CntrStk2_D_RqAssoc 7 "Unused_2" 6 "Cancel" 5 "Set_Keycode" 4 "RKE" 3 "Null" 2 "Key" 1 "Erase_KeyCode" 0 "Check_KeyCode" ;
VAL_ 636 WifiHtsptFqBand_D_Stat 3 "NotUsed_1" 2 "Band_2" 1 "Band_1" 0 "Null" ;
VAL_ 636 WifiHtspt_D_Falt 15 "Error15" 14 "Error14" 13 "Error13" 12 "Error12" 11 "Error11" 10 "Error10" 9 "Error9" 8 "Error8" 7 "Error7" 6 "Error6" 5 "Error5" 4 "Error4" 3 "Error3" 2 "Error2" 1 "Error1" 0 "Null" ;
VAL_ 636 WifiHtsptCnnct_D_Stat 3 "NotUsed" 2 "Connected" 1 "NotConnected" 0 "Null" ;
VAL_ 636 Telematics_D_Falt 7 "NotUsed_5" 6 "NotUsed_4" 5 "NotUsed_3" 4 "NotUsed_2" 3 "NotUsed_1" 2 "RunTimeError" 1 "ChipsetInitializationFailu" 0 "Null" ;
VAL_ 636 WifiEnbl_D_Stat 3 "NotUsed" 2 "Enable" 1 "Disable" 0 "Null" ;
VAL_ 636 WifiHtsptVisbl_D_Stat 3 "Not  used" 2 "On" 1 "Off" 0 "Null" ;
VAL_ 636 WifiHtsptScrty_D_Stat 3 "NotUsed_1" 2 "Wapi" 1 "Wpa2_Wpa" 0 "Null" ;
VAL_ 636 WifiHtsptEnbl_D_Stat 3 "OnDisabled" 2 "On" 1 "Off" 0 "Null" ;
VAL_ 636 WifiDevcListNew_B_Stat 1 "Available" 0 "NotAvailable" ;
VAL_ 636 WifiDataUsage_D_Stat 3 "PercentDataUsed" 2 "DataPlanExpired" 1 "FreeTrialPeriodWaiting" 0 "Null" ;
VAL_ 636 ModemSigStren_D_Stat 7 "NotUsed_1" 6 "NotDetermined" 5 "FiveBars" 4 "FourBars" 3 "ThreeBars" 2 "TwoBars" 1 "OneBar" 0 "ZeroBars" ;
VAL_ 636 ModemTechnology_D2_Stat 7 "Lte" 6 "HspaPlus" 5 "Umts" 4 "Edge" 3 "Gprs" 2 "Gsm" 1 "NoNetwork" 0 "Null" ;
VAL_ 636 WifiHtsptCrdntl_B_Stat 1 "Available" 0 "NotAvailable" ;
VAL_ 636 WifiHtsptFq_D_Avail 7 "NotUsed_3" 6 "NotUsed_2" 5 "NotUsed_1" 4 "AllAvailable" 3 "Band_2_Only" 2 "Band_1_Only" 1 "AllRestricted" 0 "Null" ;
VAL_ 636 WifiDataUsageOn_D_Stat 3 "NotUsed" 2 "On" 1 "Off" 0 "Null" ;
VAL_ 807 ElDistTripUnit_D_Stat 3 "NotUsed" 2 "Miles" 1 "Kilometers" 0 "Inactive" ;
VAL_ 807 ElDistTripCur_No_Dsply 0 "0 second" ;
VAL_ 974 EngExhMdeHrStrt_D_Stat 31 "NotUsed_7" 30 "NotUsed_6" 29 "NotUsed_5" 28 "NotUsed_4" 27 "NotUsed_3" 26 "NotUsed_2" 25 "NotUsed_1" 24 "Hour23_11pm" 23 "Hour22_10pm" 22 "Hour21_9pm" 21 "Hour20_8pm" 20 "Hour19_7pm" 19 "Hour18_6pm" 18 "Hour17_5pm" 17 "Hour16_4pm" 16 "Hour15_3pm" 15 "Hour14_2pm" 14 "Hour13_1pm" 13 "Hour12_12pm" 12 "Hour11_11am" 11 "Hour10_10am" 10 "Hour9_9am" 9 "Hour8_8am" 8 "Hour7_7am" 7 "Hour6_6am" 6 "Hour5_5am" 5 "Hour4_4am" 4 "Hour3_3am" 3 "Hour2_2am" 2 "Hour1_1am" 1 "Hour0_12am" 0 "Null" ;
VAL_ 974 EngExhMdeHrEnd_D_Stat 31 "NotUsed_7" 30 "NotUsed_6" 29 "NotUsed_5" 28 "NotUsed_4" 27 "NotUsed_3" 26 "NotUsed_2" 25 "NotUsed_1" 24 "Hour23_11pm" 23 "Hour22_10pm" 22 "Hour21_9pm" 21 "Hour20_8pm" 20 "Hour19_7pm" 19 "Hour18_6pm" 18 "Hour17_5pm" 17 "Hour16_4pm" 16 "Hour15_3pm" 15 "Hour14_2pm" 14 "Hour13_1pm" 13 "Hour12_12pm" 12 "Hour11_11am" 11 "Hour10_10am" 10 "Hour9_9am" 9 "Hour8_8am" 8 "Hour7_7am" 7 "Hour6_6am" 6 "Hour5_5am" 5 "Hour4_4am" 4 "Hour3_3am" 3 "Hour2_2am" 2 "Hour1_1am" 1 "Hour0_12am" 0 "Null" ;
VAL_ 974 EngExhMdeHrEnbl_D_Stat 3 "NotUsed" 2 "Enabled" 1 "Disabled" 0 "Null" ;
VAL_ 974 DcacOut_Pw_DsplyMx 1023 "Faulty" ;
VAL_ 974 DcacOut1_Pw_Dsply 63 "Faulty" ;
VAL_ 974 DcacOut2_Pw_Dsply 63 "Faulty" ;
VAL_ 974 DcacHw_D_Confg 15 "NotUsed_11" 14 "NotUsed_10" 13 "NotUsed_9" 12 "NotUsed_8" 11 "NotUsed_7" 10 "NotUsed_6" 9 "NotUsed_5" 8 "NotUsed_4" 7 "NotUsed_3" 6 "NotUsed_2" 5 "NotUsed_1" 4 "Power_2300W" 3 "Power_7200W" 2 "Power_2400W" 1 "Power_2000W" 0 "NoDcacHardware" ;
VAL_ 974 DcacFaltMsgTxt_D_Rq 15 "HvacOn" 14 "OvercurrentLP" 13 "EngineRun" 12 "Service" 11 "NotAvailable" 10 "PlugWarn" 9 "PlugWarnDrive" 8 "BreakerC" 7 "BreakerB" 6 "BreakerA" 5 "FuelLow" 4 "AcOnOutput" 3 "Temperature" 2 "Gfci" 1 "Overcurrent" 0 "Ok" ;
VAL_ 974 DcacLoFuelMsgTxt_D_Rq 31 "Minute_31" 30 "Minute_30" 29 "Minute_29" 28 "Minute_28" 27 "Minute_27" 26 "Minute_26" 25 "Minute_25" 24 "Minute_24" 23 "Minute_23" 22 "Minute_22" 21 "Minute_21" 20 "Minute_20" 19 "Minute_19" 18 "Minute_18" 17 "Minute_17" 16 "Minute_16" 15 "Minute_15" 14 "Minute_14" 13 "Minute_13" 12 "Minute_12" 11 "Minute_11" 10 "Minute_10" 9 "Minute_9" 8 "Minute_8" 7 "Minute_7" 6 "Minute_6" 5 "Minute_5" 4 "Minute_4" 3 "Minute_3" 2 "Minute_2" 1 "Minute_1" 0 "Ok" ;
VAL_ 974 DcacEngOnMsgTxt_D_Rq 3 "NotUsed" 2 "DisplayQuestion" 1 "DisplayWarning" 0 "Ok" ;
VAL_ 974 DcacElPw_D_Stat 3 "NotUsed" 2 "High" 1 "Low" 0 "Off" ;
VAL_ 974 PwBedPnlEnbl_B_Rq 1 "Enable" 0 "Disable" ;
VAL_ 974 DcacOn_B_Rq 1 "Enable" 0 "Disable" ;
VAL_ 974 DcacSys_B_Falt 1 "Yes" 0 "No" ;
VAL_ 974 DcacLedCtl_D_Rq 3 "Fast_Flash" 2 "Slow_Flash" 1 "On" 0 "Off" ;
VAL_ 805 InstFeTripUnit_D_Stat 15 "NotUsed_12" 14 "NotUsed_11" 13 "NotUsed_10" 12 "NotUsed_9" 11 "NotUsed_8" 10 "NotUsed_7" 9 "NotUsed_6" 8 "NotUsed_5" 7 "NotUsed_4" 6 "NotUsed_3" 5 "NotUsed_2" 4 "NotUsed_1" 3 "LiterPer100kilometer" 2 "KilometerPerLiter" 1 "MilePerGallon" 0 "Inactive" ;
